AUTOSAR XML (schema 00054)
package /AUTOSAR/Platform/BaseTypes
  7 x base type, all with category=FIXED_LENGTH:
    boolean_bt: base-type-size=8, base-type-encoding=BOOLEAN
    uint8_bt: base-type-size=8, base-type-encoding=NONE
    uint16_bt: base-type-size=16, base-type-encoding=NONE
    uint32_bt: base-type-size=32, base-type-encoding=NONE
    sint8_bt: base-type-size=8, base-type-encoding=2C
    sint16_bt: base-type-size=16, base-type-encoding=2C
    sint32_bt: base-type-size=32, base-type-encoding=2C
package /AUTOSAR/Platform/ImplementationDataTypes
  7 x impl type, all with category=VALUE:
    boolean_T: base-type=boolean_bt
    uint8_T: base-type=uint8_bt
    uint16_T: base-type=uint16_bt
    uint32_T: base-type=uint32_bt
    sint8_T: base-type=sint8_bt
    sint16_T: base-type=sint16_bt
    sint32_T: base-type=sint32_bt
package /Taktflow/System
  system TaktflowSystem: category=SYSTEM_EXTRACT
package /Taktflow/Communication
  can cluster CAN_500k: baudrate=500000, protocol-name=CAN
    can physical channel CAN_Physical: comm-connectors=[CVC_Conn, FZC_Conn, RZC_Conn, SC_Conn, BCM_Conn, ICU_Conn, TCU_Conn, Diag_Conn]
      frame EStop_Broadcast_Frame: id 0x1, frame-length=4, can-addressing-mode=STANDARD, can-frame-rx-behavior=CAN-20, can-frame-tx-behavior=CAN-20
        pdu EStop_Broadcast: length=4, transmission-mode-true-timing=cyclic-timing=time-period=0.01
          signal EStop_Broadcast_E2E_DataID: start 0, 4 bit, little-endian, data-type-policy=OVERRIDE, transfer-property=PENDING
          signal EStop_Broadcast_E2E_AliveCounter: start 4, 4 bit, little-endian, data-type-policy=OVERRIDE, transfer-property=PENDING
          signal EStop_Broadcast_E2E_CRC8: start 8, 8 bit, little-endian, data-type-policy=OVERRIDE, transfer-property=PENDING
          signal EStop_Broadcast_Active: start 16, 8 bit, little-endian, data-type-policy=OVERRIDE, transfer-property=PENDING
          signal EStop_Broadcast_Source: start 24, 8 bit, little-endian, data-type-policy=OVERRIDE, transfer-property=PENDING
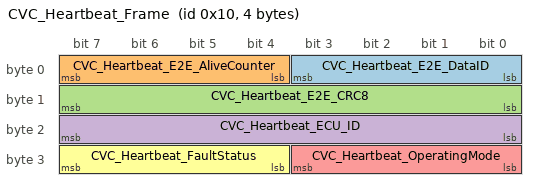
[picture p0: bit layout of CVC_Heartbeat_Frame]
      frame CVC_Heartbeat_Frame: id 0x10, frame-length=4, can-addressing-mode=STANDARD, can-frame-rx-behavior=CAN-20, can-frame-tx-behavior=CAN-20
        pdu CVC_Heartbeat: length=4, transmission-mode-true-timing=cyclic-timing=time-period=0.05
          signal CVC_Heartbeat_E2E_DataID: start 0, 4 bit, little-endian, data-type-policy=OVERRIDE, transfer-property=PENDING
          signal CVC_Heartbeat_E2E_AliveCounter: start 4, 4 bit, little-endian, data-type-policy=OVERRIDE, transfer-property=PENDING
          signal CVC_Heartbeat_E2E_CRC8: start 8, 8 bit, little-endian, data-type-policy=OVERRIDE, transfer-property=PENDING
          signal CVC_Heartbeat_ECU_ID: start 16, 8 bit, little-endian, data-type-policy=OVERRIDE, transfer-property=PENDING
          signal CVC_Heartbeat_OperatingMode: start 24, 4 bit, little-endian, data-type-policy=OVERRIDE, transfer-property=PENDING
          signal CVC_Heartbeat_FaultStatus: start 28, 4 bit, little-endian, data-type-policy=OVERRIDE, transfer-property=PENDING
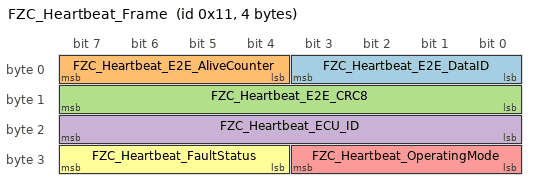
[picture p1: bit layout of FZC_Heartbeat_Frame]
      frame FZC_Heartbeat_Frame: id 0x11, frame-length=4, can-addressing-mode=STANDARD, can-frame-rx-behavior=CAN-20, can-frame-tx-behavior=CAN-20
        pdu FZC_Heartbeat: length=4, transmission-mode-true-timing=cyclic-timing=time-period=0.05
          signal FZC_Heartbeat_E2E_DataID: start 0, 4 bit, little-endian, data-type-policy=OVERRIDE, transfer-property=PENDING
          signal FZC_Heartbeat_E2E_AliveCounter: start 4, 4 bit, little-endian, data-type-policy=OVERRIDE, transfer-property=PENDING
          signal FZC_Heartbeat_E2E_CRC8: start 8, 8 bit, little-endian, data-type-policy=OVERRIDE, transfer-property=PENDING
          signal FZC_Heartbeat_ECU_ID: start 16, 8 bit, little-endian, data-type-policy=OVERRIDE, transfer-property=PENDING
          signal FZC_Heartbeat_OperatingMode: start 24, 4 bit, little-endian, data-type-policy=OVERRIDE, transfer-property=PENDING
          signal FZC_Heartbeat_FaultStatus: start 28, 4 bit, little-endian, data-type-policy=OVERRIDE, transfer-property=PENDING
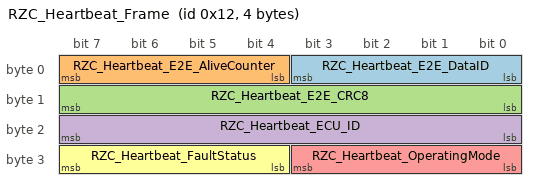
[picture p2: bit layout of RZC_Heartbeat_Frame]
      frame RZC_Heartbeat_Frame: id 0x12, frame-length=4, can-addressing-mode=STANDARD, can-frame-rx-behavior=CAN-20, can-frame-tx-behavior=CAN-20
        pdu RZC_Heartbeat: length=4, transmission-mode-true-timing=cyclic-timing=time-period=0.05
          signal RZC_Heartbeat_E2E_DataID: start 0, 4 bit, little-endian, data-type-policy=OVERRIDE, transfer-property=PENDING
          signal RZC_Heartbeat_E2E_AliveCounter: start 4, 4 bit, little-endian, data-type-policy=OVERRIDE, transfer-property=PENDING
          signal RZC_Heartbeat_E2E_CRC8: start 8, 8 bit, little-endian, data-type-policy=OVERRIDE, transfer-property=PENDING
          signal RZC_Heartbeat_ECU_ID: start 16, 8 bit, little-endian, data-type-policy=OVERRIDE, transfer-property=PENDING
          signal RZC_Heartbeat_OperatingMode: start 24, 4 bit, little-endian, data-type-policy=OVERRIDE, transfer-property=PENDING
          signal RZC_Heartbeat_FaultStatus: start 28, 4 bit, little-endian, data-type-policy=OVERRIDE, transfer-property=PENDING
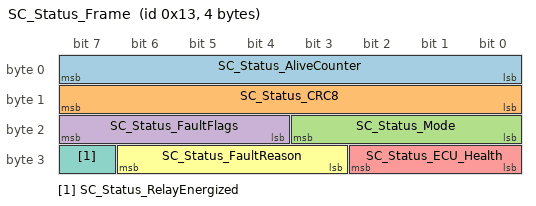
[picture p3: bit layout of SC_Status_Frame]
      frame SC_Status_Frame: id 0x13, frame-length=4, can-addressing-mode=STANDARD, can-frame-rx-behavior=CAN-20, can-frame-tx-behavior=CAN-20
        pdu SC_Status: length=4, transmission-mode-true-timing=cyclic-timing=time-period=0.1
          signal SC_Status_AliveCounter: start 0, 8 bit, little-endian, data-type-policy=OVERRIDE, transfer-property=PENDING
          signal SC_Status_CRC8: start 8, 8 bit, little-endian, data-type-policy=OVERRIDE, transfer-property=PENDING
          signal SC_Status_Mode: start 16, 4 bit, little-endian, data-type-policy=OVERRIDE, transfer-property=PENDING
          signal SC_Status_FaultFlags: start 20, 4 bit, little-endian, data-type-policy=OVERRIDE, transfer-property=PENDING
          signal SC_Status_ECU_Health: start 24, 3 bit, little-endian, data-type-policy=OVERRIDE, transfer-property=PENDING
          signal SC_Status_FaultReason: start 27, 4 bit, little-endian, data-type-policy=OVERRIDE, transfer-property=PENDING
          signal SC_Status_RelayEnergized: start 31, 1 bit, little-endian, data-type-policy=OVERRIDE, transfer-property=PENDING
      frame ICU_Heartbeat_Frame: id 0x14, frame-length=4, can-addressing-mode=STANDARD, can-frame-rx-behavior=CAN-20, can-frame-tx-behavior=CAN-20
        pdu ICU_Heartbeat: length=4, transmission-mode-true-timing=cyclic-timing=time-period=0.5
          signal ICU_Heartbeat_E2E_DataID: start 0, 4 bit, little-endian, data-type-policy=OVERRIDE, transfer-property=PENDING
          signal ICU_Heartbeat_E2E_AliveCounter: start 4, 4 bit, little-endian, data-type-policy=OVERRIDE, transfer-property=PENDING
          signal ICU_Heartbeat_E2E_CRC8: start 8, 8 bit, little-endian, data-type-policy=OVERRIDE, transfer-property=PENDING
          signal ICU_Heartbeat_AliveCounter: start 16, 8 bit, little-endian, data-type-policy=OVERRIDE, transfer-property=PENDING
          signal ICU_Heartbeat_ECU_ID: start 24, 8 bit, little-endian, data-type-policy=OVERRIDE, transfer-property=PENDING
      frame TCU_Heartbeat_Frame: id 0x15, frame-length=4, can-addressing-mode=STANDARD, can-frame-rx-behavior=CAN-20, can-frame-tx-behavior=CAN-20
        pdu TCU_Heartbeat: length=4, transmission-mode-true-timing=cyclic-timing=time-period=0.5
          signal TCU_Heartbeat_E2E_DataID: start 0, 4 bit, little-endian, data-type-policy=OVERRIDE, transfer-property=PENDING
          signal TCU_Heartbeat_E2E_AliveCounter: start 4, 4 bit, little-endian, data-type-policy=OVERRIDE, transfer-property=PENDING
          signal TCU_Heartbeat_E2E_CRC8: start 8, 8 bit, little-endian, data-type-policy=OVERRIDE, transfer-property=PENDING
          signal TCU_Heartbeat_AliveCounter: start 16, 8 bit, little-endian, data-type-policy=OVERRIDE, transfer-property=PENDING
          signal TCU_Heartbeat_ECU_ID: start 24, 8 bit, little-endian, data-type-policy=OVERRIDE, transfer-property=PENDING
      frame BCM_Heartbeat_Frame: id 0x16, frame-length=4, can-addressing-mode=STANDARD, can-frame-rx-behavior=CAN-20, can-frame-tx-behavior=CAN-20
        pdu BCM_Heartbeat: length=4, transmission-mode-true-timing=cyclic-timing=time-period=0.5
          signal BCM_Heartbeat_E2E_DataID: start 0, 4 bit, little-endian, data-type-policy=OVERRIDE, transfer-property=PENDING
          signal BCM_Heartbeat_E2E_AliveCounter: start 4, 4 bit, little-endian, data-type-policy=OVERRIDE, transfer-property=PENDING
          signal BCM_Heartbeat_E2E_CRC8: start 8, 8 bit, little-endian, data-type-policy=OVERRIDE, transfer-property=PENDING
          signal BCM_Heartbeat_AliveCounter: start 16, 8 bit, little-endian, data-type-policy=OVERRIDE, transfer-property=PENDING
          signal BCM_Heartbeat_ECU_ID: start 24, 8 bit, little-endian, data-type-policy=OVERRIDE, transfer-property=PENDING
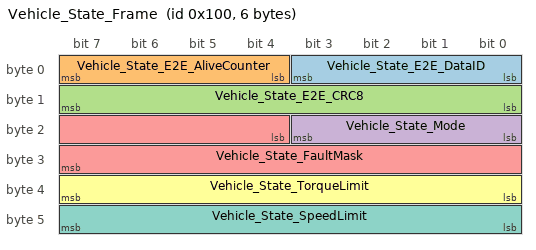
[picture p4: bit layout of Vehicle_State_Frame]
      frame Vehicle_State_Frame: id 0x100, frame-length=6, can-addressing-mode=STANDARD, can-frame-rx-behavior=CAN-20, can-frame-tx-behavior=CAN-20
        pdu Vehicle_State: length=6, transmission-mode-true-timing=cyclic-timing=time-period=0.01
          signal Vehicle_State_E2E_DataID: start 0, 4 bit, little-endian, data-type-policy=OVERRIDE, transfer-property=PENDING
          signal Vehicle_State_E2E_AliveCounter: start 4, 4 bit, little-endian, data-type-policy=OVERRIDE, transfer-property=PENDING
          signal Vehicle_State_E2E_CRC8: start 8, 8 bit, little-endian, data-type-policy=OVERRIDE, transfer-property=PENDING
          signal Vehicle_State_Mode: start 16, 4 bit, little-endian, data-type-policy=OVERRIDE, transfer-property=PENDING
          signal Vehicle_State_FaultMask: start 20, 12 bit, little-endian, data-type-policy=OVERRIDE, transfer-property=PENDING
          signal Vehicle_State_TorqueLimit: start 32, 8 bit, little-endian, data-type-policy=OVERRIDE, transfer-property=PENDING
          signal Vehicle_State_SpeedLimit: start 40, 8 bit, little-endian, data-type-policy=OVERRIDE, transfer-property=PENDING
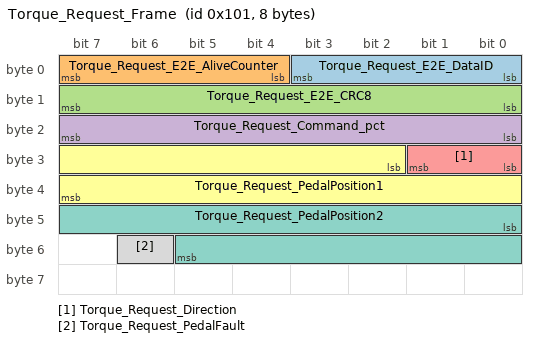
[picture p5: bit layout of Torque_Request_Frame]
      frame Torque_Request_Frame: id 0x101, frame-length=8, can-addressing-mode=STANDARD, can-frame-rx-behavior=CAN-20, can-frame-tx-behavior=CAN-20
        pdu Torque_Request: length=8, transmission-mode-true-timing=cyclic-timing=time-period=0.01
          signal Torque_Request_E2E_DataID: start 0, 4 bit, little-endian, data-type-policy=OVERRIDE, transfer-property=PENDING
          signal Torque_Request_E2E_AliveCounter: start 4, 4 bit, little-endian, data-type-policy=OVERRIDE, transfer-property=PENDING
          signal Torque_Request_E2E_CRC8: start 8, 8 bit, little-endian, data-type-policy=OVERRIDE, transfer-property=PENDING
          signal Torque_Request_Command_pct: start 16, 8 bit, little-endian, data-type-policy=OVERRIDE, transfer-property=PENDING
          signal Torque_Request_Direction: start 24, 2 bit, little-endian, data-type-policy=OVERRIDE, transfer-property=PENDING
          signal Torque_Request_PedalPosition1: start 26, 14 bit, little-endian, data-type-policy=OVERRIDE, transfer-property=PENDING
          signal Torque_Request_PedalPosition2: start 40, 14 bit, little-endian, data-type-policy=OVERRIDE, transfer-property=PENDING
          signal Torque_Request_PedalFault: start 54, 1 bit, little-endian, data-type-policy=OVERRIDE, transfer-property=PENDING
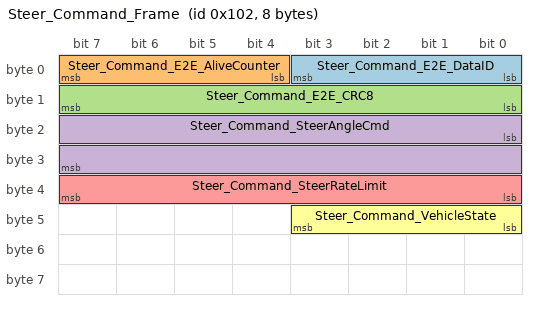
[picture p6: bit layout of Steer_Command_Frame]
      frame Steer_Command_Frame: id 0x102, frame-length=8, can-addressing-mode=STANDARD, can-frame-rx-behavior=CAN-20, can-frame-tx-behavior=CAN-20
        pdu Steer_Command: length=8, transmission-mode-true-timing=cyclic-timing=time-period=0.01
          signal Steer_Command_E2E_DataID: start 0, 4 bit, little-endian, data-type-policy=OVERRIDE, transfer-property=PENDING
          signal Steer_Command_E2E_AliveCounter: start 4, 4 bit, little-endian, data-type-policy=OVERRIDE, transfer-property=PENDING
          signal Steer_Command_E2E_CRC8: start 8, 8 bit, little-endian, data-type-policy=OVERRIDE, transfer-property=PENDING
          signal Steer_Command_SteerAngleCmd: start 16, 16 bit, little-endian, data-type-policy=OVERRIDE, transfer-property=PENDING
          signal Steer_Command_SteerRateLimit: start 32, 8 bit, little-endian, data-type-policy=OVERRIDE, transfer-property=PENDING
          signal Steer_Command_VehicleState: start 40, 4 bit, little-endian, data-type-policy=OVERRIDE, transfer-property=PENDING
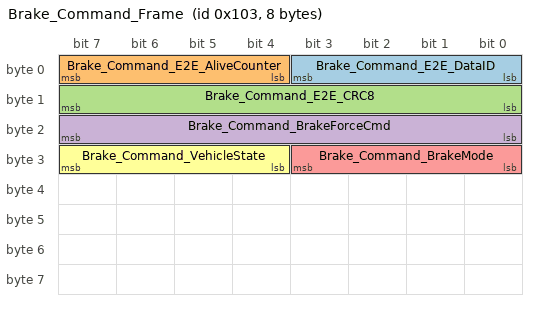
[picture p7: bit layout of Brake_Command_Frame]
      frame Brake_Command_Frame: id 0x103, frame-length=8, can-addressing-mode=STANDARD, can-frame-rx-behavior=CAN-20, can-frame-tx-behavior=CAN-20
        pdu Brake_Command: length=8, transmission-mode-true-timing=cyclic-timing=time-period=0.01
          signal Brake_Command_E2E_DataID: start 0, 4 bit, little-endian, data-type-policy=OVERRIDE, transfer-property=PENDING
          signal Brake_Command_E2E_AliveCounter: start 4, 4 bit, little-endian, data-type-policy=OVERRIDE, transfer-property=PENDING
          signal Brake_Command_E2E_CRC8: start 8, 8 bit, little-endian, data-type-policy=OVERRIDE, transfer-property=PENDING
          signal Brake_Command_BrakeForceCmd: start 16, 8 bit, little-endian, data-type-policy=OVERRIDE, transfer-property=PENDING
          signal Brake_Command_BrakeMode: start 24, 4 bit, little-endian, data-type-policy=OVERRIDE, transfer-property=PENDING
          signal Brake_Command_VehicleState: start 28, 4 bit, little-endian, data-type-policy=OVERRIDE, transfer-property=PENDING
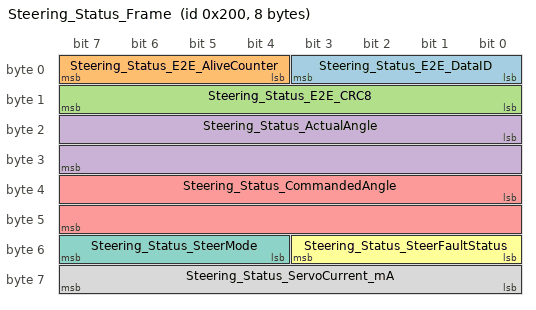
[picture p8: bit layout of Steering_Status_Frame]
      frame Steering_Status_Frame: id 0x200, frame-length=8, can-addressing-mode=STANDARD, can-frame-rx-behavior=CAN-20, can-frame-tx-behavior=CAN-20
        pdu Steering_Status: length=8, transmission-mode-true-timing=cyclic-timing=time-period=0.05
          signal Steering_Status_E2E_DataID: start 0, 4 bit, little-endian, data-type-policy=OVERRIDE, transfer-property=PENDING
          signal Steering_Status_E2E_AliveCounter: start 4, 4 bit, little-endian, data-type-policy=OVERRIDE, transfer-property=PENDING
          signal Steering_Status_E2E_CRC8: start 8, 8 bit, little-endian, data-type-policy=OVERRIDE, transfer-property=PENDING
          signal Steering_Status_ActualAngle: start 16, 16 bit, little-endian, data-type-policy=OVERRIDE, transfer-property=PENDING
          signal Steering_Status_CommandedAngle: start 32, 16 bit, little-endian, data-type-policy=OVERRIDE, transfer-property=PENDING
          signal Steering_Status_SteerFaultStatus: start 48, 4 bit, little-endian, data-type-policy=OVERRIDE, transfer-property=PENDING
          signal Steering_Status_SteerMode: start 52, 4 bit, little-endian, data-type-policy=OVERRIDE, transfer-property=PENDING
          signal Steering_Status_ServoCurrent_mA: start 56, 8 bit, little-endian, data-type-policy=OVERRIDE, transfer-property=PENDING
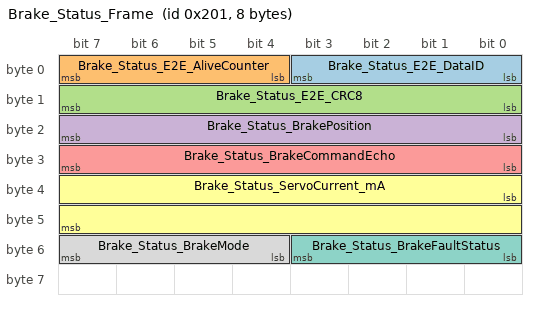
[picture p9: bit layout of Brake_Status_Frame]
      frame Brake_Status_Frame: id 0x201, frame-length=8, can-addressing-mode=STANDARD, can-frame-rx-behavior=CAN-20, can-frame-tx-behavior=CAN-20
        pdu Brake_Status: length=8, transmission-mode-true-timing=cyclic-timing=time-period=0.05
          signal Brake_Status_E2E_DataID: start 0, 4 bit, little-endian, data-type-policy=OVERRIDE, transfer-property=PENDING
          signal Brake_Status_E2E_AliveCounter: start 4, 4 bit, little-endian, data-type-policy=OVERRIDE, transfer-property=PENDING
          signal Brake_Status_E2E_CRC8: start 8, 8 bit, little-endian, data-type-policy=OVERRIDE, transfer-property=PENDING
          signal Brake_Status_BrakePosition: start 16, 8 bit, little-endian, data-type-policy=OVERRIDE, transfer-property=PENDING
          signal Brake_Status_BrakeCommandEcho: start 24, 8 bit, little-endian, data-type-policy=OVERRIDE, transfer-property=PENDING
          signal Brake_Status_ServoCurrent_mA: start 32, 16 bit, little-endian, data-type-policy=OVERRIDE, transfer-property=PENDING
          signal Brake_Status_BrakeFaultStatus: start 48, 4 bit, little-endian, data-type-policy=OVERRIDE, transfer-property=PENDING
          signal Brake_Status_BrakeMode: start 52, 4 bit, little-endian, data-type-policy=OVERRIDE, transfer-property=PENDING
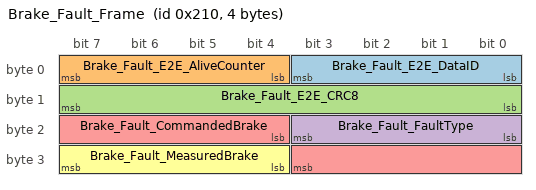
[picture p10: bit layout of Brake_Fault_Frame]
      frame Brake_Fault_Frame: id 0x210, frame-length=4, can-addressing-mode=STANDARD, can-frame-rx-behavior=CAN-20, can-frame-tx-behavior=CAN-20
        pdu Brake_Fault: length=4
          signal Brake_Fault_E2E_DataID: start 0, 4 bit, little-endian, data-type-policy=OVERRIDE, transfer-property=PENDING
          signal Brake_Fault_E2E_AliveCounter: start 4, 4 bit, little-endian, data-type-policy=OVERRIDE, transfer-property=PENDING
          signal Brake_Fault_E2E_CRC8: start 8, 8 bit, little-endian, data-type-policy=OVERRIDE, transfer-property=PENDING
          signal Brake_Fault_FaultType: start 16, 4 bit, little-endian, data-type-policy=OVERRIDE, transfer-property=PENDING
          signal Brake_Fault_CommandedBrake: start 20, 8 bit, little-endian, data-type-policy=OVERRIDE, transfer-property=PENDING
          signal Brake_Fault_MeasuredBrake: start 28, 4 bit, little-endian, data-type-policy=OVERRIDE, transfer-property=PENDING
      frame Motor_Cutoff_Req_Frame: id 0x211, frame-length=4, can-addressing-mode=STANDARD, can-frame-rx-behavior=CAN-20, can-frame-tx-behavior=CAN-20
        pdu Motor_Cutoff_Req: length=4, transmission-mode-true-timing=cyclic-timing=time-period=0.05
          signal Motor_Cutoff_Req_E2E_DataID: start 0, 4 bit, little-endian, data-type-policy=OVERRIDE, transfer-property=PENDING
          signal Motor_Cutoff_Req_E2E_AliveCounter: start 4, 4 bit, little-endian, data-type-policy=OVERRIDE, transfer-property=PENDING
          signal Motor_Cutoff_Req_E2E_CRC8: start 8, 8 bit, little-endian, data-type-policy=OVERRIDE, transfer-property=PENDING
          signal Motor_Cutoff_Req_RequestType: start 16, 4 bit, little-endian, data-type-policy=OVERRIDE, transfer-property=PENDING
          signal Motor_Cutoff_Req_Reason: start 20, 4 bit, little-endian, data-type-policy=OVERRIDE, transfer-property=PENDING
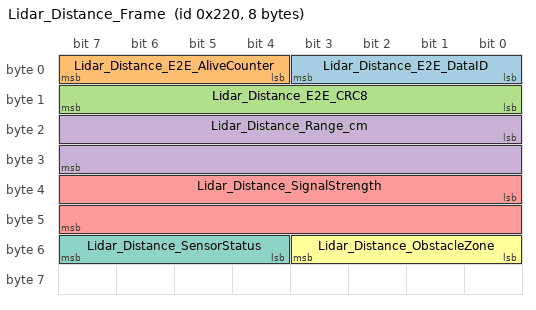
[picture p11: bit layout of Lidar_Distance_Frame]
      frame Lidar_Distance_Frame: id 0x220, frame-length=8, can-addressing-mode=STANDARD, can-frame-rx-behavior=CAN-20, can-frame-tx-behavior=CAN-20
        pdu Lidar_Distance: length=8, transmission-mode-true-timing=cyclic-timing=time-period=0.01
          signal Lidar_Distance_E2E_DataID: start 0, 4 bit, little-endian, data-type-policy=OVERRIDE, transfer-property=PENDING
          signal Lidar_Distance_E2E_AliveCounter: start 4, 4 bit, little-endian, data-type-policy=OVERRIDE, transfer-property=PENDING
          signal Lidar_Distance_E2E_CRC8: start 8, 8 bit, little-endian, data-type-policy=OVERRIDE, transfer-property=PENDING
          signal Lidar_Distance_Range_cm: start 16, 16 bit, little-endian, data-type-policy=OVERRIDE, transfer-property=PENDING
          signal Lidar_Distance_SignalStrength: start 32, 16 bit, little-endian, data-type-policy=OVERRIDE, transfer-property=PENDING
          signal Lidar_Distance_ObstacleZone: start 48, 4 bit, little-endian, data-type-policy=OVERRIDE, transfer-property=PENDING
          signal Lidar_Distance_SensorStatus: start 52, 4 bit, little-endian, data-type-policy=OVERRIDE, transfer-property=PENDING
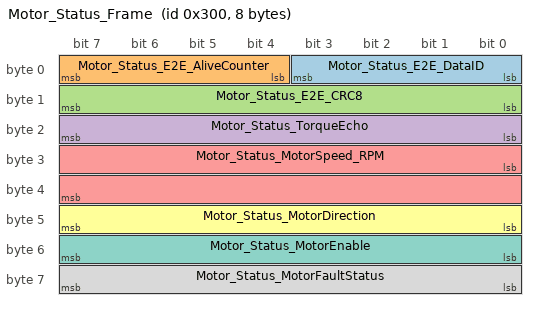
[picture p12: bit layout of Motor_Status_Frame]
      frame Motor_Status_Frame: id 0x300, frame-length=8, can-addressing-mode=STANDARD, can-frame-rx-behavior=CAN-20, can-frame-tx-behavior=CAN-20
        pdu Motor_Status: length=8, transmission-mode-true-timing=cyclic-timing=time-period=0.1
          signal Motor_Status_E2E_DataID: start 0, 4 bit, little-endian, data-type-policy=OVERRIDE, transfer-property=PENDING
          signal Motor_Status_E2E_AliveCounter: start 4, 4 bit, little-endian, data-type-policy=OVERRIDE, transfer-property=PENDING
          signal Motor_Status_E2E_CRC8: start 8, 8 bit, little-endian, data-type-policy=OVERRIDE, transfer-property=PENDING
          signal Motor_Status_TorqueEcho: start 16, 8 bit, little-endian, data-type-policy=OVERRIDE, transfer-property=PENDING
          signal Motor_Status_MotorSpeed_RPM: start 24, 16 bit, little-endian, data-type-policy=OVERRIDE, transfer-property=PENDING
          signal Motor_Status_MotorDirection: start 40, 8 bit, little-endian, data-type-policy=OVERRIDE, transfer-property=PENDING
          signal Motor_Status_MotorEnable: start 48, 8 bit, little-endian, data-type-policy=OVERRIDE, transfer-property=PENDING
          signal Motor_Status_MotorFaultStatus: start 56, 8 bit, little-endian, data-type-policy=OVERRIDE, transfer-property=PENDING
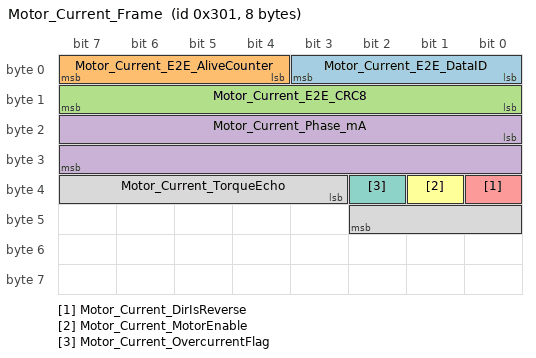
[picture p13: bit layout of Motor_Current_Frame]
      frame Motor_Current_Frame: id 0x301, frame-length=8, can-addressing-mode=STANDARD, can-frame-rx-behavior=CAN-20, can-frame-tx-behavior=CAN-20
        pdu Motor_Current: length=8, transmission-mode-true-timing=cyclic-timing=time-period=0.1
          signal Motor_Current_E2E_DataID: start 0, 4 bit, little-endian, data-type-policy=OVERRIDE, transfer-property=PENDING
          signal Motor_Current_E2E_AliveCounter: start 4, 4 bit, little-endian, data-type-policy=OVERRIDE, transfer-property=PENDING
          signal Motor_Current_E2E_CRC8: start 8, 8 bit, little-endian, data-type-policy=OVERRIDE, transfer-property=PENDING
          signal Motor_Current_Phase_mA: start 16, 16 bit, little-endian, data-type-policy=OVERRIDE, transfer-property=PENDING
          signal Motor_Current_DirIsReverse: start 32, 1 bit, little-endian, data-type-policy=OVERRIDE, transfer-property=PENDING
          signal Motor_Current_MotorEnable: start 33, 1 bit, little-endian, data-type-policy=OVERRIDE, transfer-property=PENDING
          signal Motor_Current_OvercurrentFlag: start 34, 1 bit, little-endian, data-type-policy=OVERRIDE, transfer-property=PENDING
          signal Motor_Current_TorqueEcho: start 35, 8 bit, little-endian, data-type-policy=OVERRIDE, transfer-property=PENDING
      frame Motor_Temperature_Frame: id 0x302, frame-length=8, can-addressing-mode=STANDARD, can-frame-rx-behavior=CAN-20, can-frame-tx-behavior=CAN-20
        pdu Motor_Temperature: length=8, transmission-mode-true-timing=cyclic-timing=time-period=0.1
          signal Motor_Temperature_E2E_DataID: start 0, 4 bit, little-endian, data-type-policy=OVERRIDE, transfer-property=PENDING
          signal Motor_Temperature_E2E_AliveCounter: start 4, 4 bit, little-endian, data-type-policy=OVERRIDE, transfer-property=PENDING
          signal Motor_Temperature_E2E_CRC8: start 8, 8 bit, little-endian, data-type-policy=OVERRIDE, transfer-property=PENDING
          signal Motor_Temperature_WindingTemp1_C: start 16, 16 bit, little-endian, data-type-policy=OVERRIDE, transfer-property=PENDING
          signal Motor_Temperature_WindingTemp2_C: start 32, 16 bit, little-endian, data-type-policy=OVERRIDE, transfer-property=PENDING
          signal Motor_Temperature_DeratingPercent: start 48, 8 bit, little-endian, data-type-policy=OVERRIDE, transfer-property=PENDING
      frame Battery_Status_Frame: id 0x303, frame-length=6, can-addressing-mode=STANDARD, can-frame-rx-behavior=CAN-20, can-frame-tx-behavior=CAN-20
        pdu Battery_Status: length=6, transmission-mode-true-timing=cyclic-timing=time-period=1
          signal Battery_Status_E2E_DataID: start 0, 4 bit, little-endian, data-type-policy=OVERRIDE, transfer-property=PENDING
          signal Battery_Status_E2E_AliveCounter: start 4, 4 bit, little-endian, data-type-policy=OVERRIDE, transfer-property=PENDING
          signal Battery_Status_E2E_CRC8: start 8, 8 bit, little-endian, data-type-policy=OVERRIDE, transfer-property=PENDING
          signal Battery_Status_BatteryVoltage_mV: start 16, 16 bit, little-endian, data-type-policy=OVERRIDE, transfer-property=PENDING
          signal Battery_Status_Level: start 32, 8 bit, little-endian, data-type-policy=OVERRIDE, transfer-property=PENDING
      frame Body_Control_Cmd_Frame: id 0x350, frame-length=4, can-addressing-mode=STANDARD, can-frame-rx-behavior=CAN-20, can-frame-tx-behavior=CAN-20
        pdu Body_Control_Cmd: length=4, transmission-mode-true-timing=cyclic-timing=time-period=0.1
          signal Body_Control_Cmd_HeadlightCmd: start 0, 2 bit, little-endian, data-type-policy=OVERRIDE, transfer-property=PENDING
          signal Body_Control_Cmd_TailLightOn: start 2, 1 bit, little-endian, data-type-policy=OVERRIDE, transfer-property=PENDING
          signal Body_Control_Cmd_HazardActive: start 3, 1 bit, little-endian, data-type-policy=OVERRIDE, transfer-property=PENDING
          signal Body_Control_Cmd_TurnSignalCmd: start 4, 2 bit, little-endian, data-type-policy=OVERRIDE, transfer-property=PENDING
          signal Body_Control_Cmd_DoorLockCmd: start 6, 1 bit, little-endian, data-type-policy=OVERRIDE, transfer-property=PENDING
      frame Light_Status_Frame: id 0x400, frame-length=4, can-addressing-mode=STANDARD, can-frame-rx-behavior=CAN-20, can-frame-tx-behavior=CAN-20
        pdu Light_Status: length=4, transmission-mode-true-timing=cyclic-timing=time-period=0.1
          signal Light_Status_HeadlightOn: start 0, 1 bit, little-endian, data-type-policy=OVERRIDE, transfer-property=PENDING
          signal Light_Status_TailLightOn: start 1, 1 bit, little-endian, data-type-policy=OVERRIDE, transfer-property=PENDING
          signal Light_Status_FogLightOn: start 2, 1 bit, little-endian, data-type-policy=OVERRIDE, transfer-property=PENDING
          signal Light_Status_BrakeLightOn: start 3, 1 bit, little-endian, data-type-policy=OVERRIDE, transfer-property=PENDING
          signal Light_Status_HeadlightLevel: start 4, 2 bit, little-endian, data-type-policy=OVERRIDE, transfer-property=PENDING
      frame Indicator_State_Frame: id 0x401, frame-length=4, can-addressing-mode=STANDARD, can-frame-rx-behavior=CAN-20, can-frame-tx-behavior=CAN-20
        pdu Indicator_State: length=4, transmission-mode-true-timing=cyclic-timing=time-period=0.1
          signal Indicator_State_LeftOn: start 0, 1 bit, little-endian, data-type-policy=OVERRIDE, transfer-property=PENDING
          signal Indicator_State_RightOn: start 1, 1 bit, little-endian, data-type-policy=OVERRIDE, transfer-property=PENDING
          signal Indicator_State_HazardActive: start 2, 1 bit, little-endian, data-type-policy=OVERRIDE, transfer-property=PENDING
          signal Indicator_State_BlinkPhaseHigh: start 3, 1 bit, little-endian, data-type-policy=OVERRIDE, transfer-property=PENDING
      frame Door_Lock_Status_Frame: id 0x402, frame-length=2, can-addressing-mode=STANDARD, can-frame-rx-behavior=CAN-20, can-frame-tx-behavior=CAN-20
        pdu Door_Lock_Status: length=2
          signal Door_Lock_Status_FrontLeftLock: start 0, 1 bit, little-endian, data-type-policy=OVERRIDE, transfer-property=PENDING
          signal Door_Lock_Status_FrontRightLock: start 1, 1 bit, little-endian, data-type-policy=OVERRIDE, transfer-property=PENDING
          signal Door_Lock_Status_RearLeftLock: start 2, 1 bit, little-endian, data-type-policy=OVERRIDE, transfer-property=PENDING
          signal Door_Lock_Status_RearRightLock: start 3, 1 bit, little-endian, data-type-policy=OVERRIDE, transfer-property=PENDING
          signal Door_Lock_Status_CentralLock: start 4, 1 bit, little-endian, data-type-policy=OVERRIDE, transfer-property=PENDING
      frame DTC_Broadcast_Frame: id 0x500, frame-length=8, can-addressing-mode=STANDARD, can-frame-rx-behavior=CAN-20, can-frame-tx-behavior=CAN-20
        pdu DTC_Broadcast: length=8
          signal DTC_Broadcast_Number: start 7, 16 bit, big-endian, data-type-policy=OVERRIDE, transfer-property=PENDING
          signal DTC_Broadcast_Status: start 24, 8 bit, little-endian, data-type-policy=OVERRIDE, transfer-property=PENDING
          signal DTC_Broadcast_ECU_Source: start 32, 8 bit, little-endian, data-type-policy=OVERRIDE, transfer-property=PENDING
          signal DTC_Broadcast_OccurrenceCount: start 40, 8 bit, little-endian, data-type-policy=OVERRIDE, transfer-property=PENDING
          signal DTC_Broadcast_FreezeFrame0: start 48, 8 bit, little-endian, data-type-policy=OVERRIDE, transfer-property=PENDING
          signal DTC_Broadcast_FreezeFrame1: start 56, 8 bit, little-endian, data-type-policy=OVERRIDE, transfer-property=PENDING
      frame FZC_Virtual_Sensors_Frame: id 0x600, frame-length=8, can-addressing-mode=STANDARD, can-frame-rx-behavior=CAN-20, can-frame-tx-behavior=CAN-20
        pdu FZC_Virtual_Sensors: length=8, transmission-mode-true-timing=cyclic-timing=time-period=0.01
          signal FZC_Virtual_Sensors_SteerAngle_Raw: start 0, 16 bit, little-endian, data-type-policy=OVERRIDE, transfer-property=PENDING
          signal FZC_Virtual_Sensors_BrakePos_ADC: start 16, 16 bit, little-endian, data-type-policy=OVERRIDE, transfer-property=PENDING
          signal FZC_Virtual_Sensors_BrakeCurrent_mA: start 32, 16 bit, little-endian, data-type-policy=OVERRIDE, transfer-property=PENDING
      frame RZC_Virtual_Sensors_Frame: id 0x601, frame-length=8, can-addressing-mode=STANDARD, can-frame-rx-behavior=CAN-20, can-frame-tx-behavior=CAN-20
        pdu RZC_Virtual_Sensors: length=8, transmission-mode-true-timing=cyclic-timing=time-period=0.01
          signal RZC_Virtual_Sensors_MotorCurrent_mA: start 0, 16 bit, little-endian, data-type-policy=OVERRIDE, transfer-property=PENDING
          signal RZC_Virtual_Sensors_MotorTemp_dC: start 16, 16 bit, little-endian, data-type-policy=OVERRIDE, transfer-property=PENDING
          signal RZC_Virtual_Sensors_BattVoltage_mV: start 32, 16 bit, little-endian, data-type-policy=OVERRIDE, transfer-property=PENDING
          signal RZC_Virtual_Sensors_MotorSpeed_RPM: start 48, 16 bit, little-endian, data-type-policy=OVERRIDE, transfer-property=PENDING
      frame UDS_Resp_TCU_Frame: id 0x644, frame-length=8, can-addressing-mode=STANDARD, can-frame-rx-behavior=CAN-20, can-frame-tx-behavior=CAN-20
        pdu UDS_Resp_TCU: length=8
          signal UDS_Resp_TCU_UDS_Data: start 0, 64 bit, little-endian, data-type-policy=OVERRIDE, transfer-property=PENDING
      frame UDS_Func_Request_Frame: id 0x7DF, frame-length=8, can-addressing-mode=STANDARD, can-frame-rx-behavior=CAN-20, can-frame-tx-behavior=CAN-20
        pdu UDS_Func_Request: length=8
          signal UDS_Func_Request_UDS_Data: start 0, 64 bit, little-endian, data-type-policy=OVERRIDE, transfer-property=PENDING
      frame UDS_Phys_Req_CVC_Frame: id 0x7E0, frame-length=8, can-addressing-mode=STANDARD, can-frame-rx-behavior=CAN-20, can-frame-tx-behavior=CAN-20
        pdu UDS_Phys_Req_CVC: length=8
          signal UDS_Phys_Req_CVC_UDS_Data: start 0, 64 bit, little-endian, data-type-policy=OVERRIDE, transfer-property=PENDING
      frame UDS_Phys_Req_FZC_Frame: id 0x7E1, frame-length=8, can-addressing-mode=STANDARD, can-frame-rx-behavior=CAN-20, can-frame-tx-behavior=CAN-20
        pdu UDS_Phys_Req_FZC: length=8
          signal UDS_Phys_Req_FZC_UDS_Data: start 0, 64 bit, little-endian, data-type-policy=OVERRIDE, transfer-property=PENDING
      frame UDS_Phys_Req_RZC_Frame: id 0x7E2, frame-length=8, can-addressing-mode=STANDARD, can-frame-rx-behavior=CAN-20, can-frame-tx-behavior=CAN-20
        pdu UDS_Phys_Req_RZC: length=8
          signal UDS_Phys_Req_RZC_UDS_Data: start 0, 64 bit, little-endian, data-type-policy=OVERRIDE, transfer-property=PENDING
      frame UDS_Phys_Req_TCU_Frame: id 0x7E3, frame-length=8, can-addressing-mode=STANDARD, can-frame-rx-behavior=CAN-20, can-frame-tx-behavior=CAN-20
        pdu UDS_Phys_Req_TCU: length=8
          signal UDS_Phys_Req_TCU_UDS_Data: start 0, 64 bit, little-endian, data-type-policy=OVERRIDE, transfer-property=PENDING
      frame UDS_Resp_CVC_Frame: id 0x7E8, frame-length=8, can-addressing-mode=STANDARD, can-frame-rx-behavior=CAN-20, can-frame-tx-behavior=CAN-20
        pdu UDS_Resp_CVC: length=8
          signal UDS_Resp_CVC_UDS_Data: start 0, 64 bit, little-endian, data-type-policy=OVERRIDE, transfer-property=PENDING
      frame UDS_Resp_FZC_Frame: id 0x7E9, frame-length=8, can-addressing-mode=STANDARD, can-frame-rx-behavior=CAN-20, can-frame-tx-behavior=CAN-20
        pdu UDS_Resp_FZC: length=8
          signal UDS_Resp_FZC_UDS_Data: start 0, 64 bit, little-endian, data-type-policy=OVERRIDE, transfer-property=PENDING
      frame UDS_Resp_RZC_Frame: id 0x7EA, frame-length=8, can-addressing-mode=STANDARD, can-frame-rx-behavior=CAN-20, can-frame-tx-behavior=CAN-20
        pdu UDS_Resp_RZC: length=8
          signal UDS_Resp_RZC_UDS_Data: start 0, 64 bit, little-endian, data-type-policy=OVERRIDE, transfer-property=PENDING
      frame XCP_Req_CVC_Frame: id 0x550, frame-length=8, can-addressing-mode=STANDARD, can-frame-rx-behavior=CAN-20, can-frame-tx-behavior=CAN-20
        pdu XCP_Req_CVC: length=8
          signal XCP_Req_CVC_Data: start 0, 64 bit, little-endian, data-type-policy=OVERRIDE, transfer-property=PENDING
      frame XCP_Resp_CVC_Frame: id 0x551, frame-length=8, can-addressing-mode=STANDARD, can-frame-rx-behavior=CAN-20, can-frame-tx-behavior=CAN-20
        pdu XCP_Resp_CVC: length=8
          signal XCP_Resp_CVC_Data: start 0, 64 bit, little-endian, data-type-policy=OVERRIDE, transfer-property=PENDING
      frame XCP_Req_FZC_Frame: id 0x552, frame-length=8, can-addressing-mode=STANDARD, can-frame-rx-behavior=CAN-20, can-frame-tx-behavior=CAN-20
        pdu XCP_Req_FZC: length=8
          signal XCP_Req_FZC_Data: start 0, 64 bit, little-endian, data-type-policy=OVERRIDE, transfer-property=PENDING
      frame XCP_Resp_FZC_Frame: id 0x553, frame-length=8, can-addressing-mode=STANDARD, can-frame-rx-behavior=CAN-20, can-frame-tx-behavior=CAN-20
        pdu XCP_Resp_FZC: length=8
          signal XCP_Resp_FZC_Data: start 0, 64 bit, little-endian, data-type-policy=OVERRIDE, transfer-property=PENDING
      frame XCP_Req_RZC_Frame: id 0x554, frame-length=8, can-addressing-mode=STANDARD, can-frame-rx-behavior=CAN-20, can-frame-tx-behavior=CAN-20
        pdu XCP_Req_RZC: length=8
          signal XCP_Req_RZC_Data: start 0, 64 bit, little-endian, data-type-policy=OVERRIDE, transfer-property=PENDING
      frame XCP_Resp_RZC_Frame: id 0x555, frame-length=8, can-addressing-mode=STANDARD, can-frame-rx-behavior=CAN-20, can-frame-tx-behavior=CAN-20
        pdu XCP_Resp_RZC: length=8
          signal XCP_Resp_RZC_Data: start 0, 64 bit, little-endian, data-type-policy=OVERRIDE, transfer-property=PENDING
      frame XCP_Req_SC_Frame: id 0x556, frame-length=8, can-addressing-mode=STANDARD, can-frame-rx-behavior=CAN-20, can-frame-tx-behavior=CAN-20
        pdu XCP_Req_SC: length=8
          signal XCP_Req_SC_Data: start 0, 64 bit, little-endian, data-type-policy=OVERRIDE, transfer-property=PENDING
      frame XCP_Resp_SC_Frame: id 0x557, frame-length=8, can-addressing-mode=STANDARD, can-frame-rx-behavior=CAN-20, can-frame-tx-behavior=CAN-20
        pdu XCP_Resp_SC: length=8
          signal XCP_Resp_SC_Data: start 0, 64 bit, little-endian, data-type-policy=OVERRIDE, transfer-property=PENDING
package /Taktflow/ECUs
  8 x ecu instance:
    CVC
      can communication controller CVC_CanCtrl
      can communication connector CVC_Conn: comm-controller=CVC_CanCtrl
    FZC
      can communication controller FZC_CanCtrl
      can communication connector FZC_Conn: comm-controller=FZC_CanCtrl
    RZC
      can communication controller RZC_CanCtrl
      can communication connector RZC_Conn: comm-controller=RZC_CanCtrl
    SC
      can communication controller SC_CanCtrl
      can communication connector SC_Conn: comm-controller=SC_CanCtrl
    BCM
      can communication controller BCM_CanCtrl
      can communication connector BCM_Conn: comm-controller=BCM_CanCtrl
    ICU
      can communication controller ICU_CanCtrl
      can communication connector ICU_Conn: comm-controller=ICU_CanCtrl
    TCU
      can communication controller TCU_CanCtrl
      can communication connector TCU_Conn: comm-controller=TCU_CanCtrl
    Diag
      can communication controller Diag_CanCtrl
      can communication connector Diag_Conn: comm-controller=Diag_CanCtrl
package /Taktflow/DataTypes
  compu method CM_EStop_Broadcast_Source: 0=CVC_button, 1=CAN_request, 2=SC_relay
  compu method CM_CVC_Heartbeat_OperatingMode: 0=INIT, 1=RUN, 2=DEGRADED, 3=LIMP, 4=SAFE_STOP, 5=SHUTDOWN
  compu method CM_FZC_Heartbeat_OperatingMode: 0=INIT, 1=RUN, 2=DEGRADED, 3=LIMP, 4=SAFE_STOP, 5=SHUTDOWN
  compu method CM_RZC_Heartbeat_OperatingMode: 0=INIT, 1=RUN, 2=DEGRADED, 3=LIMP, 4=SAFE_STOP, 5=SHUTDOWN
  compu method CM_SC_Status_Mode: 0=INIT, 1=MONITORING, 2=FAULT_DETECTED, 3=SAFE_STOP
  compu method CM_Vehicle_State_Mode: 0=INIT, 1=RUN, 2=DEGRADED, 3=LIMP, 4=SAFE_STOP, 5=SHUTDOWN
  compu method CM_Torque_Request_Direction: 0=stopped, 1=forward, 2=reverse
  compu method CM_Torque_Request_PedalPosition1: phys=raw*0.022 for raw 0..359.98; unit deg
  compu method CM_Torque_Request_PedalPosition2: phys=raw*0.022 for raw 0..359.98; unit deg
  compu method CM_Steer_Command_SteerAngleCmd: phys=raw*0.01 for raw -45..45; unit deg
  compu method CM_Steer_Command_SteerRateLimit: phys=raw*0.2 for raw 0..51; unit deg/s
  compu method CM_Brake_Command_BrakeMode: 0=release, 1=normal, 2=emergency, 3=auto
  compu method CM_Steering_Status_SteerMode: 0=normal, 1=return_center, 2=disabled, 3=local
  compu method CM_Steering_Status_ServoCurrent_mA: phys=raw*10 for raw 0..2550; unit mA
  compu method CM_Brake_Status_BrakeMode: 0=release, 1=normal, 2=auto_brake, 3=emergency
  compu method CM_Brake_Fault_FaultType: 0=PWM_mismatch, 1=servo_stuck, 2=overcurrent, 3=timeout
  compu method CM_Brake_Fault_MeasuredBrake: phys=raw*10 for raw 0..100; unit %
  compu method CM_Motor_Cutoff_Req_RequestType: 0=motor_cutoff, 1=speed_reduce, 2=e_stop_fwd
  compu method CM_Motor_Cutoff_Req_Reason: 0=brake_fault, 1=steer_fault, 2=lidar_emergency, 3=CAN_loss
  compu method CM_Lidar_Distance_ObstacleZone: 0=emergency, 1=braking, 2=warning, 3=clear
  compu method CM_Motor_Status_MotorDirection: 0=stopped, 1=forward, 2=reverse
  compu method CM_Motor_Current_DirIsReverse: 0=forward, 1=reverse
  compu method CM_Motor_Temperature_WindingTemp1_C: phys=raw*0.1 for raw 0..200; unit degC
  compu method CM_Motor_Temperature_WindingTemp2_C: phys=raw*0.1 for raw 0..200; unit degC
  compu method CM_Battery_Status_Level: 0=critical_UV, 1=UV_warn, 2=normal, 3=OV_warn, 4=critical_OV
  compu method CM_Body_Control_Cmd_HeadlightCmd: 0=off, 1=low, 2=high
  compu method CM_Body_Control_Cmd_TurnSignalCmd: 0=off, 1=left, 2=right
  compu method CM_Light_Status_HeadlightLevel: 0=off, 1=low, 2=high
  compu method CM_DTC_Broadcast_ECU_Source: 1=CVC, 2=FZC, 3=RZC, 4=SC, 5=BCM, 6=ICU, 7=TCU
package /Taktflow/Units
  5 x unit:
    Unit_deg: display-name=deg
    Unit_deg_per_s: display-name=deg/s
    Unit_mA: display-name=mA
    Unit_pct: display-name=%
    Unit_degC: display-name=degC
package /Taktflow/Interfaces
  182 x sender receiver interface:
    SRI_EStop_Broadcast_E2E_DataID
      data EStop_Broadcast_E2E_DataID: type=uint8_T
    SRI_EStop_Broadcast_E2E_AliveCounter
      data EStop_Broadcast_E2E_AliveCounter: type=uint8_T
    SRI_EStop_Broadcast_E2E_CRC8
      data EStop_Broadcast_E2E_CRC8: type=uint8_T
    SRI_EStop_Broadcast_Active
      data EStop_Broadcast_Active: type=uint8_T
    SRI_EStop_Broadcast_Source
      data EStop_Broadcast_Source: type=uint8_T
    SRI_CVC_Heartbeat_E2E_DataID
      data CVC_Heartbeat_E2E_DataID: type=uint8_T
    SRI_CVC_Heartbeat_E2E_AliveCounter
      data CVC_Heartbeat_E2E_AliveCounter: type=uint8_T
    SRI_CVC_Heartbeat_E2E_CRC8
      data CVC_Heartbeat_E2E_CRC8: type=uint8_T
    SRI_CVC_Heartbeat_ECU_ID
      data CVC_Heartbeat_ECU_ID: type=uint8_T
    SRI_CVC_Heartbeat_OperatingMode
      data CVC_Heartbeat_OperatingMode: type=uint8_T
    SRI_CVC_Heartbeat_FaultStatus
      data CVC_Heartbeat_FaultStatus: type=uint8_T
    SRI_FZC_Heartbeat_E2E_DataID
      data FZC_Heartbeat_E2E_DataID: type=uint8_T
    SRI_FZC_Heartbeat_E2E_AliveCounter
      data FZC_Heartbeat_E2E_AliveCounter: type=uint8_T
    SRI_FZC_Heartbeat_E2E_CRC8
      data FZC_Heartbeat_E2E_CRC8: type=uint8_T
    SRI_FZC_Heartbeat_ECU_ID
      data FZC_Heartbeat_ECU_ID: type=uint8_T
    SRI_FZC_Heartbeat_OperatingMode
      data FZC_Heartbeat_OperatingMode: type=uint8_T
    SRI_FZC_Heartbeat_FaultStatus
      data FZC_Heartbeat_FaultStatus: type=uint8_T
    SRI_RZC_Heartbeat_E2E_DataID
      data RZC_Heartbeat_E2E_DataID: type=uint8_T
    SRI_RZC_Heartbeat_E2E_AliveCounter
      data RZC_Heartbeat_E2E_AliveCounter: type=uint8_T
    SRI_RZC_Heartbeat_E2E_CRC8
      data RZC_Heartbeat_E2E_CRC8: type=uint8_T
    SRI_RZC_Heartbeat_ECU_ID
      data RZC_Heartbeat_ECU_ID: type=uint8_T
    SRI_RZC_Heartbeat_OperatingMode
      data RZC_Heartbeat_OperatingMode: type=uint8_T
    SRI_RZC_Heartbeat_FaultStatus
      data RZC_Heartbeat_FaultStatus: type=uint8_T
    SRI_SC_Status_AliveCounter
      data SC_Status_AliveCounter: type=uint8_T
    SRI_SC_Status_CRC8
      data SC_Status_CRC8: type=uint8_T
    SRI_SC_Status_Mode
      data SC_Status_Mode: type=uint8_T
    SRI_SC_Status_FaultFlags
      data SC_Status_FaultFlags: type=uint8_T
    SRI_SC_Status_ECU_Health
      data SC_Status_ECU_Health: type=uint8_T
    SRI_SC_Status_FaultReason
      data SC_Status_FaultReason: type=uint8_T
    SRI_SC_Status_RelayEnergized
      data SC_Status_RelayEnergized: type=boolean_T
    SRI_ICU_Heartbeat_E2E_DataID
      data ICU_Heartbeat_E2E_DataID: type=uint8_T
    SRI_ICU_Heartbeat_E2E_AliveCounter
      data ICU_Heartbeat_E2E_AliveCounter: type=uint8_T
    SRI_ICU_Heartbeat_E2E_CRC8
      data ICU_Heartbeat_E2E_CRC8: type=uint8_T
    SRI_ICU_Heartbeat_AliveCounter
      data ICU_Heartbeat_AliveCounter: type=uint8_T
    SRI_ICU_Heartbeat_ECU_ID
      data ICU_Heartbeat_ECU_ID: type=uint8_T
    SRI_TCU_Heartbeat_E2E_DataID
      data TCU_Heartbeat_E2E_DataID: type=uint8_T
    SRI_TCU_Heartbeat_E2E_AliveCounter
      data TCU_Heartbeat_E2E_AliveCounter: type=uint8_T
    SRI_TCU_Heartbeat_E2E_CRC8
      data TCU_Heartbeat_E2E_CRC8: type=uint8_T
    SRI_TCU_Heartbeat_AliveCounter
      data TCU_Heartbeat_AliveCounter: type=uint8_T
    SRI_TCU_Heartbeat_ECU_ID
      data TCU_Heartbeat_ECU_ID: type=uint8_T
    SRI_BCM_Heartbeat_E2E_DataID
      data BCM_Heartbeat_E2E_DataID: type=uint8_T
    SRI_BCM_Heartbeat_E2E_AliveCounter
      data BCM_Heartbeat_E2E_AliveCounter: type=uint8_T
    SRI_BCM_Heartbeat_E2E_CRC8
      data BCM_Heartbeat_E2E_CRC8: type=uint8_T
    SRI_BCM_Heartbeat_AliveCounter
      data BCM_Heartbeat_AliveCounter: type=uint8_T
    SRI_BCM_Heartbeat_ECU_ID
      data BCM_Heartbeat_ECU_ID: type=uint8_T
    SRI_Vehicle_State_E2E_DataID
      data Vehicle_State_E2E_DataID: type=uint8_T
    SRI_Vehicle_State_E2E_AliveCounter
      data Vehicle_State_E2E_AliveCounter: type=uint8_T
    SRI_Vehicle_State_E2E_CRC8
      data Vehicle_State_E2E_CRC8: type=uint8_T
    SRI_Vehicle_State_Mode
      data Vehicle_State_Mode: type=uint8_T
    SRI_Vehicle_State_FaultMask
      data Vehicle_State_FaultMask: type=uint16_T
    SRI_Vehicle_State_TorqueLimit
      data Vehicle_State_TorqueLimit: type=uint8_T
    SRI_Vehicle_State_SpeedLimit
      data Vehicle_State_SpeedLimit: type=uint8_T
    SRI_Torque_Request_E2E_DataID
      data Torque_Request_E2E_DataID: type=uint8_T
    SRI_Torque_Request_E2E_AliveCounter
      data Torque_Request_E2E_AliveCounter: type=uint8_T
    SRI_Torque_Request_E2E_CRC8
      data Torque_Request_E2E_CRC8: type=uint8_T
    SRI_Torque_Request_Command_pct
      data Torque_Request_Command_pct: type=uint8_T
    SRI_Torque_Request_Direction
      data Torque_Request_Direction: type=uint8_T
    SRI_Torque_Request_PedalPosition1
      data Torque_Request_PedalPosition1: type=uint16_T
    SRI_Torque_Request_PedalPosition2
      data Torque_Request_PedalPosition2: type=uint16_T
    SRI_Torque_Request_PedalFault
      data Torque_Request_PedalFault: type=boolean_T
    SRI_Steer_Command_E2E_DataID
      data Steer_Command_E2E_DataID: type=uint8_T
    SRI_Steer_Command_E2E_AliveCounter
      data Steer_Command_E2E_AliveCounter: type=uint8_T
    SRI_Steer_Command_E2E_CRC8
      data Steer_Command_E2E_CRC8: type=uint8_T
    SRI_Steer_Command_SteerAngleCmd
      data Steer_Command_SteerAngleCmd: type=sint16_T
    SRI_Steer_Command_SteerRateLimit
      data Steer_Command_SteerRateLimit: type=uint8_T
    SRI_Steer_Command_VehicleState
      data Steer_Command_VehicleState: type=uint8_T
    SRI_Brake_Command_E2E_DataID
      data Brake_Command_E2E_DataID: type=uint8_T
    SRI_Brake_Command_E2E_AliveCounter
      data Brake_Command_E2E_AliveCounter: type=uint8_T
    SRI_Brake_Command_E2E_CRC8
      data Brake_Command_E2E_CRC8: type=uint8_T
    SRI_Brake_Command_BrakeForceCmd
      data Brake_Command_BrakeForceCmd: type=uint8_T
    SRI_Brake_Command_BrakeMode
      data Brake_Command_BrakeMode: type=uint8_T
    SRI_Brake_Command_VehicleState
      data Brake_Command_VehicleState: type=uint8_T
    SRI_Steering_Status_E2E_DataID
      data Steering_Status_E2E_DataID: type=uint8_T
    SRI_Steering_Status_E2E_AliveCounter
      data Steering_Status_E2E_AliveCounter: type=uint8_T
    SRI_Steering_Status_E2E_CRC8
      data Steering_Status_E2E_CRC8: type=uint8_T
    SRI_Steering_Status_ActualAngle
      data Steering_Status_ActualAngle: type=sint16_T
    SRI_Steering_Status_CommandedAngle
      data Steering_Status_CommandedAngle: type=sint16_T
    SRI_Steering_Status_SteerFaultStatus
      data Steering_Status_SteerFaultStatus: type=uint8_T
    SRI_Steering_Status_SteerMode
      data Steering_Status_SteerMode: type=uint8_T
    SRI_Steering_Status_ServoCurrent_mA
      data Steering_Status_ServoCurrent_mA: type=uint8_T
    SRI_Brake_Status_E2E_DataID
      data Brake_Status_E2E_DataID: type=uint8_T
    SRI_Brake_Status_E2E_AliveCounter
      data Brake_Status_E2E_AliveCounter: type=uint8_T
    SRI_Brake_Status_E2E_CRC8
      data Brake_Status_E2E_CRC8: type=uint8_T
    SRI_Brake_Status_BrakePosition
      data Brake_Status_BrakePosition: type=uint8_T
    SRI_Brake_Status_BrakeCommandEcho
      data Brake_Status_BrakeCommandEcho: type=uint8_T
    SRI_Brake_Status_ServoCurrent_mA
      data Brake_Status_ServoCurrent_mA: type=uint16_T
    SRI_Brake_Status_BrakeFaultStatus
      data Brake_Status_BrakeFaultStatus: type=uint8_T
    SRI_Brake_Status_BrakeMode
      data Brake_Status_BrakeMode: type=uint8_T
    SRI_Brake_Fault_E2E_DataID
      data Brake_Fault_E2E_DataID: type=uint8_T
    SRI_Brake_Fault_E2E_AliveCounter
      data Brake_Fault_E2E_AliveCounter: type=uint8_T
    SRI_Brake_Fault_E2E_CRC8
      data Brake_Fault_E2E_CRC8: type=uint8_T
    SRI_Brake_Fault_FaultType
      data Brake_Fault_FaultType: type=uint8_T
    SRI_Brake_Fault_CommandedBrake
      data Brake_Fault_CommandedBrake: type=uint8_T
    SRI_Brake_Fault_MeasuredBrake
      data Brake_Fault_MeasuredBrake: type=uint8_T
    SRI_Motor_Cutoff_Req_E2E_DataID
      data Motor_Cutoff_Req_E2E_DataID: type=uint8_T
    SRI_Motor_Cutoff_Req_E2E_AliveCounter
      data Motor_Cutoff_Req_E2E_AliveCounter: type=uint8_T
    SRI_Motor_Cutoff_Req_E2E_CRC8
      data Motor_Cutoff_Req_E2E_CRC8: type=uint8_T
    SRI_Motor_Cutoff_Req_RequestType
      data Motor_Cutoff_Req_RequestType: type=uint8_T
    SRI_Motor_Cutoff_Req_Reason
      data Motor_Cutoff_Req_Reason: type=uint8_T
    SRI_Lidar_Distance_E2E_DataID
      data Lidar_Distance_E2E_DataID: type=uint8_T
    SRI_Lidar_Distance_E2E_AliveCounter
      data Lidar_Distance_E2E_AliveCounter: type=uint8_T
    SRI_Lidar_Distance_E2E_CRC8
      data Lidar_Distance_E2E_CRC8: type=uint8_T
    SRI_Lidar_Distance_Range_cm
      data Lidar_Distance_Range_cm: type=uint16_T
    SRI_Lidar_Distance_SignalStrength
      data Lidar_Distance_SignalStrength: type=uint16_T
    SRI_Lidar_Distance_ObstacleZone
      data Lidar_Distance_ObstacleZone: type=uint8_T
    SRI_Lidar_Distance_SensorStatus
      data Lidar_Distance_SensorStatus: type=uint8_T
    SRI_Motor_Status_E2E_DataID
      data Motor_Status_E2E_DataID: type=uint8_T
    SRI_Motor_Status_E2E_AliveCounter
      data Motor_Status_E2E_AliveCounter: type=uint8_T
    SRI_Motor_Status_E2E_CRC8
      data Motor_Status_E2E_CRC8: type=uint8_T
    SRI_Motor_Status_TorqueEcho
      data Motor_Status_TorqueEcho: type=uint8_T
    SRI_Motor_Status_MotorSpeed_RPM
      data Motor_Status_MotorSpeed_RPM: type=uint16_T
    SRI_Motor_Status_MotorDirection
      data Motor_Status_MotorDirection: type=uint8_T
    SRI_Motor_Status_MotorEnable
      data Motor_Status_MotorEnable: type=uint8_T
    SRI_Motor_Status_MotorFaultStatus
      data Motor_Status_MotorFaultStatus: type=uint8_T
    SRI_Motor_Current_E2E_DataID
      data Motor_Current_E2E_DataID: type=uint8_T
    SRI_Motor_Current_E2E_AliveCounter
      data Motor_Current_E2E_AliveCounter: type=uint8_T
    SRI_Motor_Current_E2E_CRC8
      data Motor_Current_E2E_CRC8: type=uint8_T
    SRI_Motor_Current_Phase_mA
      data Motor_Current_Phase_mA: type=uint16_T
    SRI_Motor_Current_DirIsReverse
      data Motor_Current_DirIsReverse: type=boolean_T
    SRI_Motor_Current_MotorEnable
      data Motor_Current_MotorEnable: type=boolean_T
    SRI_Motor_Current_OvercurrentFlag
      data Motor_Current_OvercurrentFlag: type=boolean_T
    SRI_Motor_Current_TorqueEcho
      data Motor_Current_TorqueEcho: type=uint8_T
    SRI_Motor_Temperature_E2E_DataID
      data Motor_Temperature_E2E_DataID: type=uint8_T
    SRI_Motor_Temperature_E2E_AliveCounter
      data Motor_Temperature_E2E_AliveCounter: type=uint8_T
    SRI_Motor_Temperature_E2E_CRC8
      data Motor_Temperature_E2E_CRC8: type=uint8_T
    SRI_Motor_Temperature_WindingTemp1_C
      data Motor_Temperature_WindingTemp1_C: type=uint16_T
    SRI_Motor_Temperature_WindingTemp2_C
      data Motor_Temperature_WindingTemp2_C: type=uint16_T
    SRI_Motor_Temperature_DeratingPercent
      data Motor_Temperature_DeratingPercent: type=uint8_T
    SRI_Battery_Status_E2E_DataID
      data Battery_Status_E2E_DataID: type=uint8_T
    SRI_Battery_Status_E2E_AliveCounter
      data Battery_Status_E2E_AliveCounter: type=uint8_T
    SRI_Battery_Status_E2E_CRC8
      data Battery_Status_E2E_CRC8: type=uint8_T
    SRI_Battery_Status_BatteryVoltage_mV
      data Battery_Status_BatteryVoltage_mV: type=uint16_T
    SRI_Battery_Status_Level
      data Battery_Status_Level: type=uint8_T
    SRI_Body_Control_Cmd_HeadlightCmd
      data Body_Control_Cmd_HeadlightCmd: type=uint8_T
    SRI_Body_Control_Cmd_TailLightOn
      data Body_Control_Cmd_TailLightOn: type=boolean_T
    SRI_Body_Control_Cmd_HazardActive
      data Body_Control_Cmd_HazardActive: type=boolean_T
    SRI_Body_Control_Cmd_TurnSignalCmd
      data Body_Control_Cmd_TurnSignalCmd: type=uint8_T
    SRI_Body_Control_Cmd_DoorLockCmd
      data Body_Control_Cmd_DoorLockCmd: type=boolean_T
    SRI_Light_Status_HeadlightOn
      data Light_Status_HeadlightOn: type=boolean_T
    SRI_Light_Status_TailLightOn
      data Light_Status_TailLightOn: type=boolean_T
    SRI_Light_Status_FogLightOn
      data Light_Status_FogLightOn: type=boolean_T
    SRI_Light_Status_BrakeLightOn
      data Light_Status_BrakeLightOn: type=boolean_T
    SRI_Light_Status_HeadlightLevel
      data Light_Status_HeadlightLevel: type=uint8_T
    SRI_Indicator_State_LeftOn
      data Indicator_State_LeftOn: type=boolean_T
    SRI_Indicator_State_RightOn
      data Indicator_State_RightOn: type=boolean_T
    SRI_Indicator_State_HazardActive
      data Indicator_State_HazardActive: type=boolean_T
    SRI_Indicator_State_BlinkPhaseHigh
      data Indicator_State_BlinkPhaseHigh: type=boolean_T
    SRI_Door_Lock_Status_FrontLeftLock
      data Door_Lock_Status_FrontLeftLock: type=boolean_T
    SRI_Door_Lock_Status_FrontRightLock
      data Door_Lock_Status_FrontRightLock: type=boolean_T
    SRI_Door_Lock_Status_RearLeftLock
      data Door_Lock_Status_RearLeftLock: type=boolean_T
    SRI_Door_Lock_Status_RearRightLock
      data Door_Lock_Status_RearRightLock: type=boolean_T
    SRI_Door_Lock_Status_CentralLock
      data Door_Lock_Status_CentralLock: type=boolean_T
    SRI_DTC_Broadcast_Number
      data DTC_Broadcast_Number: type=uint16_T
    SRI_DTC_Broadcast_Status
      data DTC_Broadcast_Status: type=uint8_T
    SRI_DTC_Broadcast_ECU_Source
      data DTC_Broadcast_ECU_Source: type=uint8_T
    SRI_DTC_Broadcast_OccurrenceCount
      data DTC_Broadcast_OccurrenceCount: type=uint8_T
    SRI_DTC_Broadcast_FreezeFrame0
      data DTC_Broadcast_FreezeFrame0: type=uint8_T
    SRI_DTC_Broadcast_FreezeFrame1
      data DTC_Broadcast_FreezeFrame1: type=uint8_T
    SRI_FZC_Virtual_Sensors_SteerAngle_Raw
      data FZC_Virtual_Sensors_SteerAngle_Raw: type=uint16_T
    SRI_FZC_Virtual_Sensors_BrakePos_ADC
      data FZC_Virtual_Sensors_BrakePos_ADC: type=uint16_T
    SRI_FZC_Virtual_Sensors_BrakeCurrent_mA
      data FZC_Virtual_Sensors_BrakeCurrent_mA: type=uint16_T
    SRI_RZC_Virtual_Sensors_MotorCurrent_mA
      data RZC_Virtual_Sensors_MotorCurrent_mA: type=uint16_T
    SRI_RZC_Virtual_Sensors_MotorTemp_dC
      data RZC_Virtual_Sensors_MotorTemp_dC: type=uint16_T
    SRI_RZC_Virtual_Sensors_BattVoltage_mV
      data RZC_Virtual_Sensors_BattVoltage_mV: type=uint16_T
    SRI_RZC_Virtual_Sensors_MotorSpeed_RPM
      data RZC_Virtual_Sensors_MotorSpeed_RPM: type=uint16_T
    SRI_UDS_Resp_TCU_UDS_Data
      data UDS_Resp_TCU_UDS_Data: type=uint32_T
    SRI_UDS_Func_Request_UDS_Data
      data UDS_Func_Request_UDS_Data: type=uint32_T
    SRI_UDS_Phys_Req_CVC_UDS_Data
      data UDS_Phys_Req_CVC_UDS_Data: type=uint32_T
    SRI_UDS_Phys_Req_FZC_UDS_Data
      data UDS_Phys_Req_FZC_UDS_Data: type=uint32_T
    SRI_UDS_Phys_Req_RZC_UDS_Data
      data UDS_Phys_Req_RZC_UDS_Data: type=uint32_T
    SRI_UDS_Phys_Req_TCU_UDS_Data
      data UDS_Phys_Req_TCU_UDS_Data: type=uint32_T
    SRI_UDS_Resp_CVC_UDS_Data
      data UDS_Resp_CVC_UDS_Data: type=uint32_T
    SRI_UDS_Resp_FZC_UDS_Data
      data UDS_Resp_FZC_UDS_Data: type=uint32_T
    SRI_UDS_Resp_RZC_UDS_Data
      data UDS_Resp_RZC_UDS_Data: type=uint32_T
    SRI_XCP_Req_CVC_Data
      data XCP_Req_CVC_Data: type=uint32_T
    SRI_XCP_Resp_CVC_Data
      data XCP_Resp_CVC_Data: type=uint32_T
    SRI_XCP_Req_FZC_Data
      data XCP_Req_FZC_Data: type=uint32_T
    SRI_XCP_Resp_FZC_Data
      data XCP_Resp_FZC_Data: type=uint32_T
    SRI_XCP_Req_RZC_Data
      data XCP_Req_RZC_Data: type=uint32_T
    SRI_XCP_Resp_RZC_Data
      data XCP_Resp_RZC_Data: type=uint32_T
    SRI_XCP_Req_SC_Data
      data XCP_Req_SC_Data: type=uint32_T
    SRI_XCP_Resp_SC_Data
      data XCP_Resp_SC_Data: type=uint32_T
package /Taktflow/E2E
  end to end protection set E2E_ProtectionSet_P01
    20 x end to end protection, all with category=E2E_PROFILE_01:
      E2E_EStop_Broadcast: end-to-end-profile={category=PROFILE_01, data-ids=1, data-id-mode=0, data-length=32, max-delta-counter-init=2, crc-offset=8, counter-offset=4, max-no-new-or-repeated-data=3, sync-counter-init=0, data-id-nibble-offset=0}
      E2E_CVC_Heartbeat: end-to-end-profile={category=PROFILE_01, data-ids=2, data-id-mode=0, data-length=32, max-delta-counter-init=2, crc-offset=8, counter-offset=4, max-no-new-or-repeated-data=3, sync-counter-init=0, data-id-nibble-offset=0}
      E2E_FZC_Heartbeat: end-to-end-profile={category=PROFILE_01, data-ids=3, data-id-mode=0, data-length=32, max-delta-counter-init=2, crc-offset=8, counter-offset=4, max-no-new-or-repeated-data=3, sync-counter-init=0, data-id-nibble-offset=0}
      E2E_RZC_Heartbeat: end-to-end-profile={category=PROFILE_01, data-ids=4, data-id-mode=0, data-length=32, max-delta-counter-init=2, crc-offset=8, counter-offset=4, max-no-new-or-repeated-data=3, sync-counter-init=0, data-id-nibble-offset=0}
      E2E_ICU_Heartbeat: end-to-end-profile={category=PROFILE_01, data-ids=0, data-id-mode=0, data-length=32, max-delta-counter-init=2, crc-offset=8, counter-offset=4, max-no-new-or-repeated-data=3, sync-counter-init=0, data-id-nibble-offset=0}
      E2E_TCU_Heartbeat: end-to-end-profile={category=PROFILE_01, data-ids=0, data-id-mode=0, data-length=32, max-delta-counter-init=2, crc-offset=8, counter-offset=4, max-no-new-or-repeated-data=3, sync-counter-init=0, data-id-nibble-offset=0}
      E2E_BCM_Heartbeat: end-to-end-profile={category=PROFILE_01, data-ids=0, data-id-mode=0, data-length=32, max-delta-counter-init=2, crc-offset=8, counter-offset=4, max-no-new-or-repeated-data=3, sync-counter-init=0, data-id-nibble-offset=0}
      E2E_Vehicle_State: end-to-end-profile={category=PROFILE_01, data-ids=5, data-id-mode=0, data-length=48, max-delta-counter-init=1, crc-offset=8, counter-offset=4, max-no-new-or-repeated-data=2, sync-counter-init=0, data-id-nibble-offset=0}
      E2E_Torque_Request: end-to-end-profile={category=PROFILE_01, data-ids=6, data-id-mode=0, data-length=64, max-delta-counter-init=1, crc-offset=8, counter-offset=4, max-no-new-or-repeated-data=2, sync-counter-init=0, data-id-nibble-offset=0}
      E2E_Steer_Command: end-to-end-profile={category=PROFILE_01, data-ids=7, data-id-mode=0, data-length=64, max-delta-counter-init=2, crc-offset=8, counter-offset=4, max-no-new-or-repeated-data=3, sync-counter-init=0, data-id-nibble-offset=0}
      E2E_Brake_Command: end-to-end-profile={category=PROFILE_01, data-ids=8, data-id-mode=0, data-length=64, max-delta-counter-init=2, crc-offset=8, counter-offset=4, max-no-new-or-repeated-data=3, sync-counter-init=0, data-id-nibble-offset=0}
      E2E_Steering_Status: end-to-end-profile={category=PROFILE_01, data-ids=9, data-id-mode=0, data-length=64, max-delta-counter-init=2, crc-offset=8, counter-offset=4, max-no-new-or-repeated-data=3, sync-counter-init=0, data-id-nibble-offset=0}
      E2E_Brake_Status: end-to-end-profile={category=PROFILE_01, data-ids=10, data-id-mode=0, data-length=64, max-delta-counter-init=2, crc-offset=8, counter-offset=4, max-no-new-or-repeated-data=3, sync-counter-init=0, data-id-nibble-offset=0}
      E2E_Brake_Fault: end-to-end-profile={category=PROFILE_01, data-ids=11, data-id-mode=0, data-length=32, max-delta-counter-init=2, crc-offset=8, counter-offset=4, max-no-new-or-repeated-data=3, sync-counter-init=0, data-id-nibble-offset=0}
      E2E_Motor_Cutoff_Req: end-to-end-profile={category=PROFILE_01, data-ids=12, data-id-mode=0, data-length=32, max-delta-counter-init=1, crc-offset=8, counter-offset=4, max-no-new-or-repeated-data=2, sync-counter-init=0, data-id-nibble-offset=0}
      E2E_Lidar_Distance: end-to-end-profile={category=PROFILE_01, data-ids=13, data-id-mode=0, data-length=64, max-delta-counter-init=2, crc-offset=8, counter-offset=4, max-no-new-or-repeated-data=3, sync-counter-init=0, data-id-nibble-offset=0}
      E2E_Motor_Status: end-to-end-profile={category=PROFILE_01, data-ids=14, data-id-mode=0, data-length=64, max-delta-counter-init=2, crc-offset=8, counter-offset=4, max-no-new-or-repeated-data=3, sync-counter-init=0, data-id-nibble-offset=0}
      E2E_Motor_Current: end-to-end-profile={category=PROFILE_01, data-ids=15, data-id-mode=0, data-length=64, max-delta-counter-init=2, crc-offset=8, counter-offset=4, max-no-new-or-repeated-data=3, sync-counter-init=0, data-id-nibble-offset=0}
      E2E_Motor_Temperature: end-to-end-profile={category=PROFILE_01, data-ids=0, data-id-mode=0, data-length=64, max-delta-counter-init=2, crc-offset=8, counter-offset=4, max-no-new-or-repeated-data=3, sync-counter-init=0, data-id-nibble-offset=0}
      E2E_Battery_Status: end-to-end-profile={category=PROFILE_01, data-ids=0, data-id-mode=0, data-length=48, max-delta-counter-init=2, crc-offset=8, counter-offset=4, max-no-new-or-repeated-data=3, sync-counter-init=0, data-id-nibble-offset=0}
package /Taktflow/SWCs/BCM
  application sw component type BCM_Swc_BcmCan
    behavior BCM_Swc_BcmCan_IB
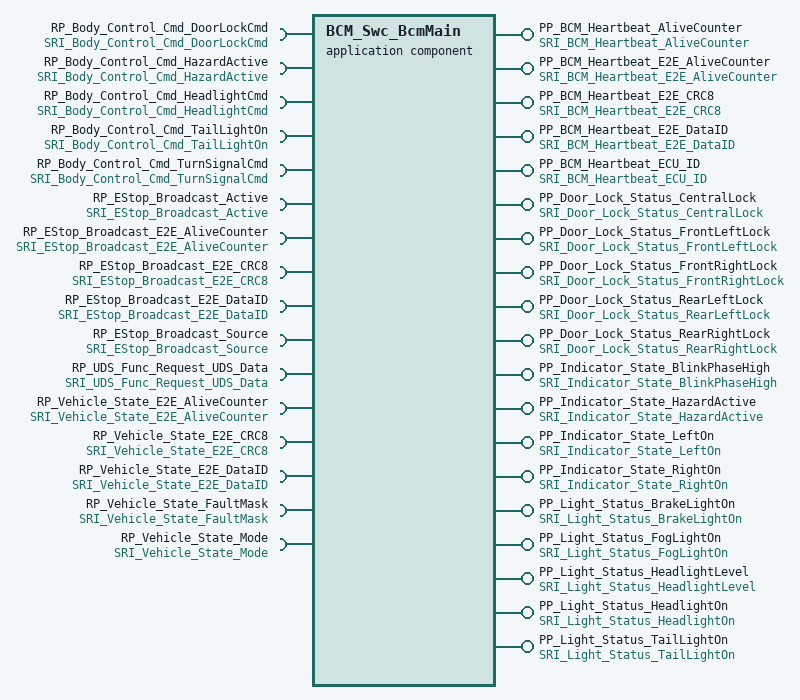
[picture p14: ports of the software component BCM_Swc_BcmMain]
  application sw component type BCM_Swc_BcmMain
    19 x provide port:
      PP_BCM_Heartbeat_AliveCounter: provided-interface=SRI_BCM_Heartbeat_AliveCounter
      PP_BCM_Heartbeat_E2E_AliveCounter: provided-interface=SRI_BCM_Heartbeat_E2E_AliveCounter
      PP_BCM_Heartbeat_E2E_CRC8: provided-interface=SRI_BCM_Heartbeat_E2E_CRC8
      PP_BCM_Heartbeat_E2E_DataID: provided-interface=SRI_BCM_Heartbeat_E2E_DataID
      PP_BCM_Heartbeat_ECU_ID: provided-interface=SRI_BCM_Heartbeat_ECU_ID
      PP_Door_Lock_Status_CentralLock: provided-interface=SRI_Door_Lock_Status_CentralLock
      PP_Door_Lock_Status_FrontLeftLock: provided-interface=SRI_Door_Lock_Status_FrontLeftLock
      PP_Door_Lock_Status_FrontRightLock: provided-interface=SRI_Door_Lock_Status_FrontRightLock
      PP_Door_Lock_Status_RearLeftLock: provided-interface=SRI_Door_Lock_Status_RearLeftLock
      PP_Door_Lock_Status_RearRightLock: provided-interface=SRI_Door_Lock_Status_RearRightLock
      PP_Indicator_State_BlinkPhaseHigh: provided-interface=SRI_Indicator_State_BlinkPhaseHigh
      PP_Indicator_State_HazardActive: provided-interface=SRI_Indicator_State_HazardActive
      PP_Indicator_State_LeftOn: provided-interface=SRI_Indicator_State_LeftOn
      PP_Indicator_State_RightOn: provided-interface=SRI_Indicator_State_RightOn
      PP_Light_Status_BrakeLightOn: provided-interface=SRI_Light_Status_BrakeLightOn
      PP_Light_Status_FogLightOn: provided-interface=SRI_Light_Status_FogLightOn
      PP_Light_Status_HeadlightLevel: provided-interface=SRI_Light_Status_HeadlightLevel
      PP_Light_Status_HeadlightOn: provided-interface=SRI_Light_Status_HeadlightOn
      PP_Light_Status_TailLightOn: provided-interface=SRI_Light_Status_TailLightOn
    16 x require port:
      RP_Body_Control_Cmd_DoorLockCmd: required-interface=SRI_Body_Control_Cmd_DoorLockCmd
      RP_Body_Control_Cmd_HazardActive: required-interface=SRI_Body_Control_Cmd_HazardActive
      RP_Body_Control_Cmd_HeadlightCmd: required-interface=SRI_Body_Control_Cmd_HeadlightCmd
      RP_Body_Control_Cmd_TailLightOn: required-interface=SRI_Body_Control_Cmd_TailLightOn
      RP_Body_Control_Cmd_TurnSignalCmd: required-interface=SRI_Body_Control_Cmd_TurnSignalCmd
      RP_EStop_Broadcast_Active: required-interface=SRI_EStop_Broadcast_Active
      RP_EStop_Broadcast_E2E_AliveCounter: required-interface=SRI_EStop_Broadcast_E2E_AliveCounter
      RP_EStop_Broadcast_E2E_CRC8: required-interface=SRI_EStop_Broadcast_E2E_CRC8
      RP_EStop_Broadcast_E2E_DataID: required-interface=SRI_EStop_Broadcast_E2E_DataID
      RP_EStop_Broadcast_Source: required-interface=SRI_EStop_Broadcast_Source
      RP_UDS_Func_Request_UDS_Data: required-interface=SRI_UDS_Func_Request_UDS_Data
      RP_Vehicle_State_E2E_AliveCounter: required-interface=SRI_Vehicle_State_E2E_AliveCounter
      RP_Vehicle_State_E2E_CRC8: required-interface=SRI_Vehicle_State_E2E_CRC8
      RP_Vehicle_State_E2E_DataID: required-interface=SRI_Vehicle_State_E2E_DataID
      RP_Vehicle_State_FaultMask: required-interface=SRI_Vehicle_State_FaultMask
      RP_Vehicle_State_Mode: required-interface=SRI_Vehicle_State_Mode
    behavior BCM_Swc_BcmMain_IB
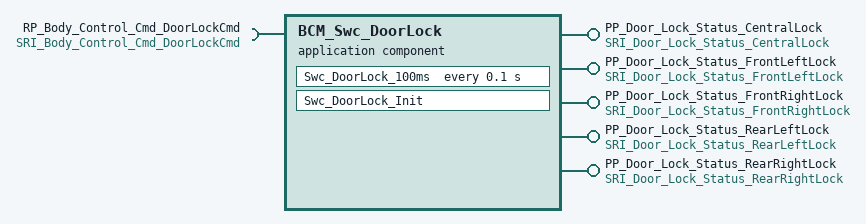
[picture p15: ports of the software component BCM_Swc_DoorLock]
  application sw component type BCM_Swc_DoorLock
    5 x provide port:
      PP_Door_Lock_Status_CentralLock: provided-interface=SRI_Door_Lock_Status_CentralLock
      PP_Door_Lock_Status_FrontLeftLock: provided-interface=SRI_Door_Lock_Status_FrontLeftLock
      PP_Door_Lock_Status_FrontRightLock: provided-interface=SRI_Door_Lock_Status_FrontRightLock
      PP_Door_Lock_Status_RearLeftLock: provided-interface=SRI_Door_Lock_Status_RearLeftLock
      PP_Door_Lock_Status_RearRightLock: provided-interface=SRI_Door_Lock_Status_RearRightLock
    require port RP_Body_Control_Cmd_DoorLockCmd: required-interface=SRI_Body_Control_Cmd_DoorLockCmd
    behavior BCM_Swc_DoorLock_IB
      timing event TE_Swc_DoorLock_100ms_100ms: start-on-event=Swc_DoorLock_100ms, period=0.1
      init event IE_Swc_DoorLock_Init: start-on-event=Swc_DoorLock_Init
      runnable Swc_DoorLock_100ms
      runnable Swc_DoorLock_Init
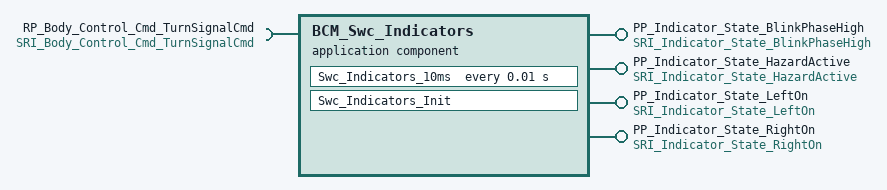
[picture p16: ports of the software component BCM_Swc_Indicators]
  application sw component type BCM_Swc_Indicators
    4 x provide port:
      PP_Indicator_State_BlinkPhaseHigh: provided-interface=SRI_Indicator_State_BlinkPhaseHigh
      PP_Indicator_State_HazardActive: provided-interface=SRI_Indicator_State_HazardActive
      PP_Indicator_State_LeftOn: provided-interface=SRI_Indicator_State_LeftOn
      PP_Indicator_State_RightOn: provided-interface=SRI_Indicator_State_RightOn
    require port RP_Body_Control_Cmd_TurnSignalCmd: required-interface=SRI_Body_Control_Cmd_TurnSignalCmd
    behavior BCM_Swc_Indicators_IB
      timing event TE_Swc_Indicators_10ms_10ms: start-on-event=Swc_Indicators_10ms, period=0.01
      init event IE_Swc_Indicators_Init: start-on-event=Swc_Indicators_Init
      runnable Swc_Indicators_10ms
      runnable Swc_Indicators_Init
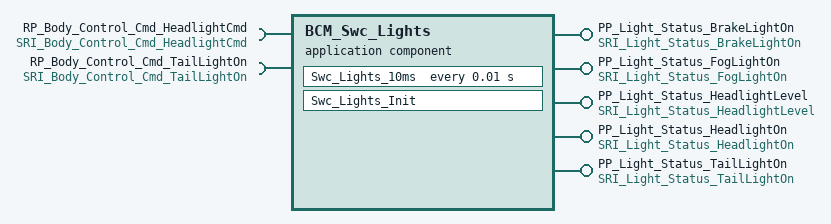
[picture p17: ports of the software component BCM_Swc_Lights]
  application sw component type BCM_Swc_Lights
    5 x provide port:
      PP_Light_Status_BrakeLightOn: provided-interface=SRI_Light_Status_BrakeLightOn
      PP_Light_Status_FogLightOn: provided-interface=SRI_Light_Status_FogLightOn
      PP_Light_Status_HeadlightLevel: provided-interface=SRI_Light_Status_HeadlightLevel
      PP_Light_Status_HeadlightOn: provided-interface=SRI_Light_Status_HeadlightOn
      PP_Light_Status_TailLightOn: provided-interface=SRI_Light_Status_TailLightOn
    require port RP_Body_Control_Cmd_HeadlightCmd: required-interface=SRI_Body_Control_Cmd_HeadlightCmd
    require port RP_Body_Control_Cmd_TailLightOn: required-interface=SRI_Body_Control_Cmd_TailLightOn
    behavior BCM_Swc_Lights_IB
      timing event TE_Swc_Lights_10ms_10ms: start-on-event=Swc_Lights_10ms, period=0.01
      init event IE_Swc_Lights_Init: start-on-event=Swc_Lights_Init
      runnable Swc_Lights_10ms
      runnable Swc_Lights_Init
package /Taktflow/SWCs/CVC
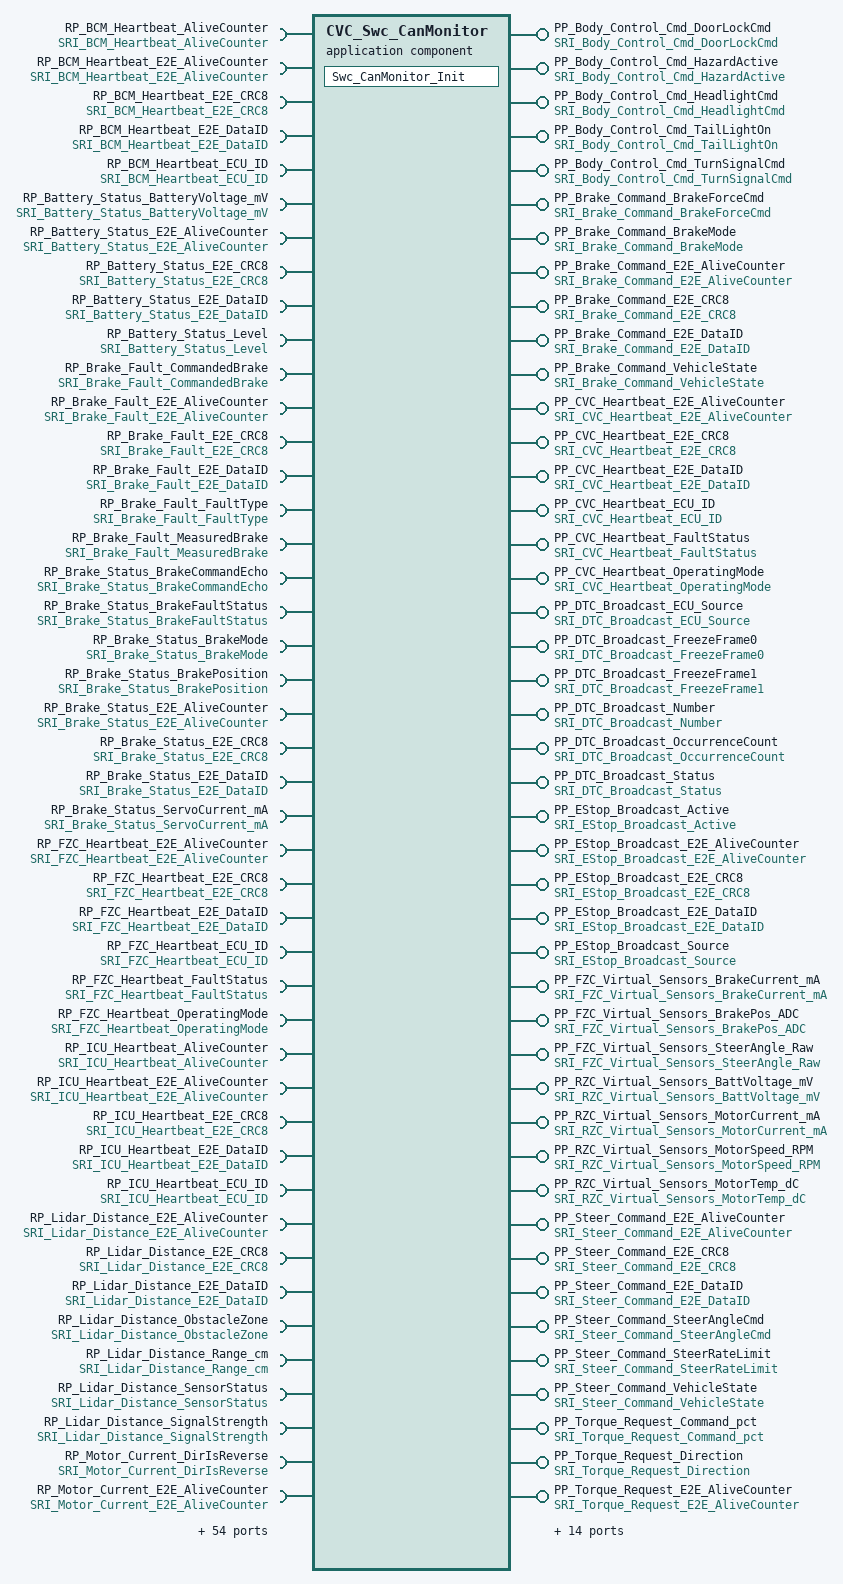
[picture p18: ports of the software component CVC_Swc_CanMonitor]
  application sw component type CVC_Swc_CanMonitor
    58 x provide port:
      PP_Body_Control_Cmd_DoorLockCmd: provided-interface=SRI_Body_Control_Cmd_DoorLockCmd
      PP_Body_Control_Cmd_HazardActive: provided-interface=SRI_Body_Control_Cmd_HazardActive
      PP_Body_Control_Cmd_HeadlightCmd: provided-interface=SRI_Body_Control_Cmd_HeadlightCmd
      PP_Body_Control_Cmd_TailLightOn: provided-interface=SRI_Body_Control_Cmd_TailLightOn
      PP_Body_Control_Cmd_TurnSignalCmd: provided-interface=SRI_Body_Control_Cmd_TurnSignalCmd
      PP_Brake_Command_BrakeForceCmd: provided-interface=SRI_Brake_Command_BrakeForceCmd
      PP_Brake_Command_BrakeMode: provided-interface=SRI_Brake_Command_BrakeMode
      PP_Brake_Command_E2E_AliveCounter: provided-interface=SRI_Brake_Command_E2E_AliveCounter
      PP_Brake_Command_E2E_CRC8: provided-interface=SRI_Brake_Command_E2E_CRC8
      PP_Brake_Command_E2E_DataID: provided-interface=SRI_Brake_Command_E2E_DataID
      PP_Brake_Command_VehicleState: provided-interface=SRI_Brake_Command_VehicleState
      PP_CVC_Heartbeat_E2E_AliveCounter: provided-interface=SRI_CVC_Heartbeat_E2E_AliveCounter
      PP_CVC_Heartbeat_E2E_CRC8: provided-interface=SRI_CVC_Heartbeat_E2E_CRC8
      PP_CVC_Heartbeat_E2E_DataID: provided-interface=SRI_CVC_Heartbeat_E2E_DataID
      PP_CVC_Heartbeat_ECU_ID: provided-interface=SRI_CVC_Heartbeat_ECU_ID
      PP_CVC_Heartbeat_FaultStatus: provided-interface=SRI_CVC_Heartbeat_FaultStatus
      PP_CVC_Heartbeat_OperatingMode: provided-interface=SRI_CVC_Heartbeat_OperatingMode
      PP_DTC_Broadcast_ECU_Source: provided-interface=SRI_DTC_Broadcast_ECU_Source
      PP_DTC_Broadcast_FreezeFrame0: provided-interface=SRI_DTC_Broadcast_FreezeFrame0
      PP_DTC_Broadcast_FreezeFrame1: provided-interface=SRI_DTC_Broadcast_FreezeFrame1
      PP_DTC_Broadcast_Number: provided-interface=SRI_DTC_Broadcast_Number
      PP_DTC_Broadcast_OccurrenceCount: provided-interface=SRI_DTC_Broadcast_OccurrenceCount
      PP_DTC_Broadcast_Status: provided-interface=SRI_DTC_Broadcast_Status
      PP_EStop_Broadcast_Active: provided-interface=SRI_EStop_Broadcast_Active
      PP_EStop_Broadcast_E2E_AliveCounter: provided-interface=SRI_EStop_Broadcast_E2E_AliveCounter
      PP_EStop_Broadcast_E2E_CRC8: provided-interface=SRI_EStop_Broadcast_E2E_CRC8
      PP_EStop_Broadcast_E2E_DataID: provided-interface=SRI_EStop_Broadcast_E2E_DataID
      PP_EStop_Broadcast_Source: provided-interface=SRI_EStop_Broadcast_Source
      PP_FZC_Virtual_Sensors_BrakeCurrent_mA: provided-interface=SRI_FZC_Virtual_Sensors_BrakeCurrent_mA
      PP_FZC_Virtual_Sensors_BrakePos_ADC: provided-interface=SRI_FZC_Virtual_Sensors_BrakePos_ADC
      PP_FZC_Virtual_Sensors_SteerAngle_Raw: provided-interface=SRI_FZC_Virtual_Sensors_SteerAngle_Raw
      PP_RZC_Virtual_Sensors_BattVoltage_mV: provided-interface=SRI_RZC_Virtual_Sensors_BattVoltage_mV
      PP_RZC_Virtual_Sensors_MotorCurrent_mA: provided-interface=SRI_RZC_Virtual_Sensors_MotorCurrent_mA
      PP_RZC_Virtual_Sensors_MotorSpeed_RPM: provided-interface=SRI_RZC_Virtual_Sensors_MotorSpeed_RPM
      PP_RZC_Virtual_Sensors_MotorTemp_dC: provided-interface=SRI_RZC_Virtual_Sensors_MotorTemp_dC
      PP_Steer_Command_E2E_AliveCounter: provided-interface=SRI_Steer_Command_E2E_AliveCounter
      PP_Steer_Command_E2E_CRC8: provided-interface=SRI_Steer_Command_E2E_CRC8
      PP_Steer_Command_E2E_DataID: provided-interface=SRI_Steer_Command_E2E_DataID
      PP_Steer_Command_SteerAngleCmd: provided-interface=SRI_Steer_Command_SteerAngleCmd
      PP_Steer_Command_SteerRateLimit: provided-interface=SRI_Steer_Command_SteerRateLimit
      PP_Steer_Command_VehicleState: provided-interface=SRI_Steer_Command_VehicleState
      PP_Torque_Request_Command_pct: provided-interface=SRI_Torque_Request_Command_pct
      PP_Torque_Request_Direction: provided-interface=SRI_Torque_Request_Direction
      PP_Torque_Request_E2E_AliveCounter: provided-interface=SRI_Torque_Request_E2E_AliveCounter
      PP_Torque_Request_E2E_CRC8: provided-interface=SRI_Torque_Request_E2E_CRC8
      PP_Torque_Request_E2E_DataID: provided-interface=SRI_Torque_Request_E2E_DataID
      PP_Torque_Request_PedalFault: provided-interface=SRI_Torque_Request_PedalFault
      PP_Torque_Request_PedalPosition1: provided-interface=SRI_Torque_Request_PedalPosition1
      PP_Torque_Request_PedalPosition2: provided-interface=SRI_Torque_Request_PedalPosition2
      PP_UDS_Resp_CVC_UDS_Data: provided-interface=SRI_UDS_Resp_CVC_UDS_Data
      PP_Vehicle_State_E2E_AliveCounter: provided-interface=SRI_Vehicle_State_E2E_AliveCounter
      PP_Vehicle_State_E2E_CRC8: provided-interface=SRI_Vehicle_State_E2E_CRC8
      PP_Vehicle_State_E2E_DataID: provided-interface=SRI_Vehicle_State_E2E_DataID
      PP_Vehicle_State_FaultMask: provided-interface=SRI_Vehicle_State_FaultMask
      PP_Vehicle_State_Mode: provided-interface=SRI_Vehicle_State_Mode
      PP_Vehicle_State_SpeedLimit: provided-interface=SRI_Vehicle_State_SpeedLimit
      PP_Vehicle_State_TorqueLimit: provided-interface=SRI_Vehicle_State_TorqueLimit
      PP_XCP_Resp_CVC_Data: provided-interface=SRI_XCP_Resp_CVC_Data
    98 x require port:
      RP_BCM_Heartbeat_AliveCounter: required-interface=SRI_BCM_Heartbeat_AliveCounter
      RP_BCM_Heartbeat_E2E_AliveCounter: required-interface=SRI_BCM_Heartbeat_E2E_AliveCounter
      RP_BCM_Heartbeat_E2E_CRC8: required-interface=SRI_BCM_Heartbeat_E2E_CRC8
      RP_BCM_Heartbeat_E2E_DataID: required-interface=SRI_BCM_Heartbeat_E2E_DataID
      RP_BCM_Heartbeat_ECU_ID: required-interface=SRI_BCM_Heartbeat_ECU_ID
      RP_Battery_Status_BatteryVoltage_mV: required-interface=SRI_Battery_Status_BatteryVoltage_mV
      RP_Battery_Status_E2E_AliveCounter: required-interface=SRI_Battery_Status_E2E_AliveCounter
      RP_Battery_Status_E2E_CRC8: required-interface=SRI_Battery_Status_E2E_CRC8
      RP_Battery_Status_E2E_DataID: required-interface=SRI_Battery_Status_E2E_DataID
      RP_Battery_Status_Level: required-interface=SRI_Battery_Status_Level
      RP_Brake_Fault_CommandedBrake: required-interface=SRI_Brake_Fault_CommandedBrake
      RP_Brake_Fault_E2E_AliveCounter: required-interface=SRI_Brake_Fault_E2E_AliveCounter
      RP_Brake_Fault_E2E_CRC8: required-interface=SRI_Brake_Fault_E2E_CRC8
      RP_Brake_Fault_E2E_DataID: required-interface=SRI_Brake_Fault_E2E_DataID
      RP_Brake_Fault_FaultType: required-interface=SRI_Brake_Fault_FaultType
      RP_Brake_Fault_MeasuredBrake: required-interface=SRI_Brake_Fault_MeasuredBrake
      RP_Brake_Status_BrakeCommandEcho: required-interface=SRI_Brake_Status_BrakeCommandEcho
      RP_Brake_Status_BrakeFaultStatus: required-interface=SRI_Brake_Status_BrakeFaultStatus
      RP_Brake_Status_BrakeMode: required-interface=SRI_Brake_Status_BrakeMode
      RP_Brake_Status_BrakePosition: required-interface=SRI_Brake_Status_BrakePosition
      RP_Brake_Status_E2E_AliveCounter: required-interface=SRI_Brake_Status_E2E_AliveCounter
      RP_Brake_Status_E2E_CRC8: required-interface=SRI_Brake_Status_E2E_CRC8
      RP_Brake_Status_E2E_DataID: required-interface=SRI_Brake_Status_E2E_DataID
      RP_Brake_Status_ServoCurrent_mA: required-interface=SRI_Brake_Status_ServoCurrent_mA
      RP_FZC_Heartbeat_E2E_AliveCounter: required-interface=SRI_FZC_Heartbeat_E2E_AliveCounter
      RP_FZC_Heartbeat_E2E_CRC8: required-interface=SRI_FZC_Heartbeat_E2E_CRC8
      RP_FZC_Heartbeat_E2E_DataID: required-interface=SRI_FZC_Heartbeat_E2E_DataID
      RP_FZC_Heartbeat_ECU_ID: required-interface=SRI_FZC_Heartbeat_ECU_ID
      RP_FZC_Heartbeat_FaultStatus: required-interface=SRI_FZC_Heartbeat_FaultStatus
      RP_FZC_Heartbeat_OperatingMode: required-interface=SRI_FZC_Heartbeat_OperatingMode
      RP_ICU_Heartbeat_AliveCounter: required-interface=SRI_ICU_Heartbeat_AliveCounter
      RP_ICU_Heartbeat_E2E_AliveCounter: required-interface=SRI_ICU_Heartbeat_E2E_AliveCounter
      RP_ICU_Heartbeat_E2E_CRC8: required-interface=SRI_ICU_Heartbeat_E2E_CRC8
      RP_ICU_Heartbeat_E2E_DataID: required-interface=SRI_ICU_Heartbeat_E2E_DataID
      RP_ICU_Heartbeat_ECU_ID: required-interface=SRI_ICU_Heartbeat_ECU_ID
      RP_Lidar_Distance_E2E_AliveCounter: required-interface=SRI_Lidar_Distance_E2E_AliveCounter
      RP_Lidar_Distance_E2E_CRC8: required-interface=SRI_Lidar_Distance_E2E_CRC8
      RP_Lidar_Distance_E2E_DataID: required-interface=SRI_Lidar_Distance_E2E_DataID
      RP_Lidar_Distance_ObstacleZone: required-interface=SRI_Lidar_Distance_ObstacleZone
      RP_Lidar_Distance_Range_cm: required-interface=SRI_Lidar_Distance_Range_cm
      RP_Lidar_Distance_SensorStatus: required-interface=SRI_Lidar_Distance_SensorStatus
      RP_Lidar_Distance_SignalStrength: required-interface=SRI_Lidar_Distance_SignalStrength
      RP_Motor_Current_DirIsReverse: required-interface=SRI_Motor_Current_DirIsReverse
      RP_Motor_Current_E2E_AliveCounter: required-interface=SRI_Motor_Current_E2E_AliveCounter
      RP_Motor_Current_E2E_CRC8: required-interface=SRI_Motor_Current_E2E_CRC8
      RP_Motor_Current_E2E_DataID: required-interface=SRI_Motor_Current_E2E_DataID
      RP_Motor_Current_MotorEnable: required-interface=SRI_Motor_Current_MotorEnable
      RP_Motor_Current_OvercurrentFlag: required-interface=SRI_Motor_Current_OvercurrentFlag
      RP_Motor_Current_Phase_mA: required-interface=SRI_Motor_Current_Phase_mA
      RP_Motor_Current_TorqueEcho: required-interface=SRI_Motor_Current_TorqueEcho
      RP_Motor_Cutoff_Req_E2E_AliveCounter: required-interface=SRI_Motor_Cutoff_Req_E2E_AliveCounter
      RP_Motor_Cutoff_Req_E2E_CRC8: required-interface=SRI_Motor_Cutoff_Req_E2E_CRC8
      RP_Motor_Cutoff_Req_E2E_DataID: required-interface=SRI_Motor_Cutoff_Req_E2E_DataID
      RP_Motor_Cutoff_Req_Reason: required-interface=SRI_Motor_Cutoff_Req_Reason
      RP_Motor_Cutoff_Req_RequestType: required-interface=SRI_Motor_Cutoff_Req_RequestType
      RP_Motor_Status_E2E_AliveCounter: required-interface=SRI_Motor_Status_E2E_AliveCounter
      RP_Motor_Status_E2E_CRC8: required-interface=SRI_Motor_Status_E2E_CRC8
      RP_Motor_Status_E2E_DataID: required-interface=SRI_Motor_Status_E2E_DataID
      RP_Motor_Status_MotorDirection: required-interface=SRI_Motor_Status_MotorDirection
      RP_Motor_Status_MotorEnable: required-interface=SRI_Motor_Status_MotorEnable
      RP_Motor_Status_MotorFaultStatus: required-interface=SRI_Motor_Status_MotorFaultStatus
      RP_Motor_Status_MotorSpeed_RPM: required-interface=SRI_Motor_Status_MotorSpeed_RPM
      RP_Motor_Status_TorqueEcho: required-interface=SRI_Motor_Status_TorqueEcho
      RP_Motor_Temperature_DeratingPercent: required-interface=SRI_Motor_Temperature_DeratingPercent
      RP_Motor_Temperature_E2E_AliveCounter: required-interface=SRI_Motor_Temperature_E2E_AliveCounter
      RP_Motor_Temperature_E2E_CRC8: required-interface=SRI_Motor_Temperature_E2E_CRC8
      RP_Motor_Temperature_E2E_DataID: required-interface=SRI_Motor_Temperature_E2E_DataID
      RP_Motor_Temperature_WindingTemp1_C: required-interface=SRI_Motor_Temperature_WindingTemp1_C
      RP_Motor_Temperature_WindingTemp2_C: required-interface=SRI_Motor_Temperature_WindingTemp2_C
      RP_RZC_Heartbeat_E2E_AliveCounter: required-interface=SRI_RZC_Heartbeat_E2E_AliveCounter
      RP_RZC_Heartbeat_E2E_CRC8: required-interface=SRI_RZC_Heartbeat_E2E_CRC8
      RP_RZC_Heartbeat_E2E_DataID: required-interface=SRI_RZC_Heartbeat_E2E_DataID
      RP_RZC_Heartbeat_ECU_ID: required-interface=SRI_RZC_Heartbeat_ECU_ID
      RP_RZC_Heartbeat_FaultStatus: required-interface=SRI_RZC_Heartbeat_FaultStatus
      RP_RZC_Heartbeat_OperatingMode: required-interface=SRI_RZC_Heartbeat_OperatingMode
      RP_SC_Status_AliveCounter: required-interface=SRI_SC_Status_AliveCounter
      RP_SC_Status_CRC8: required-interface=SRI_SC_Status_CRC8
      RP_SC_Status_ECU_Health: required-interface=SRI_SC_Status_ECU_Health
      RP_SC_Status_FaultFlags: required-interface=SRI_SC_Status_FaultFlags
      RP_SC_Status_FaultReason: required-interface=SRI_SC_Status_FaultReason
      RP_SC_Status_Mode: required-interface=SRI_SC_Status_Mode
      RP_SC_Status_RelayEnergized: required-interface=SRI_SC_Status_RelayEnergized
      RP_Steering_Status_ActualAngle: required-interface=SRI_Steering_Status_ActualAngle
      RP_Steering_Status_CommandedAngle: required-interface=SRI_Steering_Status_CommandedAngle
      RP_Steering_Status_E2E_AliveCounter: required-interface=SRI_Steering_Status_E2E_AliveCounter
      RP_Steering_Status_E2E_CRC8: required-interface=SRI_Steering_Status_E2E_CRC8
      RP_Steering_Status_E2E_DataID: required-interface=SRI_Steering_Status_E2E_DataID
      RP_Steering_Status_ServoCurrent_mA: required-interface=SRI_Steering_Status_ServoCurrent_mA
      RP_Steering_Status_SteerFaultStatus: required-interface=SRI_Steering_Status_SteerFaultStatus
      RP_Steering_Status_SteerMode: required-interface=SRI_Steering_Status_SteerMode
      RP_TCU_Heartbeat_AliveCounter: required-interface=SRI_TCU_Heartbeat_AliveCounter
      RP_TCU_Heartbeat_E2E_AliveCounter: required-interface=SRI_TCU_Heartbeat_E2E_AliveCounter
      RP_TCU_Heartbeat_E2E_CRC8: required-interface=SRI_TCU_Heartbeat_E2E_CRC8
      RP_TCU_Heartbeat_E2E_DataID: required-interface=SRI_TCU_Heartbeat_E2E_DataID
      RP_TCU_Heartbeat_ECU_ID: required-interface=SRI_TCU_Heartbeat_ECU_ID
      RP_UDS_Func_Request_UDS_Data: required-interface=SRI_UDS_Func_Request_UDS_Data
      RP_UDS_Phys_Req_CVC_UDS_Data: required-interface=SRI_UDS_Phys_Req_CVC_UDS_Data
      RP_XCP_Req_CVC_Data: required-interface=SRI_XCP_Req_CVC_Data
    behavior CVC_Swc_CanMonitor_IB
      init event IE_Swc_CanMonitor_Init: start-on-event=Swc_CanMonitor_Init
      runnable Swc_CanMonitor_Init
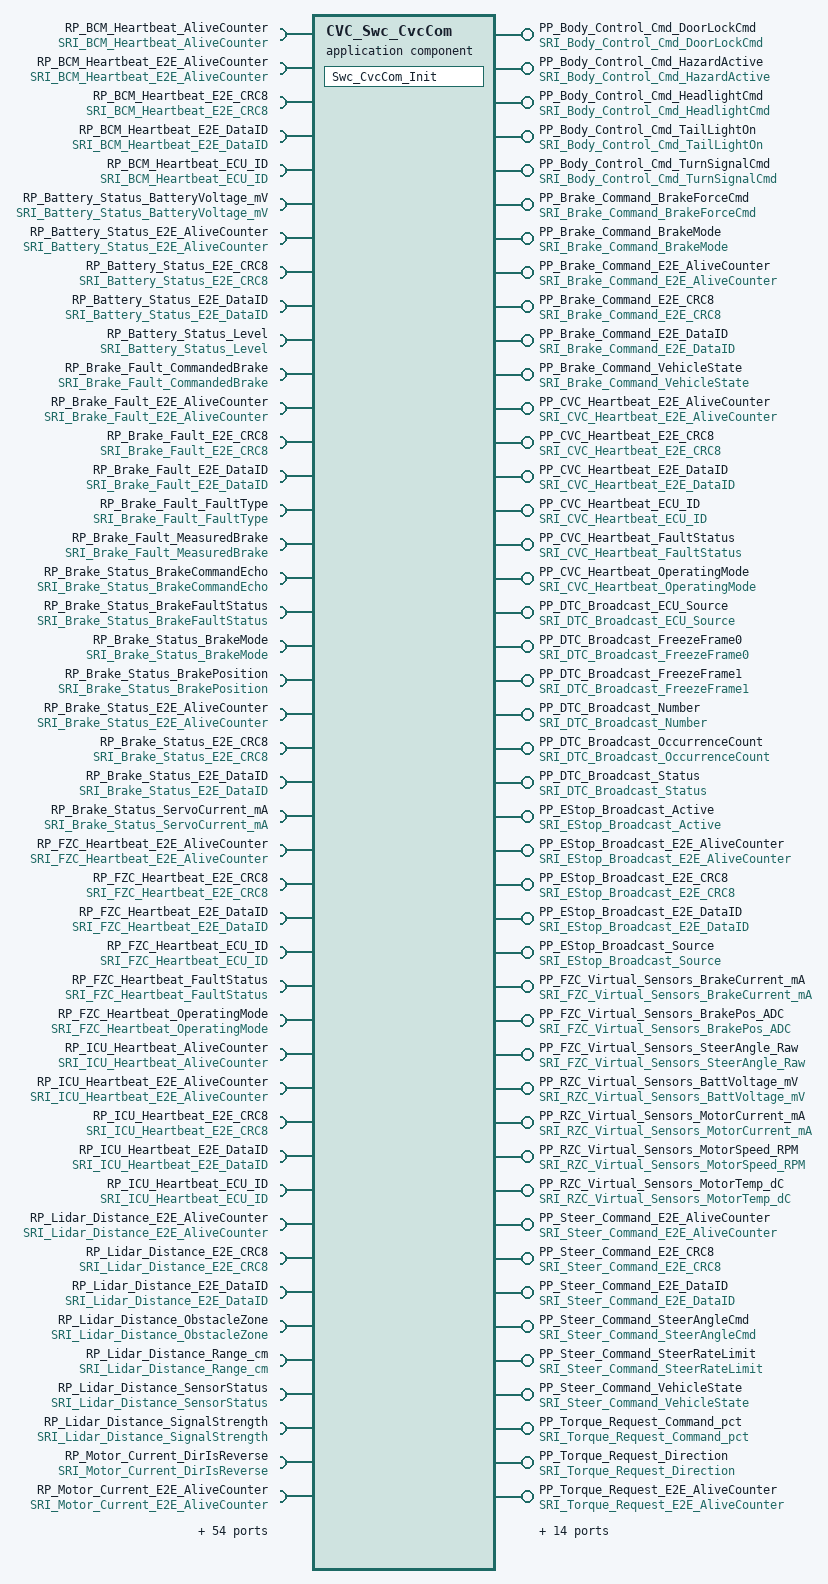
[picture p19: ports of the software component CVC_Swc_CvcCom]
  application sw component type CVC_Swc_CvcCom
    58 x provide port:
      PP_Body_Control_Cmd_DoorLockCmd: provided-interface=SRI_Body_Control_Cmd_DoorLockCmd
      PP_Body_Control_Cmd_HazardActive: provided-interface=SRI_Body_Control_Cmd_HazardActive
      PP_Body_Control_Cmd_HeadlightCmd: provided-interface=SRI_Body_Control_Cmd_HeadlightCmd
      PP_Body_Control_Cmd_TailLightOn: provided-interface=SRI_Body_Control_Cmd_TailLightOn
      PP_Body_Control_Cmd_TurnSignalCmd: provided-interface=SRI_Body_Control_Cmd_TurnSignalCmd
      PP_Brake_Command_BrakeForceCmd: provided-interface=SRI_Brake_Command_BrakeForceCmd
      PP_Brake_Command_BrakeMode: provided-interface=SRI_Brake_Command_BrakeMode
      PP_Brake_Command_E2E_AliveCounter: provided-interface=SRI_Brake_Command_E2E_AliveCounter
      PP_Brake_Command_E2E_CRC8: provided-interface=SRI_Brake_Command_E2E_CRC8
      PP_Brake_Command_E2E_DataID: provided-interface=SRI_Brake_Command_E2E_DataID
      PP_Brake_Command_VehicleState: provided-interface=SRI_Brake_Command_VehicleState
      PP_CVC_Heartbeat_E2E_AliveCounter: provided-interface=SRI_CVC_Heartbeat_E2E_AliveCounter
      PP_CVC_Heartbeat_E2E_CRC8: provided-interface=SRI_CVC_Heartbeat_E2E_CRC8
      PP_CVC_Heartbeat_E2E_DataID: provided-interface=SRI_CVC_Heartbeat_E2E_DataID
      PP_CVC_Heartbeat_ECU_ID: provided-interface=SRI_CVC_Heartbeat_ECU_ID
      PP_CVC_Heartbeat_FaultStatus: provided-interface=SRI_CVC_Heartbeat_FaultStatus
      PP_CVC_Heartbeat_OperatingMode: provided-interface=SRI_CVC_Heartbeat_OperatingMode
      PP_DTC_Broadcast_ECU_Source: provided-interface=SRI_DTC_Broadcast_ECU_Source
      PP_DTC_Broadcast_FreezeFrame0: provided-interface=SRI_DTC_Broadcast_FreezeFrame0
      PP_DTC_Broadcast_FreezeFrame1: provided-interface=SRI_DTC_Broadcast_FreezeFrame1
      PP_DTC_Broadcast_Number: provided-interface=SRI_DTC_Broadcast_Number
      PP_DTC_Broadcast_OccurrenceCount: provided-interface=SRI_DTC_Broadcast_OccurrenceCount
      PP_DTC_Broadcast_Status: provided-interface=SRI_DTC_Broadcast_Status
      PP_EStop_Broadcast_Active: provided-interface=SRI_EStop_Broadcast_Active
      PP_EStop_Broadcast_E2E_AliveCounter: provided-interface=SRI_EStop_Broadcast_E2E_AliveCounter
      PP_EStop_Broadcast_E2E_CRC8: provided-interface=SRI_EStop_Broadcast_E2E_CRC8
      PP_EStop_Broadcast_E2E_DataID: provided-interface=SRI_EStop_Broadcast_E2E_DataID
      PP_EStop_Broadcast_Source: provided-interface=SRI_EStop_Broadcast_Source
      PP_FZC_Virtual_Sensors_BrakeCurrent_mA: provided-interface=SRI_FZC_Virtual_Sensors_BrakeCurrent_mA
      PP_FZC_Virtual_Sensors_BrakePos_ADC: provided-interface=SRI_FZC_Virtual_Sensors_BrakePos_ADC
      PP_FZC_Virtual_Sensors_SteerAngle_Raw: provided-interface=SRI_FZC_Virtual_Sensors_SteerAngle_Raw
      PP_RZC_Virtual_Sensors_BattVoltage_mV: provided-interface=SRI_RZC_Virtual_Sensors_BattVoltage_mV
      PP_RZC_Virtual_Sensors_MotorCurrent_mA: provided-interface=SRI_RZC_Virtual_Sensors_MotorCurrent_mA
      PP_RZC_Virtual_Sensors_MotorSpeed_RPM: provided-interface=SRI_RZC_Virtual_Sensors_MotorSpeed_RPM
      PP_RZC_Virtual_Sensors_MotorTemp_dC: provided-interface=SRI_RZC_Virtual_Sensors_MotorTemp_dC
      PP_Steer_Command_E2E_AliveCounter: provided-interface=SRI_Steer_Command_E2E_AliveCounter
      PP_Steer_Command_E2E_CRC8: provided-interface=SRI_Steer_Command_E2E_CRC8
      PP_Steer_Command_E2E_DataID: provided-interface=SRI_Steer_Command_E2E_DataID
      PP_Steer_Command_SteerAngleCmd: provided-interface=SRI_Steer_Command_SteerAngleCmd
      PP_Steer_Command_SteerRateLimit: provided-interface=SRI_Steer_Command_SteerRateLimit
      PP_Steer_Command_VehicleState: provided-interface=SRI_Steer_Command_VehicleState
      PP_Torque_Request_Command_pct: provided-interface=SRI_Torque_Request_Command_pct
      PP_Torque_Request_Direction: provided-interface=SRI_Torque_Request_Direction
      PP_Torque_Request_E2E_AliveCounter: provided-interface=SRI_Torque_Request_E2E_AliveCounter
      PP_Torque_Request_E2E_CRC8: provided-interface=SRI_Torque_Request_E2E_CRC8
      PP_Torque_Request_E2E_DataID: provided-interface=SRI_Torque_Request_E2E_DataID
      PP_Torque_Request_PedalFault: provided-interface=SRI_Torque_Request_PedalFault
      PP_Torque_Request_PedalPosition1: provided-interface=SRI_Torque_Request_PedalPosition1
      PP_Torque_Request_PedalPosition2: provided-interface=SRI_Torque_Request_PedalPosition2
      PP_UDS_Resp_CVC_UDS_Data: provided-interface=SRI_UDS_Resp_CVC_UDS_Data
      PP_Vehicle_State_E2E_AliveCounter: provided-interface=SRI_Vehicle_State_E2E_AliveCounter
      PP_Vehicle_State_E2E_CRC8: provided-interface=SRI_Vehicle_State_E2E_CRC8
      PP_Vehicle_State_E2E_DataID: provided-interface=SRI_Vehicle_State_E2E_DataID
      PP_Vehicle_State_FaultMask: provided-interface=SRI_Vehicle_State_FaultMask
      PP_Vehicle_State_Mode: provided-interface=SRI_Vehicle_State_Mode
      PP_Vehicle_State_SpeedLimit: provided-interface=SRI_Vehicle_State_SpeedLimit
      PP_Vehicle_State_TorqueLimit: provided-interface=SRI_Vehicle_State_TorqueLimit
      PP_XCP_Resp_CVC_Data: provided-interface=SRI_XCP_Resp_CVC_Data
    98 x require port:
      RP_BCM_Heartbeat_AliveCounter: required-interface=SRI_BCM_Heartbeat_AliveCounter
      RP_BCM_Heartbeat_E2E_AliveCounter: required-interface=SRI_BCM_Heartbeat_E2E_AliveCounter
      RP_BCM_Heartbeat_E2E_CRC8: required-interface=SRI_BCM_Heartbeat_E2E_CRC8
      RP_BCM_Heartbeat_E2E_DataID: required-interface=SRI_BCM_Heartbeat_E2E_DataID
      RP_BCM_Heartbeat_ECU_ID: required-interface=SRI_BCM_Heartbeat_ECU_ID
      RP_Battery_Status_BatteryVoltage_mV: required-interface=SRI_Battery_Status_BatteryVoltage_mV
      RP_Battery_Status_E2E_AliveCounter: required-interface=SRI_Battery_Status_E2E_AliveCounter
      RP_Battery_Status_E2E_CRC8: required-interface=SRI_Battery_Status_E2E_CRC8
      RP_Battery_Status_E2E_DataID: required-interface=SRI_Battery_Status_E2E_DataID
      RP_Battery_Status_Level: required-interface=SRI_Battery_Status_Level
      RP_Brake_Fault_CommandedBrake: required-interface=SRI_Brake_Fault_CommandedBrake
      RP_Brake_Fault_E2E_AliveCounter: required-interface=SRI_Brake_Fault_E2E_AliveCounter
      RP_Brake_Fault_E2E_CRC8: required-interface=SRI_Brake_Fault_E2E_CRC8
      RP_Brake_Fault_E2E_DataID: required-interface=SRI_Brake_Fault_E2E_DataID
      RP_Brake_Fault_FaultType: required-interface=SRI_Brake_Fault_FaultType
      RP_Brake_Fault_MeasuredBrake: required-interface=SRI_Brake_Fault_MeasuredBrake
      RP_Brake_Status_BrakeCommandEcho: required-interface=SRI_Brake_Status_BrakeCommandEcho
      RP_Brake_Status_BrakeFaultStatus: required-interface=SRI_Brake_Status_BrakeFaultStatus
      RP_Brake_Status_BrakeMode: required-interface=SRI_Brake_Status_BrakeMode
      RP_Brake_Status_BrakePosition: required-interface=SRI_Brake_Status_BrakePosition
      RP_Brake_Status_E2E_AliveCounter: required-interface=SRI_Brake_Status_E2E_AliveCounter
      RP_Brake_Status_E2E_CRC8: required-interface=SRI_Brake_Status_E2E_CRC8
      RP_Brake_Status_E2E_DataID: required-interface=SRI_Brake_Status_E2E_DataID
      RP_Brake_Status_ServoCurrent_mA: required-interface=SRI_Brake_Status_ServoCurrent_mA
      RP_FZC_Heartbeat_E2E_AliveCounter: required-interface=SRI_FZC_Heartbeat_E2E_AliveCounter
      RP_FZC_Heartbeat_E2E_CRC8: required-interface=SRI_FZC_Heartbeat_E2E_CRC8
      RP_FZC_Heartbeat_E2E_DataID: required-interface=SRI_FZC_Heartbeat_E2E_DataID
      RP_FZC_Heartbeat_ECU_ID: required-interface=SRI_FZC_Heartbeat_ECU_ID
      RP_FZC_Heartbeat_FaultStatus: required-interface=SRI_FZC_Heartbeat_FaultStatus
      RP_FZC_Heartbeat_OperatingMode: required-interface=SRI_FZC_Heartbeat_OperatingMode
      RP_ICU_Heartbeat_AliveCounter: required-interface=SRI_ICU_Heartbeat_AliveCounter
      RP_ICU_Heartbeat_E2E_AliveCounter: required-interface=SRI_ICU_Heartbeat_E2E_AliveCounter
      RP_ICU_Heartbeat_E2E_CRC8: required-interface=SRI_ICU_Heartbeat_E2E_CRC8
      RP_ICU_Heartbeat_E2E_DataID: required-interface=SRI_ICU_Heartbeat_E2E_DataID
      RP_ICU_Heartbeat_ECU_ID: required-interface=SRI_ICU_Heartbeat_ECU_ID
      RP_Lidar_Distance_E2E_AliveCounter: required-interface=SRI_Lidar_Distance_E2E_AliveCounter
      RP_Lidar_Distance_E2E_CRC8: required-interface=SRI_Lidar_Distance_E2E_CRC8
      RP_Lidar_Distance_E2E_DataID: required-interface=SRI_Lidar_Distance_E2E_DataID
      RP_Lidar_Distance_ObstacleZone: required-interface=SRI_Lidar_Distance_ObstacleZone
      RP_Lidar_Distance_Range_cm: required-interface=SRI_Lidar_Distance_Range_cm
      RP_Lidar_Distance_SensorStatus: required-interface=SRI_Lidar_Distance_SensorStatus
      RP_Lidar_Distance_SignalStrength: required-interface=SRI_Lidar_Distance_SignalStrength
      RP_Motor_Current_DirIsReverse: required-interface=SRI_Motor_Current_DirIsReverse
      RP_Motor_Current_E2E_AliveCounter: required-interface=SRI_Motor_Current_E2E_AliveCounter
      RP_Motor_Current_E2E_CRC8: required-interface=SRI_Motor_Current_E2E_CRC8
      RP_Motor_Current_E2E_DataID: required-interface=SRI_Motor_Current_E2E_DataID
      RP_Motor_Current_MotorEnable: required-interface=SRI_Motor_Current_MotorEnable
      RP_Motor_Current_OvercurrentFlag: required-interface=SRI_Motor_Current_OvercurrentFlag
      RP_Motor_Current_Phase_mA: required-interface=SRI_Motor_Current_Phase_mA
      RP_Motor_Current_TorqueEcho: required-interface=SRI_Motor_Current_TorqueEcho
      RP_Motor_Cutoff_Req_E2E_AliveCounter: required-interface=SRI_Motor_Cutoff_Req_E2E_AliveCounter
      RP_Motor_Cutoff_Req_E2E_CRC8: required-interface=SRI_Motor_Cutoff_Req_E2E_CRC8
      RP_Motor_Cutoff_Req_E2E_DataID: required-interface=SRI_Motor_Cutoff_Req_E2E_DataID
      RP_Motor_Cutoff_Req_Reason: required-interface=SRI_Motor_Cutoff_Req_Reason
      RP_Motor_Cutoff_Req_RequestType: required-interface=SRI_Motor_Cutoff_Req_RequestType
      RP_Motor_Status_E2E_AliveCounter: required-interface=SRI_Motor_Status_E2E_AliveCounter
      RP_Motor_Status_E2E_CRC8: required-interface=SRI_Motor_Status_E2E_CRC8
      RP_Motor_Status_E2E_DataID: required-interface=SRI_Motor_Status_E2E_DataID
      RP_Motor_Status_MotorDirection: required-interface=SRI_Motor_Status_MotorDirection
      RP_Motor_Status_MotorEnable: required-interface=SRI_Motor_Status_MotorEnable
      RP_Motor_Status_MotorFaultStatus: required-interface=SRI_Motor_Status_MotorFaultStatus
      RP_Motor_Status_MotorSpeed_RPM: required-interface=SRI_Motor_Status_MotorSpeed_RPM
      RP_Motor_Status_TorqueEcho: required-interface=SRI_Motor_Status_TorqueEcho
      RP_Motor_Temperature_DeratingPercent: required-interface=SRI_Motor_Temperature_DeratingPercent
      RP_Motor_Temperature_E2E_AliveCounter: required-interface=SRI_Motor_Temperature_E2E_AliveCounter
      RP_Motor_Temperature_E2E_CRC8: required-interface=SRI_Motor_Temperature_E2E_CRC8
      RP_Motor_Temperature_E2E_DataID: required-interface=SRI_Motor_Temperature_E2E_DataID
      RP_Motor_Temperature_WindingTemp1_C: required-interface=SRI_Motor_Temperature_WindingTemp1_C
      RP_Motor_Temperature_WindingTemp2_C: required-interface=SRI_Motor_Temperature_WindingTemp2_C
      RP_RZC_Heartbeat_E2E_AliveCounter: required-interface=SRI_RZC_Heartbeat_E2E_AliveCounter
      RP_RZC_Heartbeat_E2E_CRC8: required-interface=SRI_RZC_Heartbeat_E2E_CRC8
      RP_RZC_Heartbeat_E2E_DataID: required-interface=SRI_RZC_Heartbeat_E2E_DataID
      RP_RZC_Heartbeat_ECU_ID: required-interface=SRI_RZC_Heartbeat_ECU_ID
      RP_RZC_Heartbeat_FaultStatus: required-interface=SRI_RZC_Heartbeat_FaultStatus
      RP_RZC_Heartbeat_OperatingMode: required-interface=SRI_RZC_Heartbeat_OperatingMode
      RP_SC_Status_AliveCounter: required-interface=SRI_SC_Status_AliveCounter
      RP_SC_Status_CRC8: required-interface=SRI_SC_Status_CRC8
      RP_SC_Status_ECU_Health: required-interface=SRI_SC_Status_ECU_Health
      RP_SC_Status_FaultFlags: required-interface=SRI_SC_Status_FaultFlags
      RP_SC_Status_FaultReason: required-interface=SRI_SC_Status_FaultReason
      RP_SC_Status_Mode: required-interface=SRI_SC_Status_Mode
      RP_SC_Status_RelayEnergized: required-interface=SRI_SC_Status_RelayEnergized
      RP_Steering_Status_ActualAngle: required-interface=SRI_Steering_Status_ActualAngle
      RP_Steering_Status_CommandedAngle: required-interface=SRI_Steering_Status_CommandedAngle
      RP_Steering_Status_E2E_AliveCounter: required-interface=SRI_Steering_Status_E2E_AliveCounter
      RP_Steering_Status_E2E_CRC8: required-interface=SRI_Steering_Status_E2E_CRC8
      RP_Steering_Status_E2E_DataID: required-interface=SRI_Steering_Status_E2E_DataID
      RP_Steering_Status_ServoCurrent_mA: required-interface=SRI_Steering_Status_ServoCurrent_mA
      RP_Steering_Status_SteerFaultStatus: required-interface=SRI_Steering_Status_SteerFaultStatus
      RP_Steering_Status_SteerMode: required-interface=SRI_Steering_Status_SteerMode
      RP_TCU_Heartbeat_AliveCounter: required-interface=SRI_TCU_Heartbeat_AliveCounter
      RP_TCU_Heartbeat_E2E_AliveCounter: required-interface=SRI_TCU_Heartbeat_E2E_AliveCounter
      RP_TCU_Heartbeat_E2E_CRC8: required-interface=SRI_TCU_Heartbeat_E2E_CRC8
      RP_TCU_Heartbeat_E2E_DataID: required-interface=SRI_TCU_Heartbeat_E2E_DataID
      RP_TCU_Heartbeat_ECU_ID: required-interface=SRI_TCU_Heartbeat_ECU_ID
      RP_UDS_Func_Request_UDS_Data: required-interface=SRI_UDS_Func_Request_UDS_Data
      RP_UDS_Phys_Req_CVC_UDS_Data: required-interface=SRI_UDS_Phys_Req_CVC_UDS_Data
      RP_XCP_Req_CVC_Data: required-interface=SRI_XCP_Req_CVC_Data
    behavior CVC_Swc_CvcCom_IB
      init event IE_Swc_CvcCom_Init: start-on-event=Swc_CvcCom_Init
      runnable Swc_CvcCom_Init
  application sw component type CVC_Swc_CvcDcm
    behavior CVC_Swc_CvcDcm_IB
      init event IE_Swc_CvcDcm_Init: start-on-event=Swc_CvcDcm_Init
      runnable Swc_CvcDcm_Init
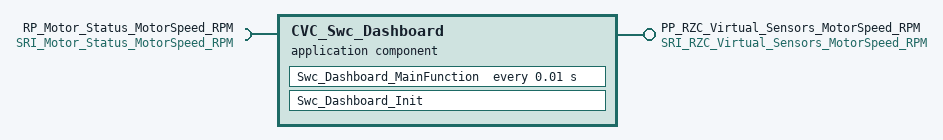
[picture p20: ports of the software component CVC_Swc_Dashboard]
  application sw component type CVC_Swc_Dashboard
    provide port PP_RZC_Virtual_Sensors_MotorSpeed_RPM: provided-interface=SRI_RZC_Virtual_Sensors_MotorSpeed_RPM
    require port RP_Motor_Status_MotorSpeed_RPM: required-interface=SRI_Motor_Status_MotorSpeed_RPM
    behavior CVC_Swc_Dashboard_IB
      init event IE_Swc_Dashboard_Init: start-on-event=Swc_Dashboard_Init
      timing event TE_Swc_Dashboard_MainFunction_10ms: start-on-event=Swc_Dashboard_MainFunction, period=0.01
      runnable Swc_Dashboard_Init
      runnable Swc_Dashboard_MainFunction
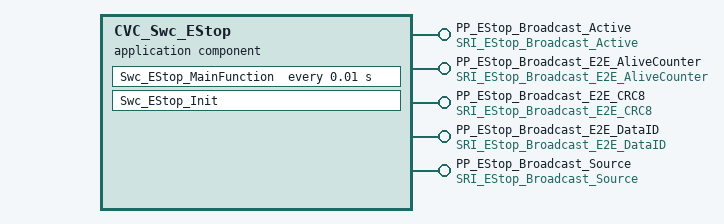
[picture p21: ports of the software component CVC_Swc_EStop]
  application sw component type CVC_Swc_EStop
    5 x provide port:
      PP_EStop_Broadcast_Active: provided-interface=SRI_EStop_Broadcast_Active
      PP_EStop_Broadcast_E2E_AliveCounter: provided-interface=SRI_EStop_Broadcast_E2E_AliveCounter
      PP_EStop_Broadcast_E2E_CRC8: provided-interface=SRI_EStop_Broadcast_E2E_CRC8
      PP_EStop_Broadcast_E2E_DataID: provided-interface=SRI_EStop_Broadcast_E2E_DataID
      PP_EStop_Broadcast_Source: provided-interface=SRI_EStop_Broadcast_Source
    behavior CVC_Swc_EStop_IB
      init event IE_Swc_EStop_Init: start-on-event=Swc_EStop_Init
      timing event TE_Swc_EStop_MainFunction_10ms: start-on-event=Swc_EStop_MainFunction, period=0.01
      runnable Swc_EStop_Init
      runnable Swc_EStop_MainFunction
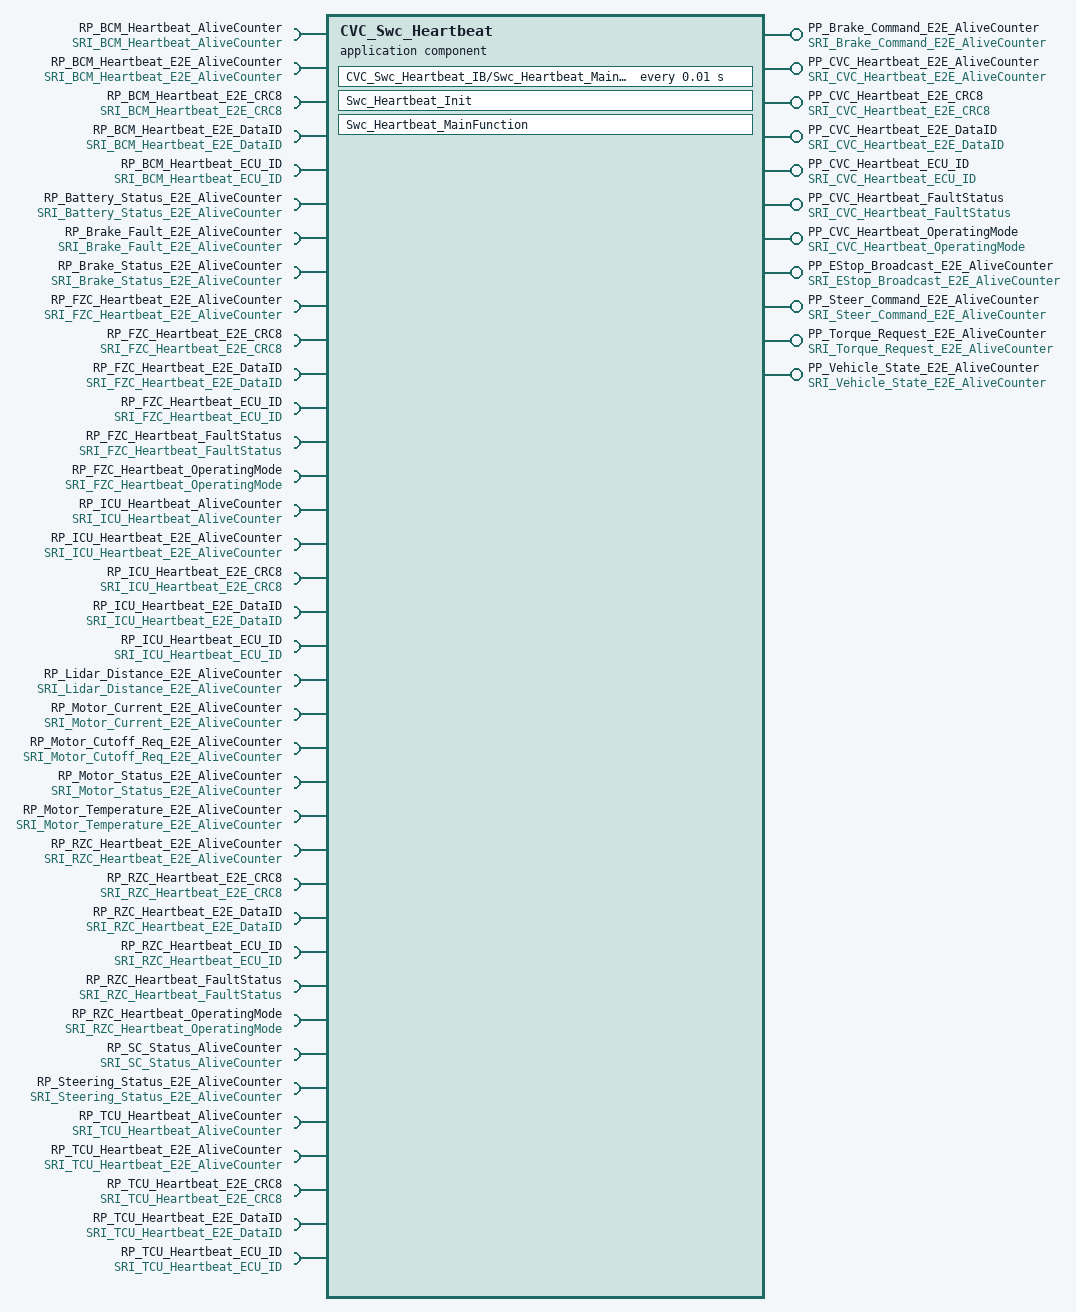
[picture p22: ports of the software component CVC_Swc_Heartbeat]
  application sw component type CVC_Swc_Heartbeat
    11 x provide port:
      PP_Brake_Command_E2E_AliveCounter: provided-interface=SRI_Brake_Command_E2E_AliveCounter
      PP_CVC_Heartbeat_E2E_AliveCounter: provided-interface=SRI_CVC_Heartbeat_E2E_AliveCounter
      PP_CVC_Heartbeat_E2E_CRC8: provided-interface=SRI_CVC_Heartbeat_E2E_CRC8
      PP_CVC_Heartbeat_E2E_DataID: provided-interface=SRI_CVC_Heartbeat_E2E_DataID
      PP_CVC_Heartbeat_ECU_ID: provided-interface=SRI_CVC_Heartbeat_ECU_ID
      PP_CVC_Heartbeat_FaultStatus: provided-interface=SRI_CVC_Heartbeat_FaultStatus
      PP_CVC_Heartbeat_OperatingMode: provided-interface=SRI_CVC_Heartbeat_OperatingMode
      PP_EStop_Broadcast_E2E_AliveCounter: provided-interface=SRI_EStop_Broadcast_E2E_AliveCounter
      PP_Steer_Command_E2E_AliveCounter: provided-interface=SRI_Steer_Command_E2E_AliveCounter
      PP_Torque_Request_E2E_AliveCounter: provided-interface=SRI_Torque_Request_E2E_AliveCounter
      PP_Vehicle_State_E2E_AliveCounter: provided-interface=SRI_Vehicle_State_E2E_AliveCounter
    37 x require port:
      RP_BCM_Heartbeat_AliveCounter: required-interface=SRI_BCM_Heartbeat_AliveCounter
      RP_BCM_Heartbeat_E2E_AliveCounter: required-interface=SRI_BCM_Heartbeat_E2E_AliveCounter
      RP_BCM_Heartbeat_E2E_CRC8: required-interface=SRI_BCM_Heartbeat_E2E_CRC8
      RP_BCM_Heartbeat_E2E_DataID: required-interface=SRI_BCM_Heartbeat_E2E_DataID
      RP_BCM_Heartbeat_ECU_ID: required-interface=SRI_BCM_Heartbeat_ECU_ID
      RP_Battery_Status_E2E_AliveCounter: required-interface=SRI_Battery_Status_E2E_AliveCounter
      RP_Brake_Fault_E2E_AliveCounter: required-interface=SRI_Brake_Fault_E2E_AliveCounter
      RP_Brake_Status_E2E_AliveCounter: required-interface=SRI_Brake_Status_E2E_AliveCounter
      RP_FZC_Heartbeat_E2E_AliveCounter: required-interface=SRI_FZC_Heartbeat_E2E_AliveCounter
      RP_FZC_Heartbeat_E2E_CRC8: required-interface=SRI_FZC_Heartbeat_E2E_CRC8
      RP_FZC_Heartbeat_E2E_DataID: required-interface=SRI_FZC_Heartbeat_E2E_DataID
      RP_FZC_Heartbeat_ECU_ID: required-interface=SRI_FZC_Heartbeat_ECU_ID
      RP_FZC_Heartbeat_FaultStatus: required-interface=SRI_FZC_Heartbeat_FaultStatus
      RP_FZC_Heartbeat_OperatingMode: required-interface=SRI_FZC_Heartbeat_OperatingMode
      RP_ICU_Heartbeat_AliveCounter: required-interface=SRI_ICU_Heartbeat_AliveCounter
      RP_ICU_Heartbeat_E2E_AliveCounter: required-interface=SRI_ICU_Heartbeat_E2E_AliveCounter
      RP_ICU_Heartbeat_E2E_CRC8: required-interface=SRI_ICU_Heartbeat_E2E_CRC8
      RP_ICU_Heartbeat_E2E_DataID: required-interface=SRI_ICU_Heartbeat_E2E_DataID
      RP_ICU_Heartbeat_ECU_ID: required-interface=SRI_ICU_Heartbeat_ECU_ID
      RP_Lidar_Distance_E2E_AliveCounter: required-interface=SRI_Lidar_Distance_E2E_AliveCounter
      RP_Motor_Current_E2E_AliveCounter: required-interface=SRI_Motor_Current_E2E_AliveCounter
      RP_Motor_Cutoff_Req_E2E_AliveCounter: required-interface=SRI_Motor_Cutoff_Req_E2E_AliveCounter
      RP_Motor_Status_E2E_AliveCounter: required-interface=SRI_Motor_Status_E2E_AliveCounter
      RP_Motor_Temperature_E2E_AliveCounter: required-interface=SRI_Motor_Temperature_E2E_AliveCounter
      RP_RZC_Heartbeat_E2E_AliveCounter: required-interface=SRI_RZC_Heartbeat_E2E_AliveCounter
      RP_RZC_Heartbeat_E2E_CRC8: required-interface=SRI_RZC_Heartbeat_E2E_CRC8
      RP_RZC_Heartbeat_E2E_DataID: required-interface=SRI_RZC_Heartbeat_E2E_DataID
      RP_RZC_Heartbeat_ECU_ID: required-interface=SRI_RZC_Heartbeat_ECU_ID
      RP_RZC_Heartbeat_FaultStatus: required-interface=SRI_RZC_Heartbeat_FaultStatus
      RP_RZC_Heartbeat_OperatingMode: required-interface=SRI_RZC_Heartbeat_OperatingMode
      RP_SC_Status_AliveCounter: required-interface=SRI_SC_Status_AliveCounter
      RP_Steering_Status_E2E_AliveCounter: required-interface=SRI_Steering_Status_E2E_AliveCounter
      RP_TCU_Heartbeat_AliveCounter: required-interface=SRI_TCU_Heartbeat_AliveCounter
      RP_TCU_Heartbeat_E2E_AliveCounter: required-interface=SRI_TCU_Heartbeat_E2E_AliveCounter
      RP_TCU_Heartbeat_E2E_CRC8: required-interface=SRI_TCU_Heartbeat_E2E_CRC8
      RP_TCU_Heartbeat_E2E_DataID: required-interface=SRI_TCU_Heartbeat_E2E_DataID
      RP_TCU_Heartbeat_ECU_ID: required-interface=SRI_TCU_Heartbeat_ECU_ID
    behavior CVC_Swc_Heartbeat_IB
      init event IE_Swc_Heartbeat_Init: start-on-event=Swc_Heartbeat_Init
      timing event TE_Swc_Heartbeat_MainFunction_10ms: start-on-event=CVC_Swc_Heartbeat_IB/Swc_Heartbeat_MainFunction, period=0.01
      runnable Swc_Heartbeat_Init
      runnable Swc_Heartbeat_MainFunction
  application sw component type CVC_Swc_Nvm
    behavior CVC_Swc_Nvm_IB
      init event IE_Swc_Nvm_Init: start-on-event=Swc_Nvm_Init
      runnable Swc_Nvm_Init
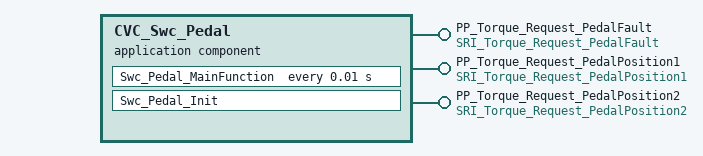
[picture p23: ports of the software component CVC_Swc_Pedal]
  application sw component type CVC_Swc_Pedal
    provide port PP_Torque_Request_PedalFault: provided-interface=SRI_Torque_Request_PedalFault
    provide port PP_Torque_Request_PedalPosition1: provided-interface=SRI_Torque_Request_PedalPosition1
    provide port PP_Torque_Request_PedalPosition2: provided-interface=SRI_Torque_Request_PedalPosition2
    behavior CVC_Swc_Pedal_IB
      init event IE_Swc_Pedal_Init: start-on-event=Swc_Pedal_Init
      timing event TE_Swc_Pedal_MainFunction_10ms: start-on-event=Swc_Pedal_MainFunction, period=0.01
      runnable Swc_Pedal_Init
      runnable Swc_Pedal_MainFunction
  application sw component type CVC_Swc_Scheduler
    behavior CVC_Swc_Scheduler_IB
      init event IE_Swc_Scheduler_Init: start-on-event=Swc_Scheduler_Init
      runnable Swc_Scheduler_Init
  application sw component type CVC_Swc_SelfTest
    behavior CVC_Swc_SelfTest_IB
  application sw component type CVC_Swc_VehicleState
    9 x provide port:
      PP_Brake_Command_VehicleState: provided-interface=SRI_Brake_Command_VehicleState
      PP_Steer_Command_VehicleState: provided-interface=SRI_Steer_Command_VehicleState
      PP_Vehicle_State_E2E_AliveCounter: provided-interface=SRI_Vehicle_State_E2E_AliveCounter
      PP_Vehicle_State_E2E_CRC8: provided-interface=SRI_Vehicle_State_E2E_CRC8
      PP_Vehicle_State_E2E_DataID: provided-interface=SRI_Vehicle_State_E2E_DataID
      PP_Vehicle_State_FaultMask: provided-interface=SRI_Vehicle_State_FaultMask
      PP_Vehicle_State_Mode: provided-interface=SRI_Vehicle_State_Mode
      PP_Vehicle_State_SpeedLimit: provided-interface=SRI_Vehicle_State_SpeedLimit
      PP_Vehicle_State_TorqueLimit: provided-interface=SRI_Vehicle_State_TorqueLimit
    behavior CVC_Swc_VehicleState_IB
      init event IE_Swc_VehicleState_Init: start-on-event=Swc_VehicleState_Init
      timing event TE_Swc_VehicleState_MainFunction_10ms: start-on-event=Swc_VehicleState_MainFunction, period=0.01
      runnable Swc_VehicleState_Init
      runnable Swc_VehicleState_MainFunction
  application sw component type CVC_Swc_Watchdog
    behavior CVC_Swc_Watchdog_IB
      init event IE_Swc_Watchdog_Init: start-on-event=Swc_Watchdog_Init
      runnable Swc_Watchdog_Init
package /Taktflow/SWCs/FZC
  application sw component type FZC_Swc_Brake
    14 x provide port:
      PP_Brake_Fault_CommandedBrake: provided-interface=SRI_Brake_Fault_CommandedBrake
      PP_Brake_Fault_E2E_AliveCounter: provided-interface=SRI_Brake_Fault_E2E_AliveCounter
      PP_Brake_Fault_E2E_CRC8: provided-interface=SRI_Brake_Fault_E2E_CRC8
      PP_Brake_Fault_E2E_DataID: provided-interface=SRI_Brake_Fault_E2E_DataID
      PP_Brake_Fault_FaultType: provided-interface=SRI_Brake_Fault_FaultType
      PP_Brake_Fault_MeasuredBrake: provided-interface=SRI_Brake_Fault_MeasuredBrake
      PP_Brake_Status_BrakeCommandEcho: provided-interface=SRI_Brake_Status_BrakeCommandEcho
      PP_Brake_Status_BrakeFaultStatus: provided-interface=SRI_Brake_Status_BrakeFaultStatus
      PP_Brake_Status_BrakeMode: provided-interface=SRI_Brake_Status_BrakeMode
      PP_Brake_Status_BrakePosition: provided-interface=SRI_Brake_Status_BrakePosition
      PP_Brake_Status_E2E_AliveCounter: provided-interface=SRI_Brake_Status_E2E_AliveCounter
      PP_Brake_Status_E2E_CRC8: provided-interface=SRI_Brake_Status_E2E_CRC8
      PP_Brake_Status_E2E_DataID: provided-interface=SRI_Brake_Status_E2E_DataID
      PP_Brake_Status_ServoCurrent_mA: provided-interface=SRI_Brake_Status_ServoCurrent_mA
    8 x require port:
      RP_Brake_Command_BrakeForceCmd: required-interface=SRI_Brake_Command_BrakeForceCmd
      RP_Brake_Command_BrakeMode: required-interface=SRI_Brake_Command_BrakeMode
      RP_Brake_Command_E2E_AliveCounter: required-interface=SRI_Brake_Command_E2E_AliveCounter
      RP_Brake_Command_E2E_CRC8: required-interface=SRI_Brake_Command_E2E_CRC8
      RP_Brake_Command_E2E_DataID: required-interface=SRI_Brake_Command_E2E_DataID
      RP_Brake_Command_VehicleState: required-interface=SRI_Brake_Command_VehicleState
      RP_FZC_Virtual_Sensors_BrakeCurrent_mA: required-interface=SRI_FZC_Virtual_Sensors_BrakeCurrent_mA
      RP_FZC_Virtual_Sensors_BrakePos_ADC: required-interface=SRI_FZC_Virtual_Sensors_BrakePos_ADC
    behavior FZC_Swc_Brake_IB
      init event IE_Swc_Brake_Init: start-on-event=Swc_Brake_Init
      timing event TE_Swc_Brake_MainFunction_10ms: start-on-event=Swc_Brake_MainFunction, period=0.01
      runnable Swc_Brake_Init
      runnable Swc_Brake_MainFunction
  application sw component type FZC_Swc_Buzzer
    behavior FZC_Swc_Buzzer_IB
      init event IE_Swc_Buzzer_Init: start-on-event=Swc_Buzzer_Init
      timing event TE_Swc_Buzzer_MainFunction_10ms: start-on-event=Swc_Buzzer_MainFunction, period=0.01
      runnable Swc_Buzzer_Init
      runnable Swc_Buzzer_MainFunction
  application sw component type FZC_Swc_FzcCanMonitor
    42 x provide port:
      PP_Brake_Fault_CommandedBrake: provided-interface=SRI_Brake_Fault_CommandedBrake
      PP_Brake_Fault_E2E_AliveCounter: provided-interface=SRI_Brake_Fault_E2E_AliveCounter
      PP_Brake_Fault_E2E_CRC8: provided-interface=SRI_Brake_Fault_E2E_CRC8
      PP_Brake_Fault_E2E_DataID: provided-interface=SRI_Brake_Fault_E2E_DataID
      PP_Brake_Fault_FaultType: provided-interface=SRI_Brake_Fault_FaultType
      PP_Brake_Fault_MeasuredBrake: provided-interface=SRI_Brake_Fault_MeasuredBrake
      PP_Brake_Status_BrakeCommandEcho: provided-interface=SRI_Brake_Status_BrakeCommandEcho
      PP_Brake_Status_BrakeFaultStatus: provided-interface=SRI_Brake_Status_BrakeFaultStatus
      PP_Brake_Status_BrakeMode: provided-interface=SRI_Brake_Status_BrakeMode
      PP_Brake_Status_BrakePosition: provided-interface=SRI_Brake_Status_BrakePosition
      PP_Brake_Status_E2E_AliveCounter: provided-interface=SRI_Brake_Status_E2E_AliveCounter
      PP_Brake_Status_E2E_CRC8: provided-interface=SRI_Brake_Status_E2E_CRC8
      PP_Brake_Status_E2E_DataID: provided-interface=SRI_Brake_Status_E2E_DataID
      PP_Brake_Status_ServoCurrent_mA: provided-interface=SRI_Brake_Status_ServoCurrent_mA
      PP_FZC_Heartbeat_E2E_AliveCounter: provided-interface=SRI_FZC_Heartbeat_E2E_AliveCounter
      PP_FZC_Heartbeat_E2E_CRC8: provided-interface=SRI_FZC_Heartbeat_E2E_CRC8
      PP_FZC_Heartbeat_E2E_DataID: provided-interface=SRI_FZC_Heartbeat_E2E_DataID
      PP_FZC_Heartbeat_ECU_ID: provided-interface=SRI_FZC_Heartbeat_ECU_ID
      PP_FZC_Heartbeat_FaultStatus: provided-interface=SRI_FZC_Heartbeat_FaultStatus
      PP_FZC_Heartbeat_OperatingMode: provided-interface=SRI_FZC_Heartbeat_OperatingMode
      PP_Lidar_Distance_E2E_AliveCounter: provided-interface=SRI_Lidar_Distance_E2E_AliveCounter
      PP_Lidar_Distance_E2E_CRC8: provided-interface=SRI_Lidar_Distance_E2E_CRC8
      PP_Lidar_Distance_E2E_DataID: provided-interface=SRI_Lidar_Distance_E2E_DataID
      PP_Lidar_Distance_ObstacleZone: provided-interface=SRI_Lidar_Distance_ObstacleZone
      PP_Lidar_Distance_Range_cm: provided-interface=SRI_Lidar_Distance_Range_cm
      PP_Lidar_Distance_SensorStatus: provided-interface=SRI_Lidar_Distance_SensorStatus
      PP_Lidar_Distance_SignalStrength: provided-interface=SRI_Lidar_Distance_SignalStrength
      PP_Motor_Cutoff_Req_E2E_AliveCounter: provided-interface=SRI_Motor_Cutoff_Req_E2E_AliveCounter
      PP_Motor_Cutoff_Req_E2E_CRC8: provided-interface=SRI_Motor_Cutoff_Req_E2E_CRC8
      PP_Motor_Cutoff_Req_E2E_DataID: provided-interface=SRI_Motor_Cutoff_Req_E2E_DataID
      PP_Motor_Cutoff_Req_Reason: provided-interface=SRI_Motor_Cutoff_Req_Reason
      PP_Motor_Cutoff_Req_RequestType: provided-interface=SRI_Motor_Cutoff_Req_RequestType
      PP_Steering_Status_ActualAngle: provided-interface=SRI_Steering_Status_ActualAngle
      PP_Steering_Status_CommandedAngle: provided-interface=SRI_Steering_Status_CommandedAngle
      PP_Steering_Status_E2E_AliveCounter: provided-interface=SRI_Steering_Status_E2E_AliveCounter
      PP_Steering_Status_E2E_CRC8: provided-interface=SRI_Steering_Status_E2E_CRC8
      PP_Steering_Status_E2E_DataID: provided-interface=SRI_Steering_Status_E2E_DataID
      PP_Steering_Status_ServoCurrent_mA: provided-interface=SRI_Steering_Status_ServoCurrent_mA
      PP_Steering_Status_SteerFaultStatus: provided-interface=SRI_Steering_Status_SteerFaultStatus
      PP_Steering_Status_SteerMode: provided-interface=SRI_Steering_Status_SteerMode
      PP_UDS_Resp_FZC_UDS_Data: provided-interface=SRI_UDS_Resp_FZC_UDS_Data
      PP_XCP_Resp_FZC_Data: provided-interface=SRI_XCP_Resp_FZC_Data
    41 x require port:
      RP_Brake_Command_BrakeForceCmd: required-interface=SRI_Brake_Command_BrakeForceCmd
      RP_Brake_Command_BrakeMode: required-interface=SRI_Brake_Command_BrakeMode
      RP_Brake_Command_E2E_AliveCounter: required-interface=SRI_Brake_Command_E2E_AliveCounter
      RP_Brake_Command_E2E_CRC8: required-interface=SRI_Brake_Command_E2E_CRC8
      RP_Brake_Command_E2E_DataID: required-interface=SRI_Brake_Command_E2E_DataID
      RP_Brake_Command_VehicleState: required-interface=SRI_Brake_Command_VehicleState
      RP_CVC_Heartbeat_E2E_AliveCounter: required-interface=SRI_CVC_Heartbeat_E2E_AliveCounter
      RP_CVC_Heartbeat_E2E_CRC8: required-interface=SRI_CVC_Heartbeat_E2E_CRC8
      RP_CVC_Heartbeat_E2E_DataID: required-interface=SRI_CVC_Heartbeat_E2E_DataID
      RP_CVC_Heartbeat_ECU_ID: required-interface=SRI_CVC_Heartbeat_ECU_ID
      RP_CVC_Heartbeat_FaultStatus: required-interface=SRI_CVC_Heartbeat_FaultStatus
      RP_CVC_Heartbeat_OperatingMode: required-interface=SRI_CVC_Heartbeat_OperatingMode
      RP_EStop_Broadcast_Active: required-interface=SRI_EStop_Broadcast_Active
      RP_EStop_Broadcast_E2E_AliveCounter: required-interface=SRI_EStop_Broadcast_E2E_AliveCounter
      RP_EStop_Broadcast_E2E_CRC8: required-interface=SRI_EStop_Broadcast_E2E_CRC8
      RP_EStop_Broadcast_E2E_DataID: required-interface=SRI_EStop_Broadcast_E2E_DataID
      RP_EStop_Broadcast_Source: required-interface=SRI_EStop_Broadcast_Source
      RP_FZC_Virtual_Sensors_BrakeCurrent_mA: required-interface=SRI_FZC_Virtual_Sensors_BrakeCurrent_mA
      RP_FZC_Virtual_Sensors_BrakePos_ADC: required-interface=SRI_FZC_Virtual_Sensors_BrakePos_ADC
      RP_FZC_Virtual_Sensors_SteerAngle_Raw: required-interface=SRI_FZC_Virtual_Sensors_SteerAngle_Raw
      RP_SC_Status_AliveCounter: required-interface=SRI_SC_Status_AliveCounter
      RP_SC_Status_CRC8: required-interface=SRI_SC_Status_CRC8
      RP_SC_Status_ECU_Health: required-interface=SRI_SC_Status_ECU_Health
      RP_SC_Status_FaultFlags: required-interface=SRI_SC_Status_FaultFlags
      RP_SC_Status_FaultReason: required-interface=SRI_SC_Status_FaultReason
      RP_SC_Status_Mode: required-interface=SRI_SC_Status_Mode
      RP_SC_Status_RelayEnergized: required-interface=SRI_SC_Status_RelayEnergized
      RP_Steer_Command_E2E_AliveCounter: required-interface=SRI_Steer_Command_E2E_AliveCounter
      RP_Steer_Command_E2E_CRC8: required-interface=SRI_Steer_Command_E2E_CRC8
      RP_Steer_Command_E2E_DataID: required-interface=SRI_Steer_Command_E2E_DataID
      RP_Steer_Command_SteerAngleCmd: required-interface=SRI_Steer_Command_SteerAngleCmd
      RP_Steer_Command_SteerRateLimit: required-interface=SRI_Steer_Command_SteerRateLimit
      RP_Steer_Command_VehicleState: required-interface=SRI_Steer_Command_VehicleState
      RP_UDS_Func_Request_UDS_Data: required-interface=SRI_UDS_Func_Request_UDS_Data
      RP_UDS_Phys_Req_FZC_UDS_Data: required-interface=SRI_UDS_Phys_Req_FZC_UDS_Data
      RP_Vehicle_State_E2E_AliveCounter: required-interface=SRI_Vehicle_State_E2E_AliveCounter
      RP_Vehicle_State_E2E_CRC8: required-interface=SRI_Vehicle_State_E2E_CRC8
      RP_Vehicle_State_E2E_DataID: required-interface=SRI_Vehicle_State_E2E_DataID
      RP_Vehicle_State_FaultMask: required-interface=SRI_Vehicle_State_FaultMask
      RP_Vehicle_State_Mode: required-interface=SRI_Vehicle_State_Mode
      RP_XCP_Req_FZC_Data: required-interface=SRI_XCP_Req_FZC_Data
    behavior FZC_Swc_FzcCanMonitor_IB
      timing event TE_Swc_FzcCanMonitor_Check_10ms: start-on-event=Swc_FzcCanMonitor_Check, period=0.01
      init event IE_Swc_FzcCanMonitor_Init: start-on-event=Swc_FzcCanMonitor_Init
      runnable Swc_FzcCanMonitor_Check
      runnable Swc_FzcCanMonitor_Init
  application sw component type FZC_Swc_FzcCom
    42 x provide port:
      PP_Brake_Fault_CommandedBrake: provided-interface=SRI_Brake_Fault_CommandedBrake
      PP_Brake_Fault_E2E_AliveCounter: provided-interface=SRI_Brake_Fault_E2E_AliveCounter
      PP_Brake_Fault_E2E_CRC8: provided-interface=SRI_Brake_Fault_E2E_CRC8
      PP_Brake_Fault_E2E_DataID: provided-interface=SRI_Brake_Fault_E2E_DataID
      PP_Brake_Fault_FaultType: provided-interface=SRI_Brake_Fault_FaultType
      PP_Brake_Fault_MeasuredBrake: provided-interface=SRI_Brake_Fault_MeasuredBrake
      PP_Brake_Status_BrakeCommandEcho: provided-interface=SRI_Brake_Status_BrakeCommandEcho
      PP_Brake_Status_BrakeFaultStatus: provided-interface=SRI_Brake_Status_BrakeFaultStatus
      PP_Brake_Status_BrakeMode: provided-interface=SRI_Brake_Status_BrakeMode
      PP_Brake_Status_BrakePosition: provided-interface=SRI_Brake_Status_BrakePosition
      PP_Brake_Status_E2E_AliveCounter: provided-interface=SRI_Brake_Status_E2E_AliveCounter
      PP_Brake_Status_E2E_CRC8: provided-interface=SRI_Brake_Status_E2E_CRC8
      PP_Brake_Status_E2E_DataID: provided-interface=SRI_Brake_Status_E2E_DataID
      PP_Brake_Status_ServoCurrent_mA: provided-interface=SRI_Brake_Status_ServoCurrent_mA
      PP_FZC_Heartbeat_E2E_AliveCounter: provided-interface=SRI_FZC_Heartbeat_E2E_AliveCounter
      PP_FZC_Heartbeat_E2E_CRC8: provided-interface=SRI_FZC_Heartbeat_E2E_CRC8
      PP_FZC_Heartbeat_E2E_DataID: provided-interface=SRI_FZC_Heartbeat_E2E_DataID
      PP_FZC_Heartbeat_ECU_ID: provided-interface=SRI_FZC_Heartbeat_ECU_ID
      PP_FZC_Heartbeat_FaultStatus: provided-interface=SRI_FZC_Heartbeat_FaultStatus
      PP_FZC_Heartbeat_OperatingMode: provided-interface=SRI_FZC_Heartbeat_OperatingMode
      PP_Lidar_Distance_E2E_AliveCounter: provided-interface=SRI_Lidar_Distance_E2E_AliveCounter
      PP_Lidar_Distance_E2E_CRC8: provided-interface=SRI_Lidar_Distance_E2E_CRC8
      PP_Lidar_Distance_E2E_DataID: provided-interface=SRI_Lidar_Distance_E2E_DataID
      PP_Lidar_Distance_ObstacleZone: provided-interface=SRI_Lidar_Distance_ObstacleZone
      PP_Lidar_Distance_Range_cm: provided-interface=SRI_Lidar_Distance_Range_cm
      PP_Lidar_Distance_SensorStatus: provided-interface=SRI_Lidar_Distance_SensorStatus
      PP_Lidar_Distance_SignalStrength: provided-interface=SRI_Lidar_Distance_SignalStrength
      PP_Motor_Cutoff_Req_E2E_AliveCounter: provided-interface=SRI_Motor_Cutoff_Req_E2E_AliveCounter
      PP_Motor_Cutoff_Req_E2E_CRC8: provided-interface=SRI_Motor_Cutoff_Req_E2E_CRC8
      PP_Motor_Cutoff_Req_E2E_DataID: provided-interface=SRI_Motor_Cutoff_Req_E2E_DataID
      PP_Motor_Cutoff_Req_Reason: provided-interface=SRI_Motor_Cutoff_Req_Reason
      PP_Motor_Cutoff_Req_RequestType: provided-interface=SRI_Motor_Cutoff_Req_RequestType
      PP_Steering_Status_ActualAngle: provided-interface=SRI_Steering_Status_ActualAngle
      PP_Steering_Status_CommandedAngle: provided-interface=SRI_Steering_Status_CommandedAngle
      PP_Steering_Status_E2E_AliveCounter: provided-interface=SRI_Steering_Status_E2E_AliveCounter
      PP_Steering_Status_E2E_CRC8: provided-interface=SRI_Steering_Status_E2E_CRC8
      PP_Steering_Status_E2E_DataID: provided-interface=SRI_Steering_Status_E2E_DataID
      PP_Steering_Status_ServoCurrent_mA: provided-interface=SRI_Steering_Status_ServoCurrent_mA
      PP_Steering_Status_SteerFaultStatus: provided-interface=SRI_Steering_Status_SteerFaultStatus
      PP_Steering_Status_SteerMode: provided-interface=SRI_Steering_Status_SteerMode
      PP_UDS_Resp_FZC_UDS_Data: provided-interface=SRI_UDS_Resp_FZC_UDS_Data
      PP_XCP_Resp_FZC_Data: provided-interface=SRI_XCP_Resp_FZC_Data
    41 x require port:
      RP_Brake_Command_BrakeForceCmd: required-interface=SRI_Brake_Command_BrakeForceCmd
      RP_Brake_Command_BrakeMode: required-interface=SRI_Brake_Command_BrakeMode
      RP_Brake_Command_E2E_AliveCounter: required-interface=SRI_Brake_Command_E2E_AliveCounter
      RP_Brake_Command_E2E_CRC8: required-interface=SRI_Brake_Command_E2E_CRC8
      RP_Brake_Command_E2E_DataID: required-interface=SRI_Brake_Command_E2E_DataID
      RP_Brake_Command_VehicleState: required-interface=SRI_Brake_Command_VehicleState
      RP_CVC_Heartbeat_E2E_AliveCounter: required-interface=SRI_CVC_Heartbeat_E2E_AliveCounter
      RP_CVC_Heartbeat_E2E_CRC8: required-interface=SRI_CVC_Heartbeat_E2E_CRC8
      RP_CVC_Heartbeat_E2E_DataID: required-interface=SRI_CVC_Heartbeat_E2E_DataID
      RP_CVC_Heartbeat_ECU_ID: required-interface=SRI_CVC_Heartbeat_ECU_ID
      RP_CVC_Heartbeat_FaultStatus: required-interface=SRI_CVC_Heartbeat_FaultStatus
      RP_CVC_Heartbeat_OperatingMode: required-interface=SRI_CVC_Heartbeat_OperatingMode
      RP_EStop_Broadcast_Active: required-interface=SRI_EStop_Broadcast_Active
      RP_EStop_Broadcast_E2E_AliveCounter: required-interface=SRI_EStop_Broadcast_E2E_AliveCounter
      RP_EStop_Broadcast_E2E_CRC8: required-interface=SRI_EStop_Broadcast_E2E_CRC8
      RP_EStop_Broadcast_E2E_DataID: required-interface=SRI_EStop_Broadcast_E2E_DataID
      RP_EStop_Broadcast_Source: required-interface=SRI_EStop_Broadcast_Source
      RP_FZC_Virtual_Sensors_BrakeCurrent_mA: required-interface=SRI_FZC_Virtual_Sensors_BrakeCurrent_mA
      RP_FZC_Virtual_Sensors_BrakePos_ADC: required-interface=SRI_FZC_Virtual_Sensors_BrakePos_ADC
      RP_FZC_Virtual_Sensors_SteerAngle_Raw: required-interface=SRI_FZC_Virtual_Sensors_SteerAngle_Raw
      RP_SC_Status_AliveCounter: required-interface=SRI_SC_Status_AliveCounter
      RP_SC_Status_CRC8: required-interface=SRI_SC_Status_CRC8
      RP_SC_Status_ECU_Health: required-interface=SRI_SC_Status_ECU_Health
      RP_SC_Status_FaultFlags: required-interface=SRI_SC_Status_FaultFlags
      RP_SC_Status_FaultReason: required-interface=SRI_SC_Status_FaultReason
      RP_SC_Status_Mode: required-interface=SRI_SC_Status_Mode
      RP_SC_Status_RelayEnergized: required-interface=SRI_SC_Status_RelayEnergized
      RP_Steer_Command_E2E_AliveCounter: required-interface=SRI_Steer_Command_E2E_AliveCounter
      RP_Steer_Command_E2E_CRC8: required-interface=SRI_Steer_Command_E2E_CRC8
      RP_Steer_Command_E2E_DataID: required-interface=SRI_Steer_Command_E2E_DataID
      RP_Steer_Command_SteerAngleCmd: required-interface=SRI_Steer_Command_SteerAngleCmd
      RP_Steer_Command_SteerRateLimit: required-interface=SRI_Steer_Command_SteerRateLimit
      RP_Steer_Command_VehicleState: required-interface=SRI_Steer_Command_VehicleState
      RP_UDS_Func_Request_UDS_Data: required-interface=SRI_UDS_Func_Request_UDS_Data
      RP_UDS_Phys_Req_FZC_UDS_Data: required-interface=SRI_UDS_Phys_Req_FZC_UDS_Data
      RP_Vehicle_State_E2E_AliveCounter: required-interface=SRI_Vehicle_State_E2E_AliveCounter
      RP_Vehicle_State_E2E_CRC8: required-interface=SRI_Vehicle_State_E2E_CRC8
      RP_Vehicle_State_E2E_DataID: required-interface=SRI_Vehicle_State_E2E_DataID
      RP_Vehicle_State_FaultMask: required-interface=SRI_Vehicle_State_FaultMask
      RP_Vehicle_State_Mode: required-interface=SRI_Vehicle_State_Mode
      RP_XCP_Req_FZC_Data: required-interface=SRI_XCP_Req_FZC_Data
    behavior FZC_Swc_FzcCom_IB
      init event IE_Swc_FzcCom_Init: start-on-event=Swc_FzcCom_Init
      timing event TE_Swc_FzcCom_Receive_10ms: start-on-event=Swc_FzcCom_Receive, period=0.01
      timing event TE_Swc_FzcCom_TransmitSchedule_10ms: start-on-event=Swc_FzcCom_TransmitSchedule, period=0.01
      runnable Swc_FzcCom_Init
      runnable Swc_FzcCom_Receive
      runnable Swc_FzcCom_TransmitSchedule
  application sw component type FZC_Swc_FzcDcm
    behavior FZC_Swc_FzcDcm_IB
      init event IE_Swc_FzcDcm_Init: start-on-event=Swc_FzcDcm_Init
      runnable Swc_FzcDcm_Init
  application sw component type FZC_Swc_FzcNvm
    behavior FZC_Swc_FzcNvm_IB
      init event IE_Swc_FzcNvm_Init: start-on-event=Swc_FzcNvm_Init
      runnable Swc_FzcNvm_Init
  application sw component type FZC_Swc_FzcSafety
    5 x provide port:
      PP_Motor_Cutoff_Req_E2E_AliveCounter: provided-interface=SRI_Motor_Cutoff_Req_E2E_AliveCounter
      PP_Motor_Cutoff_Req_E2E_CRC8: provided-interface=SRI_Motor_Cutoff_Req_E2E_CRC8
      PP_Motor_Cutoff_Req_E2E_DataID: provided-interface=SRI_Motor_Cutoff_Req_E2E_DataID
      PP_Motor_Cutoff_Req_Reason: provided-interface=SRI_Motor_Cutoff_Req_Reason
      PP_Motor_Cutoff_Req_RequestType: provided-interface=SRI_Motor_Cutoff_Req_RequestType
    behavior FZC_Swc_FzcSafety_IB
      init event IE_Swc_FzcSafety_Init: start-on-event=Swc_FzcSafety_Init
      timing event TE_Swc_FzcSafety_MainFunction_10ms: start-on-event=Swc_FzcSafety_MainFunction, period=0.01
      runnable Swc_FzcSafety_Init
      runnable Swc_FzcSafety_MainFunction
  application sw component type FZC_Swc_FzcScheduler
    behavior FZC_Swc_FzcScheduler_IB
      init event IE_Swc_FzcScheduler_Init: start-on-event=Swc_FzcScheduler_Init
      runnable Swc_FzcScheduler_Init
  application sw component type FZC_Swc_FzcSensorFeeder
    behavior FZC_Swc_FzcSensorFeeder_IB
      init event IE_Swc_FzcSensorFeeder_Init: start-on-event=Swc_FzcSensorFeeder_Init
      timing event TE_Swc_FzcSensorFeeder_MainFunction_10ms: start-on-event=Swc_FzcSensorFeeder_MainFunction, period=0.01
      runnable Swc_FzcSensorFeeder_Init
      runnable Swc_FzcSensorFeeder_MainFunction
  application sw component type FZC_Swc_Heartbeat
    11 x provide port:
      PP_Brake_Fault_E2E_AliveCounter: provided-interface=SRI_Brake_Fault_E2E_AliveCounter
      PP_Brake_Status_E2E_AliveCounter: provided-interface=SRI_Brake_Status_E2E_AliveCounter
      PP_FZC_Heartbeat_E2E_AliveCounter: provided-interface=SRI_FZC_Heartbeat_E2E_AliveCounter
      PP_FZC_Heartbeat_E2E_CRC8: provided-interface=SRI_FZC_Heartbeat_E2E_CRC8
      PP_FZC_Heartbeat_E2E_DataID: provided-interface=SRI_FZC_Heartbeat_E2E_DataID
      PP_FZC_Heartbeat_ECU_ID: provided-interface=SRI_FZC_Heartbeat_ECU_ID
      PP_FZC_Heartbeat_FaultStatus: provided-interface=SRI_FZC_Heartbeat_FaultStatus
      PP_FZC_Heartbeat_OperatingMode: provided-interface=SRI_FZC_Heartbeat_OperatingMode
      PP_Lidar_Distance_E2E_AliveCounter: provided-interface=SRI_Lidar_Distance_E2E_AliveCounter
      PP_Motor_Cutoff_Req_E2E_AliveCounter: provided-interface=SRI_Motor_Cutoff_Req_E2E_AliveCounter
      PP_Steering_Status_E2E_AliveCounter: provided-interface=SRI_Steering_Status_E2E_AliveCounter
    11 x require port:
      RP_Brake_Command_E2E_AliveCounter: required-interface=SRI_Brake_Command_E2E_AliveCounter
      RP_CVC_Heartbeat_E2E_AliveCounter: required-interface=SRI_CVC_Heartbeat_E2E_AliveCounter
      RP_CVC_Heartbeat_E2E_CRC8: required-interface=SRI_CVC_Heartbeat_E2E_CRC8
      RP_CVC_Heartbeat_E2E_DataID: required-interface=SRI_CVC_Heartbeat_E2E_DataID
      RP_CVC_Heartbeat_ECU_ID: required-interface=SRI_CVC_Heartbeat_ECU_ID
      RP_CVC_Heartbeat_FaultStatus: required-interface=SRI_CVC_Heartbeat_FaultStatus
      RP_CVC_Heartbeat_OperatingMode: required-interface=SRI_CVC_Heartbeat_OperatingMode
      RP_EStop_Broadcast_E2E_AliveCounter: required-interface=SRI_EStop_Broadcast_E2E_AliveCounter
      RP_SC_Status_AliveCounter: required-interface=SRI_SC_Status_AliveCounter
      RP_Steer_Command_E2E_AliveCounter: required-interface=SRI_Steer_Command_E2E_AliveCounter
      RP_Vehicle_State_E2E_AliveCounter: required-interface=SRI_Vehicle_State_E2E_AliveCounter
    behavior FZC_Swc_Heartbeat_IB
      timing event TE_Swc_Heartbeat_MainFunction_10ms: start-on-event=FZC_Swc_Heartbeat_IB/Swc_Heartbeat_MainFunction, period=0.01
      runnable Swc_Heartbeat_MainFunction
  application sw component type FZC_Swc_Lidar
    7 x provide port:
      PP_Lidar_Distance_E2E_AliveCounter: provided-interface=SRI_Lidar_Distance_E2E_AliveCounter
      PP_Lidar_Distance_E2E_CRC8: provided-interface=SRI_Lidar_Distance_E2E_CRC8
      PP_Lidar_Distance_E2E_DataID: provided-interface=SRI_Lidar_Distance_E2E_DataID
      PP_Lidar_Distance_ObstacleZone: provided-interface=SRI_Lidar_Distance_ObstacleZone
      PP_Lidar_Distance_Range_cm: provided-interface=SRI_Lidar_Distance_Range_cm
      PP_Lidar_Distance_SensorStatus: provided-interface=SRI_Lidar_Distance_SensorStatus
      PP_Lidar_Distance_SignalStrength: provided-interface=SRI_Lidar_Distance_SignalStrength
    behavior FZC_Swc_Lidar_IB
      init event IE_Swc_Lidar_Init: start-on-event=Swc_Lidar_Init
      timing event TE_Swc_Lidar_MainFunction_10ms: start-on-event=Swc_Lidar_MainFunction, period=0.01
      runnable Swc_Lidar_Init
      runnable Swc_Lidar_MainFunction
  application sw component type FZC_Swc_Steering
    8 x provide port:
      PP_Steering_Status_ActualAngle: provided-interface=SRI_Steering_Status_ActualAngle
      PP_Steering_Status_CommandedAngle: provided-interface=SRI_Steering_Status_CommandedAngle
      PP_Steering_Status_E2E_AliveCounter: provided-interface=SRI_Steering_Status_E2E_AliveCounter
      PP_Steering_Status_E2E_CRC8: provided-interface=SRI_Steering_Status_E2E_CRC8
      PP_Steering_Status_E2E_DataID: provided-interface=SRI_Steering_Status_E2E_DataID
      PP_Steering_Status_ServoCurrent_mA: provided-interface=SRI_Steering_Status_ServoCurrent_mA
      PP_Steering_Status_SteerFaultStatus: provided-interface=SRI_Steering_Status_SteerFaultStatus
      PP_Steering_Status_SteerMode: provided-interface=SRI_Steering_Status_SteerMode
    7 x require port:
      RP_FZC_Virtual_Sensors_SteerAngle_Raw: required-interface=SRI_FZC_Virtual_Sensors_SteerAngle_Raw
      RP_Steer_Command_E2E_AliveCounter: required-interface=SRI_Steer_Command_E2E_AliveCounter
      RP_Steer_Command_E2E_CRC8: required-interface=SRI_Steer_Command_E2E_CRC8
      RP_Steer_Command_E2E_DataID: required-interface=SRI_Steer_Command_E2E_DataID
      RP_Steer_Command_SteerAngleCmd: required-interface=SRI_Steer_Command_SteerAngleCmd
      RP_Steer_Command_SteerRateLimit: required-interface=SRI_Steer_Command_SteerRateLimit
      RP_Steer_Command_VehicleState: required-interface=SRI_Steer_Command_VehicleState
    behavior FZC_Swc_Steering_IB
      init event IE_Swc_Steering_Init: start-on-event=Swc_Steering_Init
      timing event TE_Swc_Steering_MainFunction_10ms: start-on-event=Swc_Steering_MainFunction, period=0.01
      runnable Swc_Steering_Init
      runnable Swc_Steering_MainFunction
package /Taktflow/SWCs/ICU
  application sw component type ICU_Swc_Dashboard
    require port RP_Motor_Status_MotorSpeed_RPM: required-interface=SRI_Motor_Status_MotorSpeed_RPM
    behavior ICU_Swc_Dashboard_IB
      timing event TE_Swc_Dashboard_50ms_50ms: start-on-event=Swc_Dashboard_50ms, period=0.05
      runnable Swc_Dashboard_50ms
  application sw component type ICU_Swc_DtcDisplay
    15 x require port:
      RP_Brake_Status_BrakeFaultStatus: required-interface=SRI_Brake_Status_BrakeFaultStatus
      RP_CVC_Heartbeat_FaultStatus: required-interface=SRI_CVC_Heartbeat_FaultStatus
      RP_DTC_Broadcast_ECU_Source: required-interface=SRI_DTC_Broadcast_ECU_Source
      RP_DTC_Broadcast_FreezeFrame0: required-interface=SRI_DTC_Broadcast_FreezeFrame0
      RP_DTC_Broadcast_FreezeFrame1: required-interface=SRI_DTC_Broadcast_FreezeFrame1
      RP_DTC_Broadcast_Number: required-interface=SRI_DTC_Broadcast_Number
      RP_DTC_Broadcast_OccurrenceCount: required-interface=SRI_DTC_Broadcast_OccurrenceCount
      RP_DTC_Broadcast_Status: required-interface=SRI_DTC_Broadcast_Status
      RP_FZC_Heartbeat_FaultStatus: required-interface=SRI_FZC_Heartbeat_FaultStatus
      RP_Motor_Status_MotorFaultStatus: required-interface=SRI_Motor_Status_MotorFaultStatus
      RP_RZC_Heartbeat_FaultStatus: required-interface=SRI_RZC_Heartbeat_FaultStatus
      RP_SC_Status_FaultFlags: required-interface=SRI_SC_Status_FaultFlags
      RP_SC_Status_FaultReason: required-interface=SRI_SC_Status_FaultReason
      RP_Steering_Status_SteerFaultStatus: required-interface=SRI_Steering_Status_SteerFaultStatus
      RP_Vehicle_State_FaultMask: required-interface=SRI_Vehicle_State_FaultMask
    behavior ICU_Swc_DtcDisplay_IB
      timing event TE_Swc_DtcDisplay_50ms_50ms: start-on-event=Swc_DtcDisplay_50ms, period=0.05
      init event IE_Swc_DtcDisplay_Init: start-on-event=Swc_DtcDisplay_Init
      runnable Swc_DtcDisplay_50ms
      runnable Swc_DtcDisplay_Init
package /Taktflow/SWCs/RZC
  application sw component type RZC_Swc_Battery
    5 x provide port:
      PP_Battery_Status_BatteryVoltage_mV: provided-interface=SRI_Battery_Status_BatteryVoltage_mV
      PP_Battery_Status_E2E_AliveCounter: provided-interface=SRI_Battery_Status_E2E_AliveCounter
      PP_Battery_Status_E2E_CRC8: provided-interface=SRI_Battery_Status_E2E_CRC8
      PP_Battery_Status_E2E_DataID: provided-interface=SRI_Battery_Status_E2E_DataID
      PP_Battery_Status_Level: provided-interface=SRI_Battery_Status_Level
    require port RP_RZC_Virtual_Sensors_BattVoltage_mV: required-interface=SRI_RZC_Virtual_Sensors_BattVoltage_mV
    behavior RZC_Swc_Battery_IB
      init event IE_Swc_Battery_Init: start-on-event=Swc_Battery_Init
      timing event TE_Swc_Battery_MainFunction_100ms: start-on-event=Swc_Battery_MainFunction, period=0.1
      runnable Swc_Battery_Init
      runnable Swc_Battery_MainFunction
  application sw component type RZC_Swc_CurrentMonitor
    8 x provide port:
      PP_Motor_Current_DirIsReverse: provided-interface=SRI_Motor_Current_DirIsReverse
      PP_Motor_Current_E2E_AliveCounter: provided-interface=SRI_Motor_Current_E2E_AliveCounter
      PP_Motor_Current_E2E_CRC8: provided-interface=SRI_Motor_Current_E2E_CRC8
      PP_Motor_Current_E2E_DataID: provided-interface=SRI_Motor_Current_E2E_DataID
      PP_Motor_Current_MotorEnable: provided-interface=SRI_Motor_Current_MotorEnable
      PP_Motor_Current_OvercurrentFlag: provided-interface=SRI_Motor_Current_OvercurrentFlag
      PP_Motor_Current_Phase_mA: provided-interface=SRI_Motor_Current_Phase_mA
      PP_Motor_Current_TorqueEcho: provided-interface=SRI_Motor_Current_TorqueEcho
    require port RP_RZC_Virtual_Sensors_MotorCurrent_mA: required-interface=SRI_RZC_Virtual_Sensors_MotorCurrent_mA
    behavior RZC_Swc_CurrentMonitor_IB
      init event IE_Swc_CurrentMonitor_Init: start-on-event=Swc_CurrentMonitor_Init
      timing event TE_Swc_CurrentMonitor_MainFunction_1ms: start-on-event=Swc_CurrentMonitor_MainFunction, period=0.001
      runnable Swc_CurrentMonitor_Init
      runnable Swc_CurrentMonitor_MainFunction
  application sw component type RZC_Swc_Encoder
    provide port PP_Motor_Status_MotorSpeed_RPM: provided-interface=SRI_Motor_Status_MotorSpeed_RPM
    require port RP_RZC_Virtual_Sensors_MotorSpeed_RPM: required-interface=SRI_RZC_Virtual_Sensors_MotorSpeed_RPM
    require port RP_Vehicle_State_SpeedLimit: required-interface=SRI_Vehicle_State_SpeedLimit
    behavior RZC_Swc_Encoder_IB
      init event IE_Swc_Encoder_Init: start-on-event=Swc_Encoder_Init
      timing event TE_Swc_Encoder_MainFunction_10ms: start-on-event=Swc_Encoder_MainFunction, period=0.01
      runnable Swc_Encoder_Init
      runnable Swc_Encoder_MainFunction
  application sw component type RZC_Swc_Heartbeat
    10 x provide port:
      PP_Battery_Status_E2E_AliveCounter: provided-interface=SRI_Battery_Status_E2E_AliveCounter
      PP_Motor_Current_E2E_AliveCounter: provided-interface=SRI_Motor_Current_E2E_AliveCounter
      PP_Motor_Status_E2E_AliveCounter: provided-interface=SRI_Motor_Status_E2E_AliveCounter
      PP_Motor_Temperature_E2E_AliveCounter: provided-interface=SRI_Motor_Temperature_E2E_AliveCounter
      PP_RZC_Heartbeat_E2E_AliveCounter: provided-interface=SRI_RZC_Heartbeat_E2E_AliveCounter
      PP_RZC_Heartbeat_E2E_CRC8: provided-interface=SRI_RZC_Heartbeat_E2E_CRC8
      PP_RZC_Heartbeat_E2E_DataID: provided-interface=SRI_RZC_Heartbeat_E2E_DataID
      PP_RZC_Heartbeat_ECU_ID: provided-interface=SRI_RZC_Heartbeat_ECU_ID
      PP_RZC_Heartbeat_FaultStatus: provided-interface=SRI_RZC_Heartbeat_FaultStatus
      PP_RZC_Heartbeat_OperatingMode: provided-interface=SRI_RZC_Heartbeat_OperatingMode
    10 x require port:
      RP_CVC_Heartbeat_E2E_AliveCounter: required-interface=SRI_CVC_Heartbeat_E2E_AliveCounter
      RP_CVC_Heartbeat_E2E_CRC8: required-interface=SRI_CVC_Heartbeat_E2E_CRC8
      RP_CVC_Heartbeat_E2E_DataID: required-interface=SRI_CVC_Heartbeat_E2E_DataID
      RP_CVC_Heartbeat_ECU_ID: required-interface=SRI_CVC_Heartbeat_ECU_ID
      RP_CVC_Heartbeat_FaultStatus: required-interface=SRI_CVC_Heartbeat_FaultStatus
      RP_CVC_Heartbeat_OperatingMode: required-interface=SRI_CVC_Heartbeat_OperatingMode
      RP_EStop_Broadcast_E2E_AliveCounter: required-interface=SRI_EStop_Broadcast_E2E_AliveCounter
      RP_SC_Status_AliveCounter: required-interface=SRI_SC_Status_AliveCounter
      RP_Torque_Request_E2E_AliveCounter: required-interface=SRI_Torque_Request_E2E_AliveCounter
      RP_Vehicle_State_E2E_AliveCounter: required-interface=SRI_Vehicle_State_E2E_AliveCounter
    behavior RZC_Swc_Heartbeat_IB
      timing event TE_Swc_Heartbeat_MainFunction_50ms: start-on-event=RZC_Swc_Heartbeat_IB/Swc_Heartbeat_MainFunction, period=0.05
      runnable Swc_Heartbeat_MainFunction
  application sw component type RZC_Swc_Motor
    22 x provide port:
      PP_Motor_Current_DirIsReverse: provided-interface=SRI_Motor_Current_DirIsReverse
      PP_Motor_Current_E2E_AliveCounter: provided-interface=SRI_Motor_Current_E2E_AliveCounter
      PP_Motor_Current_E2E_CRC8: provided-interface=SRI_Motor_Current_E2E_CRC8
      PP_Motor_Current_E2E_DataID: provided-interface=SRI_Motor_Current_E2E_DataID
      PP_Motor_Current_MotorEnable: provided-interface=SRI_Motor_Current_MotorEnable
      PP_Motor_Current_OvercurrentFlag: provided-interface=SRI_Motor_Current_OvercurrentFlag
      PP_Motor_Current_Phase_mA: provided-interface=SRI_Motor_Current_Phase_mA
      PP_Motor_Current_TorqueEcho: provided-interface=SRI_Motor_Current_TorqueEcho
      PP_Motor_Status_E2E_AliveCounter: provided-interface=SRI_Motor_Status_E2E_AliveCounter
      PP_Motor_Status_E2E_CRC8: provided-interface=SRI_Motor_Status_E2E_CRC8
      PP_Motor_Status_E2E_DataID: provided-interface=SRI_Motor_Status_E2E_DataID
      PP_Motor_Status_MotorDirection: provided-interface=SRI_Motor_Status_MotorDirection
      PP_Motor_Status_MotorEnable: provided-interface=SRI_Motor_Status_MotorEnable
      PP_Motor_Status_MotorFaultStatus: provided-interface=SRI_Motor_Status_MotorFaultStatus
      PP_Motor_Status_MotorSpeed_RPM: provided-interface=SRI_Motor_Status_MotorSpeed_RPM
      PP_Motor_Status_TorqueEcho: provided-interface=SRI_Motor_Status_TorqueEcho
      PP_Motor_Temperature_DeratingPercent: provided-interface=SRI_Motor_Temperature_DeratingPercent
      PP_Motor_Temperature_E2E_AliveCounter: provided-interface=SRI_Motor_Temperature_E2E_AliveCounter
      PP_Motor_Temperature_E2E_CRC8: provided-interface=SRI_Motor_Temperature_E2E_CRC8
      PP_Motor_Temperature_E2E_DataID: provided-interface=SRI_Motor_Temperature_E2E_DataID
      PP_Motor_Temperature_WindingTemp1_C: provided-interface=SRI_Motor_Temperature_WindingTemp1_C
      PP_Motor_Temperature_WindingTemp2_C: provided-interface=SRI_Motor_Temperature_WindingTemp2_C
    12 x require port:
      RP_RZC_Virtual_Sensors_MotorCurrent_mA: required-interface=SRI_RZC_Virtual_Sensors_MotorCurrent_mA
      RP_RZC_Virtual_Sensors_MotorSpeed_RPM: required-interface=SRI_RZC_Virtual_Sensors_MotorSpeed_RPM
      RP_RZC_Virtual_Sensors_MotorTemp_dC: required-interface=SRI_RZC_Virtual_Sensors_MotorTemp_dC
      RP_Torque_Request_Command_pct: required-interface=SRI_Torque_Request_Command_pct
      RP_Torque_Request_Direction: required-interface=SRI_Torque_Request_Direction
      RP_Torque_Request_E2E_AliveCounter: required-interface=SRI_Torque_Request_E2E_AliveCounter
      RP_Torque_Request_E2E_CRC8: required-interface=SRI_Torque_Request_E2E_CRC8
      RP_Torque_Request_E2E_DataID: required-interface=SRI_Torque_Request_E2E_DataID
      RP_Torque_Request_PedalFault: required-interface=SRI_Torque_Request_PedalFault
      RP_Torque_Request_PedalPosition1: required-interface=SRI_Torque_Request_PedalPosition1
      RP_Torque_Request_PedalPosition2: required-interface=SRI_Torque_Request_PedalPosition2
      RP_Vehicle_State_TorqueLimit: required-interface=SRI_Vehicle_State_TorqueLimit
    behavior RZC_Swc_Motor_IB
      init event IE_Swc_Motor_Init: start-on-event=Swc_Motor_Init
      timing event TE_Swc_Motor_MainFunction_10ms: start-on-event=Swc_Motor_MainFunction, period=0.01
      runnable Swc_Motor_Init
      runnable Swc_Motor_MainFunction
  application sw component type RZC_Swc_RzcCom
    35 x provide port:
      PP_Battery_Status_BatteryVoltage_mV: provided-interface=SRI_Battery_Status_BatteryVoltage_mV
      PP_Battery_Status_E2E_AliveCounter: provided-interface=SRI_Battery_Status_E2E_AliveCounter
      PP_Battery_Status_E2E_CRC8: provided-interface=SRI_Battery_Status_E2E_CRC8
      PP_Battery_Status_E2E_DataID: provided-interface=SRI_Battery_Status_E2E_DataID
      PP_Battery_Status_Level: provided-interface=SRI_Battery_Status_Level
      PP_Motor_Current_DirIsReverse: provided-interface=SRI_Motor_Current_DirIsReverse
      PP_Motor_Current_E2E_AliveCounter: provided-interface=SRI_Motor_Current_E2E_AliveCounter
      PP_Motor_Current_E2E_CRC8: provided-interface=SRI_Motor_Current_E2E_CRC8
      PP_Motor_Current_E2E_DataID: provided-interface=SRI_Motor_Current_E2E_DataID
      PP_Motor_Current_MotorEnable: provided-interface=SRI_Motor_Current_MotorEnable
      PP_Motor_Current_OvercurrentFlag: provided-interface=SRI_Motor_Current_OvercurrentFlag
      PP_Motor_Current_Phase_mA: provided-interface=SRI_Motor_Current_Phase_mA
      PP_Motor_Current_TorqueEcho: provided-interface=SRI_Motor_Current_TorqueEcho
      PP_Motor_Status_E2E_AliveCounter: provided-interface=SRI_Motor_Status_E2E_AliveCounter
      PP_Motor_Status_E2E_CRC8: provided-interface=SRI_Motor_Status_E2E_CRC8
      PP_Motor_Status_E2E_DataID: provided-interface=SRI_Motor_Status_E2E_DataID
      PP_Motor_Status_MotorDirection: provided-interface=SRI_Motor_Status_MotorDirection
      PP_Motor_Status_MotorEnable: provided-interface=SRI_Motor_Status_MotorEnable
      PP_Motor_Status_MotorFaultStatus: provided-interface=SRI_Motor_Status_MotorFaultStatus
      PP_Motor_Status_MotorSpeed_RPM: provided-interface=SRI_Motor_Status_MotorSpeed_RPM
      PP_Motor_Status_TorqueEcho: provided-interface=SRI_Motor_Status_TorqueEcho
      PP_Motor_Temperature_DeratingPercent: provided-interface=SRI_Motor_Temperature_DeratingPercent
      PP_Motor_Temperature_E2E_AliveCounter: provided-interface=SRI_Motor_Temperature_E2E_AliveCounter
      PP_Motor_Temperature_E2E_CRC8: provided-interface=SRI_Motor_Temperature_E2E_CRC8
      PP_Motor_Temperature_E2E_DataID: provided-interface=SRI_Motor_Temperature_E2E_DataID
      PP_Motor_Temperature_WindingTemp1_C: provided-interface=SRI_Motor_Temperature_WindingTemp1_C
      PP_Motor_Temperature_WindingTemp2_C: provided-interface=SRI_Motor_Temperature_WindingTemp2_C
      PP_RZC_Heartbeat_E2E_AliveCounter: provided-interface=SRI_RZC_Heartbeat_E2E_AliveCounter
      PP_RZC_Heartbeat_E2E_CRC8: provided-interface=SRI_RZC_Heartbeat_E2E_CRC8
      PP_RZC_Heartbeat_E2E_DataID: provided-interface=SRI_RZC_Heartbeat_E2E_DataID
      PP_RZC_Heartbeat_ECU_ID: provided-interface=SRI_RZC_Heartbeat_ECU_ID
      PP_RZC_Heartbeat_FaultStatus: provided-interface=SRI_RZC_Heartbeat_FaultStatus
      PP_RZC_Heartbeat_OperatingMode: provided-interface=SRI_RZC_Heartbeat_OperatingMode
      PP_UDS_Resp_RZC_UDS_Data: provided-interface=SRI_UDS_Resp_RZC_UDS_Data
      PP_XCP_Resp_RZC_Data: provided-interface=SRI_XCP_Resp_RZC_Data
    40 x require port:
      RP_CVC_Heartbeat_E2E_AliveCounter: required-interface=SRI_CVC_Heartbeat_E2E_AliveCounter
      RP_CVC_Heartbeat_E2E_CRC8: required-interface=SRI_CVC_Heartbeat_E2E_CRC8
      RP_CVC_Heartbeat_E2E_DataID: required-interface=SRI_CVC_Heartbeat_E2E_DataID
      RP_CVC_Heartbeat_ECU_ID: required-interface=SRI_CVC_Heartbeat_ECU_ID
      RP_CVC_Heartbeat_FaultStatus: required-interface=SRI_CVC_Heartbeat_FaultStatus
      RP_CVC_Heartbeat_OperatingMode: required-interface=SRI_CVC_Heartbeat_OperatingMode
      RP_EStop_Broadcast_Active: required-interface=SRI_EStop_Broadcast_Active
      RP_EStop_Broadcast_E2E_AliveCounter: required-interface=SRI_EStop_Broadcast_E2E_AliveCounter
      RP_EStop_Broadcast_E2E_CRC8: required-interface=SRI_EStop_Broadcast_E2E_CRC8
      RP_EStop_Broadcast_E2E_DataID: required-interface=SRI_EStop_Broadcast_E2E_DataID
      RP_EStop_Broadcast_Source: required-interface=SRI_EStop_Broadcast_Source
      RP_RZC_Virtual_Sensors_BattVoltage_mV: required-interface=SRI_RZC_Virtual_Sensors_BattVoltage_mV
      RP_RZC_Virtual_Sensors_MotorCurrent_mA: required-interface=SRI_RZC_Virtual_Sensors_MotorCurrent_mA
      RP_RZC_Virtual_Sensors_MotorSpeed_RPM: required-interface=SRI_RZC_Virtual_Sensors_MotorSpeed_RPM
      RP_RZC_Virtual_Sensors_MotorTemp_dC: required-interface=SRI_RZC_Virtual_Sensors_MotorTemp_dC
      RP_SC_Status_AliveCounter: required-interface=SRI_SC_Status_AliveCounter
      RP_SC_Status_CRC8: required-interface=SRI_SC_Status_CRC8
      RP_SC_Status_ECU_Health: required-interface=SRI_SC_Status_ECU_Health
      RP_SC_Status_FaultFlags: required-interface=SRI_SC_Status_FaultFlags
      RP_SC_Status_FaultReason: required-interface=SRI_SC_Status_FaultReason
      RP_SC_Status_Mode: required-interface=SRI_SC_Status_Mode
      RP_SC_Status_RelayEnergized: required-interface=SRI_SC_Status_RelayEnergized
      RP_Torque_Request_Command_pct: required-interface=SRI_Torque_Request_Command_pct
      RP_Torque_Request_Direction: required-interface=SRI_Torque_Request_Direction
      RP_Torque_Request_E2E_AliveCounter: required-interface=SRI_Torque_Request_E2E_AliveCounter
      RP_Torque_Request_E2E_CRC8: required-interface=SRI_Torque_Request_E2E_CRC8
      RP_Torque_Request_E2E_DataID: required-interface=SRI_Torque_Request_E2E_DataID
      RP_Torque_Request_PedalFault: required-interface=SRI_Torque_Request_PedalFault
      RP_Torque_Request_PedalPosition1: required-interface=SRI_Torque_Request_PedalPosition1
      RP_Torque_Request_PedalPosition2: required-interface=SRI_Torque_Request_PedalPosition2
      RP_UDS_Func_Request_UDS_Data: required-interface=SRI_UDS_Func_Request_UDS_Data
      RP_UDS_Phys_Req_RZC_UDS_Data: required-interface=SRI_UDS_Phys_Req_RZC_UDS_Data
      RP_Vehicle_State_E2E_AliveCounter: required-interface=SRI_Vehicle_State_E2E_AliveCounter
      RP_Vehicle_State_E2E_CRC8: required-interface=SRI_Vehicle_State_E2E_CRC8
      RP_Vehicle_State_E2E_DataID: required-interface=SRI_Vehicle_State_E2E_DataID
      RP_Vehicle_State_FaultMask: required-interface=SRI_Vehicle_State_FaultMask
      RP_Vehicle_State_Mode: required-interface=SRI_Vehicle_State_Mode
      RP_Vehicle_State_SpeedLimit: required-interface=SRI_Vehicle_State_SpeedLimit
      RP_Vehicle_State_TorqueLimit: required-interface=SRI_Vehicle_State_TorqueLimit
      RP_XCP_Req_RZC_Data: required-interface=SRI_XCP_Req_RZC_Data
    behavior RZC_Swc_RzcCom_IB
      init event IE_Swc_RzcCom_Init: start-on-event=Swc_RzcCom_Init
      timing event TE_Swc_RzcCom_Receive_10ms: start-on-event=Swc_RzcCom_Receive, period=0.01
      timing event TE_Swc_RzcCom_TransmitSchedule_10ms: start-on-event=Swc_RzcCom_TransmitSchedule, period=0.01
      runnable Swc_RzcCom_Init
      runnable Swc_RzcCom_Receive
      runnable Swc_RzcCom_TransmitSchedule
  application sw component type RZC_Swc_RzcDcm
    behavior RZC_Swc_RzcDcm_IB
      init event IE_Swc_RzcDcm_Init: start-on-event=Swc_RzcDcm_Init
      runnable Swc_RzcDcm_Init
  application sw component type RZC_Swc_RzcNvm
    behavior RZC_Swc_RzcNvm_IB
      init event IE_Swc_RzcNvm_Init: start-on-event=Swc_RzcNvm_Init
      runnable Swc_RzcNvm_Init
  application sw component type RZC_Swc_RzcSafety
    behavior RZC_Swc_RzcSafety_IB
      init event IE_Swc_RzcSafety_Init: start-on-event=Swc_RzcSafety_Init
      timing event TE_Swc_RzcSafety_MainFunction_100ms: start-on-event=Swc_RzcSafety_MainFunction, period=0.1
      runnable Swc_RzcSafety_Init
      runnable Swc_RzcSafety_MainFunction
  application sw component type RZC_Swc_RzcScheduler
    behavior RZC_Swc_RzcScheduler_IB
      init event IE_Swc_RzcScheduler_Init: start-on-event=Swc_RzcScheduler_Init
      runnable Swc_RzcScheduler_Init
  application sw component type RZC_Swc_RzcSelfTest
    behavior RZC_Swc_RzcSelfTest_IB
      init event IE_Swc_RzcSelfTest_Init: start-on-event=Swc_RzcSelfTest_Init
      runnable Swc_RzcSelfTest_Init
  application sw component type RZC_Swc_RzcSensorFeeder
    behavior RZC_Swc_RzcSensorFeeder_IB
      init event IE_Swc_RzcSensorFeeder_Init: start-on-event=Swc_RzcSensorFeeder_Init
      timing event TE_Swc_RzcSensorFeeder_MainFunction_10ms: start-on-event=Swc_RzcSensorFeeder_MainFunction, period=0.01
      runnable Swc_RzcSensorFeeder_Init
      runnable Swc_RzcSensorFeeder_MainFunction
  application sw component type RZC_Swc_TempMonitor
    6 x provide port:
      PP_Motor_Temperature_DeratingPercent: provided-interface=SRI_Motor_Temperature_DeratingPercent
      PP_Motor_Temperature_E2E_AliveCounter: provided-interface=SRI_Motor_Temperature_E2E_AliveCounter
      PP_Motor_Temperature_E2E_CRC8: provided-interface=SRI_Motor_Temperature_E2E_CRC8
      PP_Motor_Temperature_E2E_DataID: provided-interface=SRI_Motor_Temperature_E2E_DataID
      PP_Motor_Temperature_WindingTemp1_C: provided-interface=SRI_Motor_Temperature_WindingTemp1_C
      PP_Motor_Temperature_WindingTemp2_C: provided-interface=SRI_Motor_Temperature_WindingTemp2_C
    require port RP_RZC_Virtual_Sensors_MotorTemp_dC: required-interface=SRI_RZC_Virtual_Sensors_MotorTemp_dC
    behavior RZC_Swc_TempMonitor_IB
      init event IE_Swc_TempMonitor_Init: start-on-event=Swc_TempMonitor_Init
      timing event TE_Swc_TempMonitor_MainFunction_100ms: start-on-event=Swc_TempMonitor_MainFunction, period=0.1
      runnable Swc_TempMonitor_Init
      runnable Swc_TempMonitor_MainFunction
package /Taktflow/SWCs/TCU
  application sw component type TCU_Swc_DataAggregator
    behavior TCU_Swc_DataAggregator_IB
  application sw component type TCU_Swc_DtcStore
    6 x require port:
      RP_DTC_Broadcast_ECU_Source: required-interface=SRI_DTC_Broadcast_ECU_Source
      RP_DTC_Broadcast_FreezeFrame0: required-interface=SRI_DTC_Broadcast_FreezeFrame0
      RP_DTC_Broadcast_FreezeFrame1: required-interface=SRI_DTC_Broadcast_FreezeFrame1
      RP_DTC_Broadcast_Number: required-interface=SRI_DTC_Broadcast_Number
      RP_DTC_Broadcast_OccurrenceCount: required-interface=SRI_DTC_Broadcast_OccurrenceCount
      RP_DTC_Broadcast_Status: required-interface=SRI_DTC_Broadcast_Status
    behavior TCU_Swc_DtcStore_IB
      init event IE_Swc_DtcStore_Init: start-on-event=Swc_DtcStore_Init
      runnable Swc_DtcStore_Init
  application sw component type TCU_Swc_Obd2Pids
    behavior TCU_Swc_Obd2Pids_IB
      init event IE_Swc_Obd2Pids_Init: start-on-event=Swc_Obd2Pids_Init
      runnable Swc_Obd2Pids_Init
  application sw component type TCU_Swc_UdsServer
    provide port PP_UDS_Resp_TCU_UDS_Data: provided-interface=SRI_UDS_Resp_TCU_UDS_Data
    require port RP_UDS_Func_Request_UDS_Data: required-interface=SRI_UDS_Func_Request_UDS_Data
    require port RP_UDS_Phys_Req_TCU_UDS_Data: required-interface=SRI_UDS_Phys_Req_TCU_UDS_Data
    behavior TCU_Swc_UdsServer_IB
      init event IE_Swc_UdsServer_Init: start-on-event=Swc_UdsServer_Init
      runnable Swc_UdsServer_Init
